[part 6 of 22: package /Cluster]
AUTOSAR XML (schema 4-3-0)
package /Cluster  (continued)
  can cluster E3V_K2CANFD: baudrate=500000, protocol-name=CAN, protocol-version=2.0, bus-off-recovery={bor-counter-l-1-to-l-2=1, bor-time-l-1=0.05, bor-time-l-2=0.2}, can-fd-baudrate=500000  (continued)
    can physical channel CHNL: comm-connectors=CN_E3V_K2CANFD  (continued)
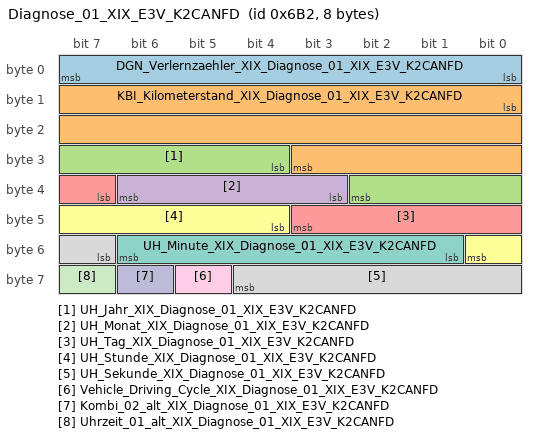
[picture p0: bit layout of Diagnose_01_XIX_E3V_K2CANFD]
      frame Diagnose_01_XIX_E3V_K2CANFD: id 0x6B2, to SAM, frame-length=8, can-addressing-mode=STANDARD, can-frame-rx-behavior=CAN-FD, can-frame-tx-behavior=CAN-FD
        pdu Diagnose_01_XIX_E3V_K2CANFD: length=8, transmission-mode-true-timing=cyclic-timing={time-offset=0.0, time-period=1.0}, unused-bit-pattern=0
          signal DGN_Verlernzaehler_XIX_Diagnose_01_XIX_E3V_K2CANFD: start 0, 8 bit, little-endian, data-type-policy=OVERRIDE, i-signal-type=PRIMITIVE, init-value=0, base-type=BT_DGN_Verlernzaehler, compu {phys=raw for raw 0..254, 255=Cxff_ungueltiger_Zaehlerstand_oder_kein_gueltiger_Fahrzyklus (CM_DGN_Verlernzaehler_Cxff_ungueltiger_Zaehlerstand_oder_kein_gueltiger_Fahrzyklus) (ungültiger Zählerstand oder kein gültiger Fahrzyklus)}, range phys 0..254, raw 0..255, transfer-property=PENDING, to SAM(timeout 5 s)  # wrap around 254 --> 0
          signal KBI_Kilometerstand_XIX_Diagnose_01_XIX_E3V_K2CANFD: start 8, 20 bit, little-endian, data-type-policy=OVERRIDE, i-signal-type=PRIMITIVE, init-value=1048574, base-type=BT_KBI_Kilometerstand, invalid-value=Invalid_KBI_Kilometerstand_XIX_Diagnose_01_XIX_E3V_K2CANFD:1048575, compu {phys=raw for raw 0..1048573, 1048574=Cxffffe_Init (CM_KBI_Kilometerstand_Cxffffe_Init), 1048575=Cxfffff_Fehler (CM_KBI_Kilometerstand_Cxfffff_Fehler); unit Unit_KiloMeter}, range phys 0..1048573 Unit_KiloMeter, raw 0..1048575, unit=Unit_KiloMeter, transfer-property=PENDING, to SAM(timeout 5 s)  # Fehler wird ausgegeben, falls Kilometerstand nicht restaurierbar
          signal UH_Jahr_XIX_Diagnose_01_XIX_E3V_K2CANFD: start 28, 7 bit, little-endian, data-type-policy=OVERRIDE, i-signal-type=PRIMITIVE, init-value=0, base-type=BT_UH_Jahr, compu {phys=raw+2000 for raw 0..127; unit Unit_Year}, range phys 2000..2127 Unit_Year, raw 0..127, unit=Unit_Year, transfer-property=PENDING, to SAM(timeout 5 s)
          signal UH_Monat_XIX_Diagnose_01_XIX_E3V_K2CANFD: start 35, 4 bit, little-endian, data-type-policy=OVERRIDE, i-signal-type=PRIMITIVE, init-value=0, base-type=BT_UH_Monat, invalid-value=Invalid_UH_Monat_XIX_Diagnose_01_XIX_E3V_K2CANFD:15, compu {0=Cx0_Init (CM_UH_Monat_Cx0_Init), phys=raw for raw 1..12, 14=Cxe_Relatives_Datum (CM_UH_Monat_Cxe_Relatives_Datum), 15=Cxf_Fehler (CM_UH_Monat_Cxf_Fehler); unit Unit_Month}, range phys 1..12 Unit_Month, raw 0..15, unit=Unit_Month, transfer-property=PENDING, to SAM(timeout 5 s)  # 0x0D, 0xF = Werte ungültig 0x0E = Relatives Datum (nur VW)
          signal UH_Tag_XIX_Diagnose_01_XIX_E3V_K2CANFD: start 39, 5 bit, little-endian, data-type-policy=OVERRIDE, i-signal-type=PRIMITIVE, init-value=0, base-type=BT_UH_Tag, compu {0=Cx0_Init (CM_UH_Tag_Cx0_Init), phys=raw for raw 1..31; unit Unit_Day}, range phys 1..31 Unit_Day, raw 0..31, unit=Unit_Day, transfer-property=PENDING, to SAM(timeout 5 s)  # 0x0: reserviert bei VW
          signal UH_Stunde_XIX_Diagnose_01_XIX_E3V_K2CANFD: start 44, 5 bit, little-endian, data-type-policy=OVERRIDE, i-signal-type=PRIMITIVE, init-value=0, base-type=BT_UH_Stunde, compu {phys=raw for raw 0..23; unit Unit_Hours}, range phys 0..23 Unit_Hours, raw 0..23, unit=Unit_Hours, transfer-property=PENDING, to SAM(timeout 5 s)  # 0x18 - 0x1F = Werte ungültig
          signal UH_Minute_XIX_Diagnose_01_XIX_E3V_K2CANFD: start 49, 6 bit, little-endian, data-type-policy=OVERRIDE, i-signal-type=PRIMITIVE, init-value=0, base-type=BT_UH_Minute, compu {phys=raw for raw 0..59; unit Unit_Minut}, range phys 0..59 Unit_Minut, raw 0..59, unit=Unit_Minut, transfer-property=PENDING, to SAM(timeout 5 s)  # 0x3C- 0x3f = Werte ungültig
          signal UH_Sekunde_XIX_Diagnose_01_XIX_E3V_K2CANFD: start 55, 6 bit, little-endian, data-type-policy=OVERRIDE, i-signal-type=PRIMITIVE, init-value=0, base-type=BT_UH_Sekunde, compu {phys=raw for raw 0..59; unit Unit_Secon}, range phys 0..59 Unit_Secon, raw 0..59, unit=Unit_Secon, transfer-property=PENDING, to SAM(timeout 5 s)  # 0x3C- 0x3f = Werte ungültig
          signal Vehicle_Driving_Cycle_XIX_Diagnose_01_XIX_E3V_K2CANFD: start 61, 1 bit, little-endian, data-type-policy=OVERRIDE, i-signal-type=PRIMITIVE, init-value=0, base-type=BT_Vehicle_Driving_Cycle, compu {0=Cx0_kein_Driving_Cycle_erkannt (CM_Vehicle_Driving_Cycle_Cx0_kein_Driving_Cycle_erkannt), 1=Cx1_Driving_Cycle_erkannt (CM_Vehicle_Driving_Cycle_Cx1_Driving_Cycle_erkannt)}, range raw 0..1, transfer-property=PENDING  # Optimierung der Inbetriebnahme von Steuergeräten in einem Teilverbau in der Produktion. Siehe VW80114. Signal bildet (durch eine Gateway-Funktion) den Inhalt des Signals OBD_Driving_Cycle ab.
          signal Kombi_02_alt_XIX_Diagnose_01_XIX_E3V_K2CANFD: start 62, 1 bit, little-endian, data-type-policy=OVERRIDE, i-signal-type=PRIMITIVE, init-value=1, base-type=BT_Kombi_02_alt, compu {0=Cx0_aktuell (CM_Kombi_02_alt_Cx0_aktuell), 1=Cx1_veraltet (CM_Kombi_02_alt_Cx1_veraltet)}, range raw 0..1, transfer-property=PENDING
          signal Uhrzeit_01_alt_XIX_Diagnose_01_XIX_E3V_K2CANFD: start 63, 1 bit, little-endian, data-type-policy=OVERRIDE, i-signal-type=PRIMITIVE, init-value=1, base-type=BT_Uhrzeit_01_alt, compu {0=Cx0_aktuell (CM_Uhrzeit_01_alt_Cx0_aktuell), 1=Cx1_veraltet (CM_Uhrzeit_01_alt_Cx1_veraltet)}, range raw 0..1, transfer-property=PENDING
      frame DiETa_01_XIX_E3V_K2CANFD: id 0x353, from SAM, frame-length=8, can-addressing-mode=STANDARD, can-frame-rx-behavior=CAN-FD, can-frame-tx-behavior=CAN-FD
        pdu DiETa_01_XIX_E3V_K2CANFD: length=8, transmission-mode-true-timing=cyclic-timing={time-offset=0.0, time-period=0.04}, unused-bit-pattern=0
          signal DiETas_01_CRC_XIX_DiETa_01_XIX_E3V_K2CANFD: start 0, 8 bit, little-endian, data-type-policy=OVERRIDE, i-signal-type=PRIMITIVE, base-type=BT_DiETas_01_CRC, compu {phys=raw for raw 0..255}, range phys 0..255, raw 0..255, transfer-property=PENDING  # Für MLB: Berechnung siehe Lastenheft "Kommunikationsabsicherung für FlexRay und CAN" Ab MQB und MLBevo: Berechnung siehe Lastenheft "End-to-End Kommunikationsabsicherung" Endwerte siehe Begleitdokument "S-PDU Kennungsfolgen"
          signal DiETas_01_BZ_XIX_DiETa_01_XIX_E3V_K2CANFD: start 8, 4 bit, little-endian, data-type-policy=OVERRIDE, i-signal-type=PRIMITIVE, base-type=BT_DiETas_01_BZ, compu {phys=raw for raw 0..15}, range phys 0..15, raw 0..15, transfer-property=PENDING  # 4bit Botschaftszähler, wird mit jeder Sendebotschaft inkrementiert
          signal DiETa_Reserve_Byte2_4_XIX_DiETa_01_XIX_E3V_K2CANFD: start 12, 1 bit, little-endian, data-type-policy=OVERRIDE, i-signal-type=PRIMITIVE, init-value=0, base-type=BT_DiETa_Reserve_Byte2_4, transfer-property=PENDING  # Vorhalt, Initialisierung mit '0'
          signal DiETa_Status_XIX_DiETa_01_XIX_E3V_K2CANFD: start 13, 2 bit, little-endian, data-type-policy=OVERRIDE, i-signal-type=PRIMITIVE, init-value=2, base-type=BT_DiETa_Status, compu {0=Cx0_DiETa_betriebsbereit (CM_DiETa_Status_Cx0_DiETa_betriebsbereit), 2=Cx2_Init (CM_DiETa_Status_Cx2_Init), 3=Cx3_Fehler_oder_defekt (CM_DiETa_Status_Cx3_Fehler_oder_defekt)}, range raw 0..3, transfer-property=PENDING  # Betriebszustand Direkteinstiegstasten
          signal DiETa_ResponseError_XIX_DiETa_01_XIX_E3V_K2CANFD: start 15, 1 bit, little-endian, data-type-policy=OVERRIDE, i-signal-type=PRIMITIVE, init-value=0, base-type=BT_DiETa_ResponseError, invalid-value=Invalid_DiETa_ResponseError_XIX_DiETa_01_XIX_E3V_K2CANFD:1, compu {0=Cx0_normal (CM_DiETa_ResponseError_Cx0_normal), 1=Cx1_Fehler (CM_DiETa_ResponseError_Cx1_Fehler)}, range raw 0..1, transfer-property=PENDING  # siehe LIN2.0-Specification (Darf nicht über ein Fehlergueltigkeitsbit abgesichtert werden!)
          signal DiETa_Car_XIX_DiETa_01_XIX_E3V_K2CANFD: start 16, 2 bit, little-endian, data-type-policy=OVERRIDE, i-signal-type=PRIMITIVE, init-value=0, base-type=BT_DiETa_Car, invalid-value=Invalid_DiETa_Car_XIX_DiETa_01_XIX_E3V_K2CANFD:3, compu {0=Cx0_Init_oder_nicht_verbaut (CM_DiETa_Car_Cx0_Init_oder_nicht_verbaut), 1=Cx1_Taste_unbetaetigt (CM_DiETa_Car_Cx1_Taste_unbetaetigt), 2=Cx2_Taste_betaetigt (CM_DiETa_Car_Cx2_Taste_betaetigt), 3=Cx3_Fehler (CM_DiETa_Car_Cx3_Fehler)}, range raw 0..3, transfer-property=PENDING  # Status Car-Taste
          signal DiETa_Klima_XIX_DiETa_01_XIX_E3V_K2CANFD: start 18, 2 bit, little-endian, data-type-policy=OVERRIDE, i-signal-type=PRIMITIVE, init-value=0, base-type=BT_DiETa_Klima, invalid-value=Invalid_DiETa_Klima_XIX_DiETa_01_XIX_E3V_K2CANFD:3, compu {0=Cx0_Init_oder_nicht_verbaut (CM_DiETa_Klima_Cx0_Init_oder_nicht_verbaut), 1=Cx1_Taste_unbetaetigt (CM_DiETa_Klima_Cx1_Taste_unbetaetigt), 2=Cx2_Taste_betaetigt (CM_DiETa_Klima_Cx2_Taste_betaetigt), 3=Cx3_Fehler (CM_DiETa_Klima_Cx3_Fehler)}, range raw 0..3, transfer-property=PENDING  # Status Klimataste
          signal DiETa_Mode_XIX_DiETa_01_XIX_E3V_K2CANFD: start 20, 2 bit, little-endian, data-type-policy=OVERRIDE, i-signal-type=PRIMITIVE, init-value=0, base-type=BT_DiETa_Mode, invalid-value=Invalid_DiETa_Mode_XIX_DiETa_01_XIX_E3V_K2CANFD:3, compu {0=Cx0_Init_oder_nicht_verbaut (CM_DiETa_Mode_Cx0_Init_oder_nicht_verbaut), 1=Cx1_Taste_unbetaetigt (CM_DiETa_Mode_Cx1_Taste_unbetaetigt), 2=Cx2_Taste_betaetigt (CM_DiETa_Mode_Cx2_Taste_betaetigt), 3=Cx3_Fehler (CM_DiETa_Mode_Cx3_Fehler)}, range raw 0..3, transfer-property=PENDING  # Status Modetaste
          signal DiETa_Parken_XIX_DiETa_01_XIX_E3V_K2CANFD: start 22, 2 bit, little-endian, data-type-policy=OVERRIDE, i-signal-type=PRIMITIVE, init-value=0, base-type=BT_DiETa_Parken, invalid-value=Invalid_DiETa_Parken_XIX_DiETa_01_XIX_E3V_K2CANFD:3, compu {0=Cx0_Init_oder_nicht_verbaut (CM_DiETa_Parken_Cx0_Init_oder_nicht_verbaut), 1=Cx1_Taste_unbetaetigt (CM_DiETa_Parken_Cx1_Taste_unbetaetigt), 2=Cx2_Taste_betaetigt (CM_DiETa_Parken_Cx2_Taste_betaetigt), 3=Cx3_Fehler (CM_DiETa_Parken_Cx3_Fehler)}, range raw 0..3, transfer-property=PENDING  # Status Parkentaste
          signal DiETa_FSH_Taste_XIX_DiETa_01_XIX_E3V_K2CANFD: start 24, 2 bit, little-endian, data-type-policy=OVERRIDE, i-signal-type=PRIMITIVE, init-value=0, base-type=BT_DiETa_FSH_Taste, invalid-value=Invalid_DiETa_FSH_Taste_XIX_DiETa_01_XIX_E3V_K2CANFD:3, compu {0=Cx0_Init_oder_nicht_verbaut (CM_DiETa_FSH_Taste_Cx0_Init_oder_nicht_verbaut), 1=Cx1_Taste_unbetaetigt (CM_DiETa_FSH_Taste_Cx1_Taste_unbetaetigt), 2=Cx2_Taste_betaetigt (CM_DiETa_FSH_Taste_Cx2_Taste_betaetigt), 3=Cx3_Fehler (CM_DiETa_FSH_Taste_Cx3_Fehler)}, range raw 0..3, transfer-property=PENDING  # Frontscheibenheizung AN/AUS
          signal DiETa_HSH_Taste_XIX_DiETa_01_XIX_E3V_K2CANFD: start 26, 2 bit, little-endian, data-type-policy=OVERRIDE, i-signal-type=PRIMITIVE, init-value=0, base-type=BT_DiETa_HSH_Taste, invalid-value=Invalid_DiETa_HSH_Taste_XIX_DiETa_01_XIX_E3V_K2CANFD:3, compu {0=Cx0_Init_oder_nicht_verbaut (CM_DiETa_HSH_Taste_Cx0_Init_oder_nicht_verbaut), 1=Cx1_Taste_unbetaetigt (CM_DiETa_HSH_Taste_Cx1_Taste_unbetaetigt), 2=Cx2_Taste_betaetigt (CM_DiETa_HSH_Taste_Cx2_Taste_betaetigt), 3=Cx3_Fehler (CM_DiETa_HSH_Taste_Cx3_Fehler)}, range raw 0..3, transfer-property=PENDING  # Heckscheibenheizung AN/AUS
          signal DiETa_Warnblink_Taste_XIX_DiETa_01_XIX_E3V_K2CANFD: start 28, 2 bit, little-endian, data-type-policy=OVERRIDE, i-signal-type=PRIMITIVE, init-value=0, base-type=BT_DiETa_Warnblink_Taste, invalid-value=Invalid_DiETa_Warnblink_Taste_XIX_DiETa_01_XIX_E3V_K2CANFD:3, compu {0=Cx0_Init_oder_nicht_verbaut (CM_DiETa_Warnblink_Taste_Cx0_Init_oder_nicht_verbaut), 1=Cx1_Taste_unbetaetigt (CM_DiETa_Warnblink_Taste_Cx1_Taste_unbetaetigt), 2=Cx2_Taste_betaetigt (CM_DiETa_Warnblink_Taste_Cx2_Taste_betaetigt), 3=Cx3_Fehler (CM_DiETa_Warnblink_Taste_Cx3_Fehler)}, range raw 0..3, transfer-property=PENDING  # Status Warnblinktaster
          signal DiETa_FAS_Stufe_XIX_DiETa_01_XIX_E3V_K2CANFD: start 30, 2 bit, little-endian, data-type-policy=OVERRIDE, i-signal-type=PRIMITIVE, init-value=0, base-type=BT_DiETa_FAS_Stufe, invalid-value=Invalid_DiETa_FAS_Stufe_XIX_DiETa_01_XIX_E3V_K2CANFD:3, compu {0=Cx0_Init_oder_nicht_verbaut (CM_DiETa_FAS_Stufe_Cx0_Init_oder_nicht_verbaut), 1=Cx1_Taste_unbetaetigt (CM_DiETa_FAS_Stufe_Cx1_Taste_unbetaetigt), 2=Cx2_Taste_betaetigt (CM_DiETa_FAS_Stufe_Cx2_Taste_betaetigt), 3=Cx3_Fehler (CM_DiETa_FAS_Stufe_Cx3_Fehler)}, range raw 0..3, transfer-property=PENDING  # Status FAS-Taste
          signal DiETa_PAO_ON_Status_XIX_DiETa_01_XIX_E3V_K2CANFD: start 32, 2 bit, little-endian, data-type-policy=OVERRIDE, i-signal-type=PRIMITIVE, init-value=0, base-type=BT_DiETa_PAO_ON_Status, compu {0=Cx0_LED_Aus (CM_DiETa_PAO_ON_Status_Cx0_LED_Aus), 1=Cx1_LED_Ein (CM_DiETa_PAO_ON_Status_Cx1_LED_Ein), 2=Cx2_LED_Blinkt (CM_DiETa_PAO_ON_Status_Cx2_LED_Blinkt), 3=Cx3_LED_defekt (CM_DiETa_PAO_ON_Status_Cx3_LED_defekt)}, range raw 0..3, transfer-property=PENDING  # Istwert für LED "ON" in Anzeige Passenger Airbag On/Off
          signal DiETa_PAO_OFF_Status_XIX_DiETa_01_XIX_E3V_K2CANFD: start 34, 2 bit, little-endian, data-type-policy=OVERRIDE, i-signal-type=PRIMITIVE, init-value=0, base-type=BT_DiETa_PAO_OFF_Status, compu {0=Cx0_LED_Aus (CM_DiETa_PAO_OFF_Status_Cx0_LED_Aus), 1=Cx1_LED_Ein (CM_DiETa_PAO_OFF_Status_Cx1_LED_Ein), 2=Cx2_LED_Blinkt (CM_DiETa_PAO_OFF_Status_Cx2_LED_Blinkt), 3=Cx3_LED_defekt (CM_DiETa_PAO_OFF_Status_Cx3_LED_defekt)}, range raw 0..3, transfer-property=PENDING  # Istwert für LED "OFF" in Anzeige Passenger Airbag On/Off
          signal DiETa_Defrost_Taste_XIX_DiETa_01_XIX_E3V_K2CANFD: start 36, 2 bit, little-endian, data-type-policy=OVERRIDE, i-signal-type=PRIMITIVE, init-value=0, base-type=BT_DiETa_Defrost_Taste, invalid-value=Invalid_DiETa_Defrost_Taste_XIX_DiETa_01_XIX_E3V_K2CANFD:3, compu {0=Cx0_Init_oder_nicht_verbaut (CM_DiETa_Defrost_Taste_Cx0_Init_oder_nicht_verbaut), 1=Cx1_Taste_unbetaetigt (CM_DiETa_Defrost_Taste_Cx1_Taste_unbetaetigt), 2=Cx2_Taste_betaetigt (CM_DiETa_Defrost_Taste_Cx2_Taste_betaetigt), 3=Cx3_Fehler (CM_DiETa_Defrost_Taste_Cx3_Fehler)}, range raw 0..3, transfer-property=PENDING  # Max. Defrost AN/AUS
          signal DiETa_Mode2_XIX_DiETa_01_XIX_E3V_K2CANFD: start 38, 2 bit, little-endian, data-type-policy=OVERRIDE, i-signal-type=PRIMITIVE, init-value=0, base-type=BT_DiETa_Mode2, invalid-value=Invalid_DiETa_Mode2_XIX_DiETa_01_XIX_E3V_K2CANFD:3, compu {0=Cx0_Init_oder_nicht_verbaut (CM_DiETa_Mode2_Cx0_Init_oder_nicht_verbaut), 1=Cx1_Taste_unbetaetigt (CM_DiETa_Mode2_Cx1_Taste_unbetaetigt), 2=Cx2_Taste_betaetigt (CM_DiETa_Mode2_Cx2_Taste_betaetigt), 3=Cx3_Fehler (CM_DiETa_Mode2_Cx3_Fehler)}, range raw 0..3, transfer-property=PENDING  # Status Mode2taste (GTE-Taster im VW380 PHEV)
          signal DiETa_Lock_Unlock_Taste_XIX_DiETa_01_XIX_E3V_K2CANFD: start 40, 3 bit, little-endian, data-type-policy=OVERRIDE, i-signal-type=PRIMITIVE, init-value=0, base-type=BT_DiETa_Lock_Unlock_Taste, invalid-value=Invalid_DiETa_Lock_Unlock_Taste_XIX_DiETa_01_XIX_E3V_K2CANFD:7, compu {0=Cx0_Init (CM_DiETa_Lock_Unlock_Taste_Cx0_Init), 1=Cx1_Taste_unbetaetigt (CM_DiETa_Lock_Unlock_Taste_Cx1_Taste_unbetaetigt), 2=Cx2_Taste_betaetigt_unlock (CM_DiETa_Lock_Unlock_Taste_Cx2_Taste_betaetigt_unlock), 3=Cx3_Taste_betaetigt_lock (CM_DiETa_Lock_Unlock_Taste_Cx3_Taste_betaetigt_lock), 4=Cx4_Reserviert (CM_DiETa_Lock_Unlock_Taste_Cx4_Reserviert), 5=Cx5_Reserviert (CM_DiETa_Lock_Unlock_Taste_Cx5_Reserviert), 6=Cx6_Reserviert (CM_DiETa_Lock_Unlock_Taste_Cx6_Reserviert), 7=Cx7_Fehler (CM_DiETa_Lock_Unlock_Taste_Cx7_Fehler)}, range raw 0..7, transfer-property=PENDING  # Lock-/Unlock-Taste
          signal DiETa_Mode_roh_XIX_DiETa_01_XIX_E3V_K2CANFD: start 43, 1 bit, little-endian, data-type-policy=OVERRIDE, i-signal-type=PRIMITIVE, init-value=0, base-type=BT_DiETa_Mode_roh, compu {0=Cx0_Taste_unbetaetigt (CM_DiETa_Mode_roh_Cx0_Taste_unbetaetigt), 1=Cx1_Taste_betaetigt (CM_DiETa_Mode_roh_Cx1_Taste_betaetigt)}, range raw 0..1, transfer-property=PENDING  # Erweitertes SIgnal zur Erfüllung der OBD-Relevanz für die Funktion Mode auf der DiETa
          signal ESP_Off_Taster_XIX_DiETa_01_XIX_E3V_K2CANFD: start 44, 2 bit, little-endian, data-type-policy=OVERRIDE, i-signal-type=PRIMITIVE, init-value=2, base-type=BT_ESP_Off_Taster, invalid-value=Invalid_ESP_Off_Taster_XIX_DiETa_01_XIX_E3V_K2CANFD:3, compu {0=Cx0_Taste_nicht_betaetigt (CM_ESP_Off_Taster_Cx0_Taste_nicht_betaetigt), 1=Cx1_Taste_entprellt_betaetigt (CM_ESP_Off_Taster_Cx1_Taste_entprellt_betaetigt), 2=Cx2_Init_oder_nicht_verbaut (CM_ESP_Off_Taster_Cx2_Init_oder_nicht_verbaut), 3=Cx3_Fehler (CM_ESP_Off_Taster_Cx3_Fehler)}, range raw 0..3, transfer-property=PENDING  # Das Signal beschreibt den Zustand der ESP Taste, die im MLBevo vom BCM1 eingelesen wird.
          signal DiETa_Reserve_Byte6_6_XIX_DiETa_01_XIX_E3V_K2CANFD: start 46, 2 bit, little-endian, data-type-policy=OVERRIDE, i-signal-type=PRIMITIVE, init-value=0, base-type=BT_DiETa_Reserve_Byte6_6, transfer-property=PENDING  # Vorhalt, Initialisierung mit '0'
          signal DiETa_Touch_Event_XIX_DiETa_01_XIX_E3V_K2CANFD: start 48, 4 bit, little-endian, data-type-policy=OVERRIDE, i-signal-type=PRIMITIVE, init-value=0, base-type=BT_DiETa_Touch_Event, invalid-value=Invalid_DiETa_Touch_Event_XIX_DiETa_01_XIX_E3V_K2CANFD:15, compu {0=Cx0_nicht_betaetigt (CM_DiETa_Touch_Event_Cx0_nicht_betaetigt), 1=Cx1_Tippen (CM_DiETa_Touch_Event_Cx1_Tippen), 2=Cx2_Wischen_Slide (CM_DiETa_Touch_Event_Cx2_Wischen_Slide), 3=Cx3_Geste (CM_DiETa_Touch_Event_Cx3_Geste), 4=Cx4_Doppeltippen (CM_DiETa_Touch_Event_Cx4_Doppeltippen), 5=Cx5_Longpress_1 (CM_DiETa_Touch_Event_Cx5_Longpress_1), 6=Cx6_Longpress_2 (CM_DiETa_Touch_Event_Cx6_Longpress_2), 7=Cx7_Longpress_3 (CM_DiETa_Touch_Event_Cx7_Longpress_3), 8=Cx8_Press (CM_DiETa_Touch_Event_Cx8_Press), 9=Cx9_Strongpress (CM_DiETa_Touch_Event_Cx9_Strongpress), 10=Cxa_reserviert (CM_DiETa_Touch_Event_Cxa_reserviert), 11=Cxb_reserviert (CM_DiETa_Touch_Event_Cxb_reserviert), 12=Cxc_reserviert (CM_DiETa_Touch_Event_Cxc_reserviert), 13=Cxd_reserviert (CM_DiETa_Touch_Event_Cxd_reserviert), 14=Cxe_Taktgeber_Inkrement (CM_DiETa_Touch_Event_Cxe_Taktgeber_Inkrement), 15=Cxf_Fehler (CM_DiETa_Touch_Event_Cxf_Fehler)}, range raw 0..15, transfer-property=PENDING  # Touch_Events für Informationen einer Funktionsauslösung auf DiETa, welches dann für bspw. ein akustisches Signal zentral umgesetzt werden können.
          signal DiETa_Reserve_Byte7_4_XIX_DiETa_01_XIX_E3V_K2CANFD: start 52, 4 bit, little-endian, data-type-policy=OVERRIDE, i-signal-type=PRIMITIVE, init-value=0, base-type=BT_DiETa_Reserve_Byte7_4, transfer-property=PENDING  # Vorhalt, Initialisierung mit '0'
          signal DiETa_Reserve_Byte8_XIX_DiETa_01_XIX_E3V_K2CANFD: start 56, 8 bit, little-endian, data-type-policy=OVERRIDE, i-signal-type=PRIMITIVE, init-value=0, base-type=BT_DiETa_Reserve_Byte8, transfer-property=PENDING  # Vorhalt, Initialisierung mit '0'
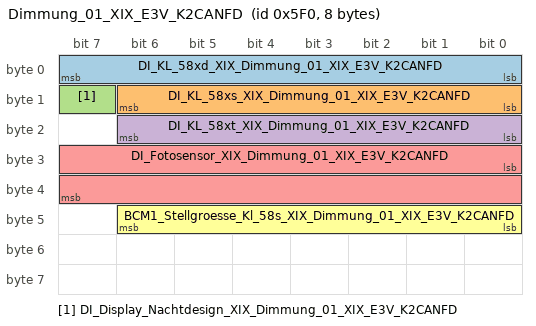
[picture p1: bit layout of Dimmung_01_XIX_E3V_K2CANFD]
      frame Dimmung_01_XIX_E3V_K2CANFD: id 0x5F0, to SAM, frame-length=8, can-addressing-mode=STANDARD, can-frame-rx-behavior=CAN-FD, can-frame-tx-behavior=CAN-FD
        pdu Dimmung_01_XIX_E3V_K2CANFD: length=8, minimum-delay=0.05, transmission-mode-true-timing={cyclic-timing={time-offset=0.0, time-period=0.2}, event-controlled-timing={number-of-repetitions=0, repetition-period=0.0}}, unused-bit-pattern=0  # ab MQB nach abgestimmten FLH Dimmung
          signal DI_KL_58xd_XIX_Dimmung_01_XIX_E3V_K2CANFD: start 0, 8 bit, little-endian, data-type-policy=OVERRIDE, i-signal-type=PRIMITIVE, init-value=254, base-type=BT_DI_KL_58xd, invalid-value=Invalid_DI_KL_58xd_XIX_Dimmung_01_XIX_E3V_K2CANFD:255, compu {phys=raw for raw 0..253, 254=Cxfe_Init (CM_DI_KL_58xd_Cxfe_Init), 255=Cxff_Fehler (CM_DI_KL_58xd_Cxff_Fehler)}, range phys 0..253, raw 0..255, transfer-property=TRIGGERED-ON-CHANGE-WITHOUT-REPETITION, to SAM(timeout 2 s)  # Klemme 58xd Display- und Funktionsbeleuchtung Mit der Klemme 58xd wird die Helligkeit der Display- und der Funktionsbeleuchtungen der Schalter gesteuert. Im Detail beschrieben im 'Funktionslastenheft Dimmung MQB'.
          signal DI_KL_58xs_XIX_Dimmung_01_XIX_E3V_K2CANFD: start 8, 7 bit, little-endian, data-type-policy=OVERRIDE, i-signal-type=PRIMITIVE, init-value=126, base-type=BT_DI_KL_58xs, invalid-value=Invalid_DI_KL_58xs_XIX_Dimmung_01_XIX_E3V_K2CANFD:127, compu {phys=raw for raw 0..100, 126=Cx7e_Init (CM_DI_KL_58xs_Cx7e_Init), 127=Cx7f_Fehler (CM_DI_KL_58xs_Cx7f_Fehler); unit Unit_PerCent}, range phys 0..100 Unit_PerCent, raw 0..127, unit=Unit_PerCent, transfer-property=TRIGGERED-ON-CHANGE-WITHOUT-REPETITION, to SAM(timeout 2 s)  # Suchbeleuchtung Schalter EIN-AUS-Schaltalgorithmus der allgemeinen Schaltersuchbeleuchtung. Im Detail beschrieben im 'Funktionslastenheft Dimmung MQB'.
          signal DI_Display_Nachtdesign_XIX_Dimmung_01_XIX_E3V_K2CANFD: start 15, 1 bit, little-endian, data-type-policy=OVERRIDE, i-signal-type=PRIMITIVE, init-value=0, base-type=BT_DI_Display_Nachtdesign, transfer-property=TRIGGERED-ON-CHANGE-WITHOUT-REPETITION  # Für Displays sind oft automatische Umschaltungen von Tag-/Nachtdesign vorgesehen. Es gibt jedoch Zustände, an denen auch tagsüber das Abblendlicht eingeschaltet ist. z.B. Dauerfahrlicht, Geschwindigkeitsabhängiges "Licht-An-Bei-Autobahn", "Regenlicht", etc. Die Aufgabe des Signals s_Display_Nachtdesign ist es, Fehlumschaltungen zu vermeiden. Es ist im Dimm-Master zu implementieren. Im Detail beschrieben im 'Funktionslastenheft Dimmung MQB'.
          signal DI_KL_58xt_XIX_Dimmung_01_XIX_E3V_K2CANFD: start 16, 7 bit, little-endian, data-type-policy=OVERRIDE, i-signal-type=PRIMITIVE, init-value=126, base-type=BT_DI_KL_58xt, invalid-value=Invalid_DI_KL_58xt_XIX_Dimmung_01_XIX_E3V_K2CANFD:127, compu {phys=raw for raw 0..100, 126=Cx7e_Init (CM_DI_KL_58xt_Cx7e_Init), 127=Cx7f_Fehler (CM_DI_KL_58xt_Cx7f_Fehler); unit Unit_PerCent}, range phys 0..100 Unit_PerCent, raw 0..127, unit=Unit_PerCent, transfer-property=TRIGGERED-ON-CHANGE-WITHOUT-REPETITION, to SAM(timeout 2 s)  # Timergesteuerte Suchbeleuchtung Der EIN-AUS-Schaltalgorithmus für die vor- und nachlaufende Schaltersuchbeleuchtungen beim Ein- & Aussteigen; z.B.: Start/Stop-Taster. Im Detail beschrieben im 'Funktionslastenheft Dimmung MQB'.
          signal DI_Fotosensor_XIX_Dimmung_01_XIX_E3V_K2CANFD: start 24, 16 bit, little-endian, data-type-policy=OVERRIDE, i-signal-type=PRIMITIVE, init-value=0, base-type=BT_DI_Fotosensor, compu {phys=raw for raw 0..65535}, range phys 0..65535, raw 0..65535, transfer-property=TRIGGERED-ON-CHANGE-WITHOUT-REPETITION  # Helligkeitswert Fotosensor Für die Dimmung relevanter Wert zur Sensierung der Umgebungshelligkeit Im Detail beschrieben im 'Funktionslastenheft Dimmung MQB'.
          signal BCM1_Stellgroesse_Kl_58s_XIX_Dimmung_01_XIX_E3V_K2CANFD: start 40, 7 bit, little-endian, data-type-policy=OVERRIDE, i-signal-type=PRIMITIVE, init-value=126, base-type=BT_BCM1_Stellgroesse_Kl_58s, invalid-value=Invalid_BCM1_Stellgroesse_Kl_58s_XIX_Dimmung_01_XIX_E3V_K2CANFD:127, compu {phys=raw for raw 0..100, 125=Cx7d_Nicht_verbaut (CM_BCM1_Stellgroesse_Kl_58s_Cx7d_Nicht_verbaut), 126=Cx7e_Init (CM_BCM1_Stellgroesse_Kl_58s_Cx7e_Init), 127=Cx7f_Fehler (CM_BCM1_Stellgroesse_Kl_58s_Cx7f_Fehler)}, range phys 0..100, raw 0..127, transfer-property=TRIGGERED-ON-CHANGE-WITHOUT-REPETITION  # Rohwert Dimmpoti
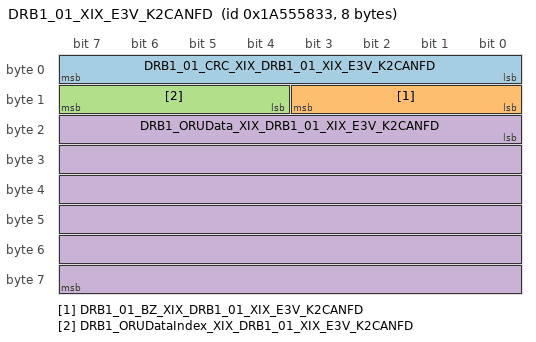
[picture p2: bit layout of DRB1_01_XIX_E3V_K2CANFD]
      frame DRB1_01_XIX_E3V_K2CANFD: id 0x1A555833, to SAM, frame-length=8, can-addressing-mode=EXTENDED, can-frame-rx-behavior=CAN-FD, can-frame-tx-behavior=CAN-FD
        pdu DRB1_01_XIX_E3V_K2CANFD_E2E: length=8, transmission-mode-true-timing=event-controlled-timing={number-of-repetitions=0, repetition-period=0.0}, unused-bit-pattern=0  # Fuer die Botschaft ist das Cyclic-Timing 0.5 zu verwenden.
          signal DRB1_01_CRC_XIX_DRB1_01_XIX_E3V_K2CANFD: start 0, 8 bit, little-endian, data-type-policy=OVERRIDE, i-signal-type=PRIMITIVE, init-value=0, base-type=BT_DRB1_01_CRC, compu {phys=raw for raw 0..255}, range phys 0..255, raw 0..255, to SAM(timeout 5 s)  # Für MLB: Berechnung siehe Lastenheft "Kommunikationsabsicherung für FlexRay und CAN" Ab MQB und MLBevo: Berechnung siehe Lastenheft "End-to-End Kommunikationsabsicherung" Endwerte siehe Begleitdokument "S-PDU Kennungsfolgen"
          signal DRB1_01_BZ_XIX_DRB1_01_XIX_E3V_K2CANFD: start 8, 4 bit, little-endian, data-type-policy=OVERRIDE, i-signal-type=PRIMITIVE, init-value=0, base-type=BT_DRB1_01_BZ, compu {phys=raw for raw 0..15}, range phys 0..15, raw 0..15, to SAM(timeout 5 s)
          signal DRB1_ORUDataIndex_XIX_DRB1_01_XIX_E3V_K2CANFD: start 12, 4 bit, little-endian, data-type-policy=OVERRIDE, i-signal-type=PRIMITIVE, init-value=0, base-type=BT_DRB1_ORUDataIndex, compu {phys=raw for raw 0..15}, range phys 0..15, raw 0..15, to SAM(timeout 5 s)  # Data index of the last 6 Bytes
          signal DRB1_ORUData_XIX_DRB1_01_XIX_E3V_K2CANFD: start 16, 48 bit, little-endian, data-type-policy=OVERRIDE, i-signal-type=PRIMITIVE, init-value=0, base-type=BT_DRB1_ORUData, compu {phys=raw for raw 0..281474976710655}, range phys 0..281474976710655, raw 0..281474976710655, to SAM(timeout 5 s)  # "ORU information multiplexed - diagnostic address (2 bytes) - HW-part no (11 bytes) - HW version no. (3 bytes) - SW version no. (4 bytes) - IVD-P Value (64 bytes) need to be sent in combination with ORUDataIndex"
          mapping SG_DRB1_01_XIX_E3V_K2CANFD: i-signal-group=SG_DRB1_01_XIX_E3V_K2CANFD, transfer-property=TRIGGERED-WITHOUT-REPETITION
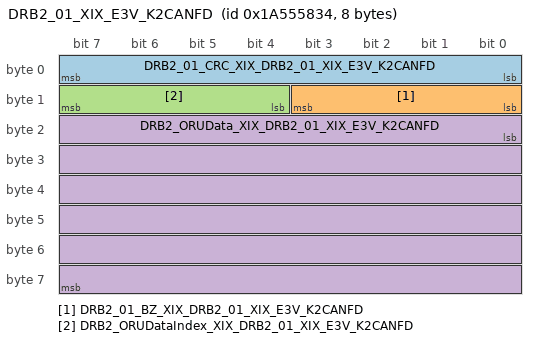
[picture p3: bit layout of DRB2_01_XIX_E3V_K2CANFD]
      frame DRB2_01_XIX_E3V_K2CANFD: id 0x1A555834, to SAM, frame-length=8, can-addressing-mode=EXTENDED, can-frame-rx-behavior=CAN-FD, can-frame-tx-behavior=CAN-FD
        pdu DRB2_01_XIX_E3V_K2CANFD_E2E: length=8, transmission-mode-true-timing=event-controlled-timing={number-of-repetitions=0, repetition-period=0.0}, unused-bit-pattern=0  # Fuer die Botschaft ist das Cyclic-Timing 0.5 zu verwenden.
          signal DRB2_01_CRC_XIX_DRB2_01_XIX_E3V_K2CANFD: start 0, 8 bit, little-endian, data-type-policy=OVERRIDE, i-signal-type=PRIMITIVE, init-value=0, base-type=BT_DRB2_01_CRC, compu {phys=raw for raw 0..255}, range phys 0..255, raw 0..255, to SAM(timeout 5 s)  # Für MLB: Berechnung siehe Lastenheft "Kommunikationsabsicherung für FlexRay und CAN" Ab MQB und MLBevo: Berechnung siehe Lastenheft "End-to-End Kommunikationsabsicherung" Endwerte siehe Begleitdokument "S-PDU Kennungsfolgen"
          signal DRB2_01_BZ_XIX_DRB2_01_XIX_E3V_K2CANFD: start 8, 4 bit, little-endian, data-type-policy=OVERRIDE, i-signal-type=PRIMITIVE, init-value=0, base-type=BT_DRB2_01_BZ, compu {phys=raw for raw 0..15}, range phys 0..15, raw 0..15, to SAM(timeout 5 s)
          signal DRB2_ORUDataIndex_XIX_DRB2_01_XIX_E3V_K2CANFD: start 12, 4 bit, little-endian, data-type-policy=OVERRIDE, i-signal-type=PRIMITIVE, init-value=0, base-type=BT_DRB2_ORUDataIndex, compu {phys=raw for raw 0..15}, range phys 0..15, raw 0..15, to SAM(timeout 5 s)  # Data index of the last 6 Bytes
          signal DRB2_ORUData_XIX_DRB2_01_XIX_E3V_K2CANFD: start 16, 48 bit, little-endian, data-type-policy=OVERRIDE, i-signal-type=PRIMITIVE, init-value=0, base-type=BT_DRB2_ORUData, compu {phys=raw for raw 0..281474976710655}, range phys 0..281474976710655, raw 0..281474976710655, to SAM(timeout 5 s)  # "ORU information multiplexed - diagnostic address (2 bytes) - HW-part no (11 bytes) - HW version no. (3 bytes) - SW version no. (4 bytes) - IVD-P Value (64 bytes) need to be sent in combination with ORUDataIndex"
          mapping SG_DRB2_01_XIX_E3V_K2CANFD: i-signal-group=SG_DRB2_01_XIX_E3V_K2CANFD, transfer-property=TRIGGERED-WITHOUT-REPETITION
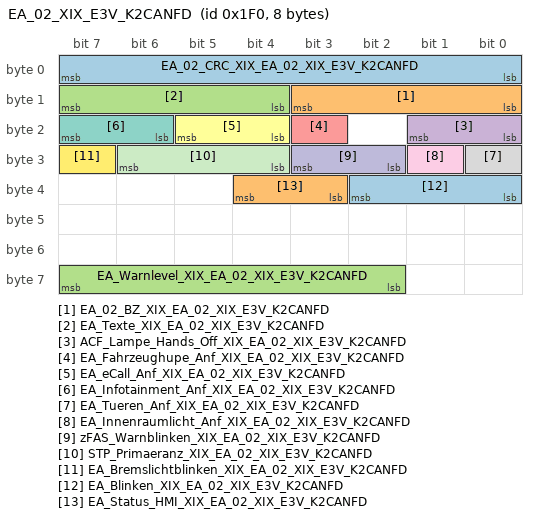
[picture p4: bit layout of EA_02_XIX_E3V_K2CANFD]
      frame EA_02_XIX_E3V_K2CANFD: id 0x1F0, to SAM, frame-length=8, can-addressing-mode=STANDARD, can-frame-rx-behavior=CAN-FD, can-frame-tx-behavior=CAN-FD
        pdu EA_02_XIX_E3V_K2CANFD: length=8, minimum-delay=0.02, transmission-mode-true-timing={cyclic-timing={time-offset=0.0, time-period=0.5}, event-controlled-timing={number-of-repetitions=0, repetition-period=0.0}}, unused-bit-pattern=0
          signal EA_02_CRC_XIX_EA_02_XIX_E3V_K2CANFD: start 0, 8 bit, little-endian, data-type-policy=OVERRIDE, i-signal-type=PRIMITIVE, base-type=BT_EA_02_CRC, compu {phys=raw for raw 0..255}, range phys 0..255, raw 0..255, transfer-property=PENDING  # Für MLB: "Berechnung siehe Lastenheft "Kommunikationsabsicherung für Flexray und CAN"" Ab MQB und MLBevo: "Berechnung siehe Lastenheft "End-to-End Kommunikationsabsicherung" Endwerte siehe Begleitdokument "S-PDU Kennungsfolge"
          signal EA_02_BZ_XIX_EA_02_XIX_E3V_K2CANFD: start 8, 4 bit, little-endian, data-type-policy=OVERRIDE, i-signal-type=PRIMITIVE, base-type=BT_EA_02_BZ, compu {phys=raw for raw 0..15}, range phys 0..15, raw 0..15, transfer-property=PENDING  # Botschaftszähler
          signal EA_Texte_XIX_EA_02_XIX_E3V_K2CANFD: start 12, 4 bit, little-endian, data-type-policy=OVERRIDE, i-signal-type=PRIMITIVE, init-value=0, base-type=BT_EA_Texte, compu {0=Cx0_keine_Anzeige (CM_EA_Texte_Cx0_keine_Anzeige), 1=Cx1_Nothalteassistent_fehlende_Fahreraktivitaet (CM_EA_Texte_Cx1_Nothalteassistent_fehlende_Fahreraktivitaet), 2=Cx2_Nothalteassistent_aktiv_Fahrzeugfuehrung_uebernehmen (CM_EA_Texte_Cx2_Nothalteassistent_aktiv_Fahrzeugfuehrung_uebernehmen), 3=Cx3_Nothalteassistent_automatischer_Nothalt_wird_durchgefuehrt (CM_EA_Texte_Cx3_Nothalteassistent_automatischer_Nothalt_wird_durchgefuehrt), 4=Cx4_Nothalteassistent_automatischer_Nothalt_durchgefuehrt (CM_EA_Texte_Cx4_Nothalteassistent_automatischer_Nothalt_durchgefuehrt), 5=Cx5_Nothalteassistent_Verbindung_zum_Notruf_wird_aufgebaut (CM_EA_Texte_Cx5_Nothalteassistent_Verbindung_zum_Notruf_wird_aufgebaut), 6=Cx6_Nothalteassistent_deaktiviert (CM_EA_Texte_Cx6_Nothalteassistent_deaktiviert), 7=Cx7_Nothalteassistent_Eingriff_abgebrochen (CM_EA_Texte_Cx7_Nothalteassistent_Eingriff_abgebrochen), 8=Cx8_Nothalteassistent_fehlende_Fahreraktivitaet_2 (CM_EA_Texte_Cx8_Nothalteassistent_fehlende_Fahreraktivitaet_2), 9=Cx9_Sekundenschlaf_erkannt (CM_EA_Texte_Cx9_Sekundenschlaf_erkannt), 10=Cxa_LaneAssist_Lenkung_uebernehmen (CM_EA_Texte_Cxa_LaneAssist_Lenkung_uebernehmen), 11=Cxb_ACA_Fahrzeugfuehrung_uebernehmen (CM_EA_Texte_Cxb_ACA_Fahrzeugfuehrung_uebernehmen), 12=Cxc_EA_Fahr_Standstreifenwechsel (CM_EA_Texte_Cxc_EA_Fahr_Standstreifenwechsel), 13=Cxd_EA_eingeschraenkt_verfuegbar (CM_EA_Texte_Cxd_EA_eingeschraenkt_verfuegbar), 14=Cxe_Nothalteassistent_nicht_verfuegbar_reversibel (CM_EA_Texte_Cxe_Nothalteassistent_nicht_verfuegbar_reversibel), 15=Cxf_Nothalteassistent_Stoerung_irreversibel (CM_EA_Texte_Cxf_Nothalteassistent_Stoerung_irreversibel)}, range raw 0..15, transfer-property=TRIGGERED-ON-CHANGE-WITHOUT-REPETITION  # Anzeige der EA Texte
          signal ACF_Lampe_Hands_Off_XIX_EA_02_XIX_E3V_K2CANFD: start 16, 2 bit, little-endian, data-type-policy=OVERRIDE, i-signal-type=PRIMITIVE, init-value=0, base-type=BT_ACF_Lampe_Hands_Off, compu {0=Cx0_keine_Anzeige (CM_ACF_Lampe_Hands_Off_Cx0_keine_Anzeige), 1=Cx1_Hands_Off_erkannt (CM_ACF_Lampe_Hands_Off_Cx1_Hands_Off_erkannt)}, range raw 0..1, transfer-property=TRIGGERED-ON-CHANGE-WITHOUT-REPETITION  # Anzeige, ob der Fahrer die Hände am Lenkrad hat.
          signal EA_Fahrzeughupe_Anf_XIX_EA_02_XIX_E3V_K2CANFD: start 19, 1 bit, little-endian, data-type-policy=OVERRIDE, i-signal-type=PRIMITIVE, init-value=0, base-type=BT_EA_Fahrzeughupe_Anf, compu {0=Cx0_keine_Anforderung (CM_EA_Fahrzeughupe_Anf_Cx0_keine_Anforderung), 1=Cx1_Anforderung_Fahrzeughupe (CM_EA_Fahrzeughupe_Anf_Cx1_Anforderung_Fahrzeughupe)}, range raw 0..1, transfer-property=TRIGGERED-ON-CHANGE-WITHOUT-REPETITION, to SAM(timeout 5 s)  # Emergency Assist Anforderung Fahrzeughupe
          signal EA_eCall_Anf_XIX_EA_02_XIX_E3V_K2CANFD: start 20, 2 bit, little-endian, data-type-policy=OVERRIDE, i-signal-type=PRIMITIVE, init-value=0, base-type=BT_EA_eCall_Anf, compu {0=Cx0_Keine_Anforderung (CM_EA_eCall_Anf_Cx0_Keine_Anforderung), 1=Cx1_Ausloesen_eCall (CM_EA_eCall_Anf_Cx1_Ausloesen_eCall)}, range raw 0..1, transfer-property=TRIGGERED-ON-CHANGE-WITHOUT-REPETITION  # Emergency Assist Anforderung eCall
          signal EA_Infotainment_Anf_XIX_EA_02_XIX_E3V_K2CANFD: start 22, 2 bit, little-endian, data-type-policy=OVERRIDE, i-signal-type=PRIMITIVE, init-value=0, base-type=BT_EA_Infotainment_Anf, compu {0=Cx0_Init (CM_EA_Infotainment_Anf_Cx0_Init), 1=Cx1_Keine_Absenkung (CM_EA_Infotainment_Anf_Cx1_Keine_Absenkung), 2=Cx2_Absenkung (CM_EA_Infotainment_Anf_Cx2_Absenkung), 3=Cx3_Mute (CM_EA_Infotainment_Anf_Cx3_Mute)}, range raw 0..3, transfer-property=TRIGGERED-ON-CHANGE-WITHOUT-REPETITION  # Emergency Assist Anforderung Absenkung Infotainment-Funktionen
          signal EA_Tueren_Anf_XIX_EA_02_XIX_E3V_K2CANFD: start 24, 1 bit, little-endian, data-type-policy=OVERRIDE, i-signal-type=PRIMITIVE, init-value=0, base-type=BT_EA_Tueren_Anf, compu {0=Cx0_Keine_Anforderung (CM_EA_Tueren_Anf_Cx0_Keine_Anforderung), 1=Cx1_Tueren_entriegeln (CM_EA_Tueren_Anf_Cx1_Tueren_entriegeln)}, range raw 0..1, transfer-property=TRIGGERED-ON-CHANGE-WITHOUT-REPETITION  # Emergency Assist Anforderung Türen entriegeln
          signal EA_Innenraumlicht_Anf_XIX_EA_02_XIX_E3V_K2CANFD: start 25, 1 bit, little-endian, data-type-policy=OVERRIDE, i-signal-type=PRIMITIVE, init-value=0, base-type=BT_EA_Innenraumlicht_Anf, compu {0=Cx0_Innenraumbeleuchtung_ausschalten (CM_EA_Innenraumlicht_Anf_Cx0_Innenraumbeleuchtung_ausschalten), 1=Cx1_Innenraumbeleuchtung_einschalten (CM_EA_Innenraumlicht_Anf_Cx1_Innenraumbeleuchtung_einschalten)}, range raw 0..1, transfer-property=TRIGGERED-ON-CHANGE-WITHOUT-REPETITION, to SAM(timeout 5 s)  # Anforderung Innenraumbeleuchtung durch den Emergency Assist
          signal zFAS_Warnblinken_XIX_EA_02_XIX_E3V_K2CANFD: start 26, 2 bit, little-endian, data-type-policy=OVERRIDE, i-signal-type=PRIMITIVE, init-value=0, base-type=BT_zFAS_Warnblinken, compu {0=Cx0_Aus (CM_zFAS_Warnblinken_Cx0_Aus), 1=Cx1_Statisch (CM_zFAS_Warnblinken_Cx1_Statisch), 2=Cx2_Taster (CM_zFAS_Warnblinken_Cx2_Taster), 3=Cx3_Statisch_ohne_WBT (CM_zFAS_Warnblinken_Cx3_Statisch_ohne_WBT)}, range raw 0..3, transfer-property=TRIGGERED-ON-CHANGE-WITHOUT-REPETITION  # Anforderung Warnblinken durch zFAS Funktionen.
          signal STP_Primaeranz_XIX_EA_02_XIX_E3V_K2CANFD: start 28, 3 bit, little-endian, data-type-policy=OVERRIDE, i-signal-type=PRIMITIVE, init-value=0, base-type=BT_STP_Primaeranz, compu {0=Cx0_keine_Anzeige (CM_STP_Primaeranz_Cx0_keine_Anzeige), 1=Cx1_Verfuegbar (CM_STP_Primaeranz_Cx1_Verfuegbar), 2=Cx2_Aktiv (CM_STP_Primaeranz_Cx2_Aktiv), 3=Cx3_Uebernahme (CM_STP_Primaeranz_Cx3_Uebernahme), 4=Cx4_Aktiv_Warnung (CM_STP_Primaeranz_Cx4_Aktiv_Warnung), 5=Cx5_Nicht_Verfuegbar (CM_STP_Primaeranz_Cx5_Nicht_Verfuegbar)}, range raw 0..5, transfer-property=TRIGGERED-ON-CHANGE-WITHOUT-REPETITION  # Primäranzeige des Staupiloten
          signal EA_Bremslichtblinken_XIX_EA_02_XIX_E3V_K2CANFD: start 31, 1 bit, little-endian, data-type-policy=OVERRIDE, i-signal-type=PRIMITIVE, init-value=0, base-type=BT_EA_Bremslichtblinken, compu {0=Cx0_kein_Blinken (CM_EA_Bremslichtblinken_Cx0_kein_Blinken), 1=Cx1_Anforderung_Bremslichtblinken (CM_EA_Bremslichtblinken_Cx1_Anforderung_Bremslichtblinken)}, range raw 0..1, transfer-property=TRIGGERED-ON-CHANGE-WITHOUT-REPETITION  # Die Funktion Emergency Alert fordert ein Blinken der Bremsleuchten an.
          signal EA_Blinken_XIX_EA_02_XIX_E3V_K2CANFD: start 32, 3 bit, little-endian, data-type-policy=OVERRIDE, i-signal-type=PRIMITIVE, init-value=0, base-type=BT_EA_Blinken, compu {0=Cx0_Kein_Blinken (CM_EA_Blinken_Cx0_Kein_Blinken), 1=Cx1_Wechselblinken_links (CM_EA_Blinken_Cx1_Wechselblinken_links), 2=Cx2_Wechselblinken_rechts (CM_EA_Blinken_Cx2_Wechselblinken_rechts), 3=Cx3_Warnblinken (CM_EA_Blinken_Cx3_Warnblinken), 4=Cx4_Warnblinken_Taster (CM_EA_Blinken_Cx4_Warnblinken_Taster), 5=Cx5_Richtungsblinken_links (CM_EA_Blinken_Cx5_Richtungsblinken_links), 6=Cx6_Richtungsblinken_rechts (CM_EA_Blinken_Cx6_Richtungsblinken_rechts)}, range raw 0..6, transfer-property=TRIGGERED-ON-CHANGE-WITHOUT-REPETITION  # Emergency Assist Anforderung Blinker
          signal EA_Status_HMI_XIX_EA_02_XIX_E3V_K2CANFD: start 35, 2 bit, little-endian, data-type-policy=OVERRIDE, i-signal-type=PRIMITIVE, init-value=0, base-type=BT_EA_Status_HMI, compu {0=Cx0_Keine_Anzeige (CM_EA_Status_HMI_Cx0_Keine_Anzeige), 1=Cx1_Aktiv_quer_laengs (CM_EA_Status_HMI_Cx1_Aktiv_quer_laengs), 2=Cx2_Aktiv_laengs (CM_EA_Status_HMI_Cx2_Aktiv_laengs)}, range raw 0..2, transfer-property=TRIGGERED-ON-CHANGE-WITHOUT-REPETITION  # Anzeige Emergency Assist-Statusleuchte im Fahrerinformationsdisplay
          signal EA_Warnlevel_XIX_EA_02_XIX_E3V_K2CANFD: start 58, 6 bit, little-endian, data-type-policy=OVERRIDE, i-signal-type=PRIMITIVE, init-value=0, base-type=BT_EA_Warnlevel, compu {0=Cx0_keine_Gefaehrdung (CM_EA_Warnlevel_Cx0_keine_Gefaehrdung), 63=Cx3f_max_Gefaehrdung (CM_EA_Warnlevel_Cx3f_max_Gefaehrdung)}, range raw 0..63, transfer-property=TRIGGERED-ON-CHANGE-WITHOUT-REPETITION  # Kritikalität der Funktion Emergency Assist
      frame eRWK_01_XIX_E3V_K2CANFD: id 0x12DD55D7, to SAM, frame-length=8, can-addressing-mode=EXTENDED, can-frame-rx-behavior=CAN-FD, can-frame-tx-behavior=CAN-FD
        pdu eRWK_01_XIX_E3V_K2CANFD: length=8, transmission-mode-true-timing=cyclic-timing={time-offset=0, time-period=0.1}, unused-bit-pattern=0
          signal eRWK_AD_oeffnen_Anf_XIX_eRWK_01_XIX_E3V_K2CANFD: start 12, 1 bit, little-endian, data-type-policy=OVERRIDE, i-signal-type=PRIMITIVE, init-value=0, base-type=BT_eRWK_AD_oeffnen_Anf, compu {0=Cx0_Keine_Anforderung (CM_eRWK_AD_oeffnen_Anf_Cx0_Keine_Anforderung), 1=Cx1_Anforderung (CM_eRWK_AD_oeffnen_Anf_Cx1_Anforderung)}, range raw 0..1, transfer-property=PENDING, to SAM(timeout 1 s)  # Öffnungsanforderung eRWK per Remote
          signal eRWK_AD_schliessen_Anf_XIX_eRWK_01_XIX_E3V_K2CANFD: start 13, 1 bit, little-endian, data-type-policy=OVERRIDE, i-signal-type=PRIMITIVE, init-value=0, base-type=BT_eRWK_AD_schliessen_Anf, compu {0=Cx0_Keine_Anforderung (CM_eRWK_AD_schliessen_Anf_Cx0_Keine_Anforderung), 1=Cx1_Anforderung (CM_eRWK_AD_schliessen_Anf_Cx1_Anforderung)}, range raw 0..1, transfer-property=PENDING, to SAM(timeout 1 s)  # Schließanforderung eRWK per Remote
      frame ESC_50_XIX_E3V_K2CANFD: id 0x102, to SAM, frame-length=48, can-addressing-mode=STANDARD, can-frame-rx-behavior=CAN-FD, can-frame-tx-behavior=CAN-FD
        pdu ESC_50_XIX_E3V_K2CANFD: length=44, transmission-mode-true-timing=cyclic-timing={time-offset=0.0, time-period=0.02}, unused-bit-pattern=0
          signal ESC_50_CRC_XIX_ESC_50_XIX_E3V_K2CANFD: start 0, 8 bit, little-endian, data-type-policy=OVERRIDE, i-signal-type=PRIMITIVE, base-type=BT_ESC_50_CRC, compu {phys=raw for raw 0..255}, range phys 0..255, raw 0..255, transfer-property=PENDING  # Für MLB: Berechnung siehe Lastenheft "Kommunikationsabsicherung für FlexRay und CAN" Ab MQB und MLBevo: Berechnung siehe Lastenheft "End-to-End Kommunikationsabsicherung" Endwerte siehe Begleitdokument "S-PDU Kennungsfolgen"
          signal ESC_50_BZ_XIX_ESC_50_XIX_E3V_K2CANFD: start 8, 4 bit, little-endian, data-type-policy=OVERRIDE, i-signal-type=PRIMITIVE, base-type=BT_ESC_50_BZ, compu {phys=raw for raw 0..15}, range phys 0..15, raw 0..15, transfer-property=PENDING  # 4bit Botschaftszähler, wird mit jeder Sendebotschaft inkrementiert
          signal ESP_QBit_Gierrate_XIX_ESC_50_XIX_E3V_K2CANFD: start 12, 1 bit, little-endian, data-type-policy=OVERRIDE, i-signal-type=PRIMITIVE, init-value=1, base-type=BT_ESP_QBit_Gierrate, compu {0=Cx0_gueltiger_Wert (CM_ESP_QBit_Gierrate_Cx0_gueltiger_Wert), 1=Cx1_Ersatz_Init_oder_Fehlerwert (CM_ESP_QBit_Gierrate_Cx1_Ersatz_Init_oder_Fehlerwert)}, range raw 0..1, transfer-property=PENDING  # QBit der Gierrate. Gesetzt bei Ersatzwert, Init oder Fehler.
          signal ESP_QBit_Laengsbeschl_XIX_ESC_50_XIX_E3V_K2CANFD: start 13, 1 bit, little-endian, data-type-policy=OVERRIDE, i-signal-type=PRIMITIVE, init-value=1, base-type=BT_ESP_QBit_Laengsbeschl, compu {0=Cx0_gueltiger_Wert (CM_ESP_QBit_Laengsbeschl_Cx0_gueltiger_Wert), 1=Cx1_Ersatz_Init_oder_Fehlerwert (CM_ESP_QBit_Laengsbeschl_Cx1_Ersatz_Init_oder_Fehlerwert)}, range raw 0..1, transfer-property=PENDING  # QBit der Längsbeschleunigung. Gesetzt bei Ersatzwert, Init oder Fehler.
          signal ESP_QBit_Querb_XIX_ESC_50_XIX_E3V_K2CANFD: start 14, 1 bit, little-endian, data-type-policy=OVERRIDE, i-signal-type=PRIMITIVE, init-value=1, base-type=BT_ESP_QBit_Querb, compu {0=Cx0_gueltiger_Wert (CM_ESP_QBit_Querb_Cx0_gueltiger_Wert), 1=Cx1_Ersatz_Init_oder_Fehlerwert (CM_ESP_QBit_Querb_Cx1_Ersatz_Init_oder_Fehlerwert)}, range raw 0..1, transfer-property=PENDING  # QBit der Querbeschleunigung. Gesetzt bei Ersatzwert, Init oder Fehler.
          signal ESP_Querbeschleunigung_XIX_ESC_50_XIX_E3V_K2CANFD: start 16, 8 bit, little-endian, data-type-policy=OVERRIDE, i-signal-type=PRIMITIVE, init-value=127, base-type=BT_ESP_Querbeschleunigung, invalid-value=Invalid_ESP_Querbeschleunigung_XIX_ESC_50_XIX_E3V_K2CANFD:255, compu {phys=raw*0.01-1.27 for raw 0..254, 255=Cxff_Fehler (CM_ESP_Querbeschleunigung_Cxff_Fehler); unit Unit_ForceOfGravi}, range phys -1.27..1.27 Unit_ForceOfGravi, raw 0..255, unit=Unit_ForceOfGravi, transfer-property=PENDING, to SAM(timeout 0.5 s)  # Beschleunigungswert in y-Achse MLB: Gemessener Wert 0xFF = Fehler (wie bereits im Wertebereich spezifizert) Bei ESP-Abschaltung durch modellgestützte Überwachung wird das Signal weiterhin ausgegeben. Im AU64x und AU57x erfolgt die Bereitstellung der Sensorwerte durch SARA-SG! MQB: Sensorrohwert Querbeschleunigung Bei ESP gemessene Größe, bei ABS errechnet (ungenauer Ersatzwert)
          signal ESP_Laengsbeschl_XIX_ESC_50_XIX_E3V_K2CANFD: start 24, 10 bit, little-endian, data-type-policy=OVERRIDE, i-signal-type=PRIMITIVE, init-value=512, base-type=BT_ESP_Laengsbeschl, invalid-value=Invalid_ESP_Laengsbeschl_XIX_ESC_50_XIX_E3V_K2CANFD:1023, compu {phys=raw/32-16 for raw 0..1021, 1022=Cx3fe_Signal_nicht_vorhanden (CM_ESP_Laengsbeschl_Cx3fe_Signal_nicht_vorhanden), 1023=Cx3ff_Fehler (CM_ESP_Laengsbeschl_Cx3ff_Fehler); unit Unit_MeterPerSeconSquar}, range phys -16..15.90625 Unit_MeterPerSeconSquar, raw 0..1023, unit=Unit_MeterPerSeconSquar, transfer-property=PENDING, to SAM(timeout 0.5 s)  # Beschleunigungswert in x-Achse MLB: Im AU64x und AU57x erfolgt die Bereitstellung der Sensorwerte durch SARA-SG! Im AU64x und AU57x wird bei ESP-Abschaltung durch modellgestützte Überwachung das Signal weiterhin ausgegeben. MQB: reines ABS schickt 0x3FE für "nicht vorhanden"
          signal ESC_Motorstartverzoegerung_XIX_ESC_50_XIX_E3V_K2CANFD: start 34, 1 bit, little-endian, data-type-policy=OVERRIDE, i-signal-type=PRIMITIVE, init-value=0, base-type=BT_ESC_Motorstartverzoegerung, compu {0=Cx0_Startfreigabe (CM_ESC_Motorstartverzoegerung_Cx0_Startfreigabe), 1=Cx1_Anforderung_Startverzoegerung (CM_ESC_Motorstartverzoegerung_Cx1_Anforderung_Startverzoegerung)}, range raw 0..1, transfer-property=PENDING  # Mit dem Signal "Motorstartverzögerung" wird den aktiven Teilnehmern ermöglicht, einen Motorstart durch die Start-Stop-Funktion zu verzögern.
          signal ESC_SeitenwindAssistent_Eingriff_XIX_ESC_50_XIX_E3V_K2CANFD: start 35, 1 bit, little-endian, data-type-policy=OVERRIDE, i-signal-type=PRIMITIVE, init-value=0, base-type=BT_ESC_SeitenwindAssistent_Eingriff, compu {0=Cx0_Kein_SWA_Eingriff_und_Init (CM_ESC_SeitenwindAssistent_Eingriff_Cx0_Kein_SWA_Eingriff_und_Init), 1=Cx1_SWA_Eingriff_aktiv (CM_ESC_SeitenwindAssistent_Eingriff_Cx1_SWA_Eingriff_aktiv)}, range raw 0..1, transfer-property=PENDING  # Mit diesem Statusbit wird eine aktive Regelung durch den Seitenwindassistenten signalisiert.
          signal ESP_Anschleppstart_Freigabe_XIX_ESC_50_XIX_E3V_K2CANFD: start 36, 2 bit, little-endian, data-type-policy=OVERRIDE, i-signal-type=PRIMITIVE, init-value=0, base-type=BT_ESP_Anschleppstart_Freigabe, compu {0=Cx0_kein_Schleppstart_oder_NotSchleppstart_erlaubt (CM_ESP_Anschleppstart_Freigabe_Cx0_kein_Schleppstart_oder_NotSchleppstart_erlaubt), 1=Cx1_NotSchleppstart_erlaubt (CM_ESP_Anschleppstart_Freigabe_Cx1_NotSchleppstart_erlaubt), 2=Cx2_Schleppstart_und_NotSchleppStart_erlaubt (CM_ESP_Anschleppstart_Freigabe_Cx2_Schleppstart_und_NotSchleppStart_erlaubt)}, range raw 0..2, transfer-property=PENDING  # Bilden einer Schleppstartfreigabe aus Fahrdynamiksicht. Schleppstartabbruch bei kritischer Fahrzeugstabilität
          signal ESC_Unterdruckmangel_erkannt_XIX_ESC_50_XIX_E3V_K2CANFD: start 38, 1 bit, little-endian, data-type-policy=OVERRIDE, i-signal-type=PRIMITIVE, init-value=0, base-type=BT_ESC_Unterdruckmangel_erkannt, compu {0=Cx0_kein_Unterdruckmangel_erkannt (CM_ESC_Unterdruckmangel_erkannt_Cx0_kein_Unterdruckmangel_erkannt), 1=Cx1_Unterdruckmangel_erkannt (CM_ESC_Unterdruckmangel_erkannt_Cx1_Unterdruckmangel_erkannt)}, range raw 0..1, transfer-property=PENDING  # ESC hat einen Unterdruckmangel im Bremskraftverstärker festgestellt
          signal ESP_Gierrate_XIX_ESC_50_XIX_E3V_K2CANFD: start 40, 14 bit, little-endian, data-type-policy=OVERRIDE, i-signal-type=PRIMITIVE, init-value=0, base-type=BT_ESP_Gierrate, invalid-value=Invalid_ESP_Gierrate_XIX_ESC_50_XIX_E3V_K2CANFD:16383, compu {phys=raw*0.01 for raw 0..16382, 16383=Cx3fff_Fehler (CM_ESP_Gierrate_Cx3fff_Fehler); unit Unit_DegreOfArcPerSecon}, range phys 0..163.82 Unit_DegreOfArcPerSecon, raw 0..16383, unit=Unit_DegreOfArcPerSecon, transfer-property=PENDING  # Winkelgeschwindigkeit um die z-Achse, ESP_VZ_Gierrate & ESP_QBit_Gierrate beachten !!! MLB: gemessener Wert tatsächliche Auflösung Bosch ESP: 0,27 Grad/s Ab AU64x Auflösung wie die tatsächliche Skalierung 0,01. Im AU64x und AU57x wird bei ESP-Abschaltung durch modellgestützte Überwachung das Signal weiterhin ausgegeben. Signalgüte abhängig vom QBit-Gierrate. Ab AU64x erfolgt die Bereitstellung der Sensorwerte durch SARA-SG! MQB: Rohwert der gemessenen Gierrate
          signal ESP_VZ_Gierrate_XIX_ESC_50_XIX_E3V_K2CANFD: start 54, 1 bit, little-endian, data-type-policy=OVERRIDE, i-signal-type=PRIMITIVE, init-value=0, base-type=BT_ESP_VZ_Gierrate, compu {0=Cx0_positiv (CM_ESP_VZ_Gierrate_Cx0_positiv), 1=Cx1_negativ (CM_ESP_VZ_Gierrate_Cx1_negativ)}, range raw 0..1, transfer-property=PENDING  # Vorzeichen der Gierrate
          signal ESP_Notbremsanzeige_XIX_ESC_50_XIX_E3V_K2CANFD: start 55, 1 bit, little-endian, data-type-policy=OVERRIDE, i-signal-type=PRIMITIVE, init-value=0, base-type=BT_ESP_Notbremsanzeige, compu {0=Cx0_keine_Notbremsung_erkannt (CM_ESP_Notbremsanzeige_Cx0_keine_Notbremsung_erkannt), 1=Cx1_Notbremsung_erkannt (CM_ESP_Notbremsanzeige_Cx1_Notbremsung_erkannt)}, range raw 0..1, transfer-property=PENDING  # ABS/ASR oder ESP hat Notbremssituation erkannt. Weiterführende Informationen im Lastenheft spezifiziert und in der entsprechenden Fachabteilung zu erfragen.
          signal ESP_SpannungsAnf_XIX_ESC_50_XIX_E3V_K2CANFD: start 56, 1 bit, little-endian, data-type-policy=OVERRIDE, i-signal-type=PRIMITIVE, init-value=0, base-type=BT_ESP_SpannungsAnf, compu {0=Cx0_keine_Anforderung (CM_ESP_SpannungsAnf_Cx0_keine_Anforderung), 1=Cx1_Anforderung_Spannungswert_1 (CM_ESP_SpannungsAnf_Cx1_Anforderung_Spannungswert_1)}, range raw 0..1, transfer-property=PENDING  # Die Rekuperation kann mit der Anforderung einer höheren Spannung eingeschränkt werden.
          signal ESP_PLA_Abbruch_XIX_ESC_50_XIX_E3V_K2CANFD: start 57, 3 bit, little-endian, data-type-policy=OVERRIDE, i-signal-type=PRIMITIVE, init-value=0, base-type=BT_ESP_PLA_Abbruch, compu {0=Cx0_Init (CM_ESP_PLA_Abbruch_Cx0_Init), 1=Cx1_Geschwindigkeitsueberschreitung (CM_ESP_PLA_Abbruch_Cx1_Geschwindigkeitsueberschreitung), 2=Cx2_Falscher_PLA_Status (CM_ESP_PLA_Abbruch_Cx2_Falscher_PLA_Status), 3=Cx3_Deaktivierung_durch_Abbruch_Lenkung (CM_ESP_PLA_Abbruch_Cx3_Deaktivierung_durch_Abbruch_Lenkung), 4=Cx4_PLA_Bremsanforderung_nach_Stillstand (CM_ESP_PLA_Abbruch_Cx4_PLA_Bremsanforderung_nach_Stillstand), 5=Cx5_Abbruch_durch_Kl15_aus (CM_ESP_PLA_Abbruch_Cx5_Abbruch_durch_Kl15_aus), 6=Cx6_Abbruch_durch_FT_offen (CM_ESP_PLA_Abbruch_Cx6_Abbruch_durch_FT_offen)}, range raw 0..6, transfer-property=PENDING  # Wenn der Bremseingriff abgebrochen wurde, wird in diesem Signal der Grund des Abbruchs dargestellt. Dies ist nur gültig, wenn der Status ESP_Status_ESP_PLA = "0xA" ist.
          signal ESP_Status_ESP_PLA_XIX_ESC_50_XIX_E3V_K2CANFD: start 60, 4 bit, little-endian, data-type-policy=OVERRIDE, i-signal-type=PRIMITIVE, init-value=0, base-type=BT_ESP_Status_ESP_PLA, compu {0=Cx0_ESP_PLA_deaktiv (CM_ESP_Status_ESP_PLA_Cx0_ESP_PLA_deaktiv), 1=Cx1_ESP_PLA_Init (CM_ESP_Status_ESP_PLA_Cx1_ESP_PLA_Init), 2=Cx2_ESP_PLA_Fehler (CM_ESP_Status_ESP_PLA_Cx2_ESP_PLA_Fehler), 4=Cx4_ESP_PLA_aktivierbar (CM_ESP_Status_ESP_PLA_Cx4_ESP_PLA_aktivierbar), 6=Cx6_ESP_PLA_Bremse_aktiv (CM_ESP_Status_ESP_PLA_Cx6_ESP_PLA_Bremse_aktiv), 8=Cx8_ESP_PLA_funktionsbereit (CM_ESP_Status_ESP_PLA_Cx8_ESP_PLA_funktionsbereit), 9=Cx9_ESP_PLA_Neustart (CM_ESP_Status_ESP_PLA_Cx9_ESP_PLA_Neustart), 10=Cxa_ESP_PLA_Abbruch (CM_ESP_Status_ESP_PLA_Cxa_ESP_PLA_Abbruch)}, range raw 0..10, transfer-property=PENDING  # Zustand der Statusmaschine der Bremse für die korrespondierende Statusmaschine in dem PLA-SG
          signal ESP_QBit_Bremsdruck_XIX_ESC_50_XIX_E3V_K2CANFD: start 76, 1 bit, little-endian, data-type-policy=OVERRIDE, i-signal-type=PRIMITIVE, init-value=1, base-type=BT_ESP_QBit_Bremsdruck, compu {0=Cx0_gueltiger_Wert (CM_ESP_QBit_Bremsdruck_Cx0_gueltiger_Wert), 1=Cx1_Ersatz_Init_oder_Fehlerwert (CM_ESP_QBit_Bremsdruck_Cx1_Ersatz_Init_oder_Fehlerwert)}, range raw 0..1, transfer-property=PENDING  # QBit des Bremsdrucks. Gesetzt bei Ersatzwert, Init oder Fehler.
          signal ESP_QBit_Fahrer_bremst_XIX_ESC_50_XIX_E3V_K2CANFD: start 77, 1 bit, little-endian, data-type-policy=OVERRIDE, i-signal-type=PRIMITIVE, init-value=0, base-type=BT_ESP_QBit_Fahrer_bremst, compu {0=Cx0_gueltiger_Wert (CM_ESP_QBit_Fahrer_bremst_Cx0_gueltiger_Wert), 1=Cx1_Ersatz_Init_oder_Fehlerwert (CM_ESP_QBit_Fahrer_bremst_Cx1_Ersatz_Init_oder_Fehlerwert)}, range raw 0..1, transfer-property=PENDING  # Gültigkeit der Bremsdruckschwelleninformation des Signals ESP_Fahrer_bremst vom ESP SG 0x1 = Druckschwelleninformation kann noch nicht oder aufgrund eines Fehlers nicht ausgegeben werden
          signal ESP_Schwelle_Unterdruck_XIX_ESC_50_XIX_E3V_K2CANFD: start 78, 2 bit, little-endian, data-type-policy=OVERRIDE, i-signal-type=PRIMITIVE, init-value=0, base-type=BT_ESP_Schwelle_Unterdruck, compu {0=Cx0_kein_Signal (CM_ESP_Schwelle_Unterdruck_Cx0_kein_Signal), 1=Cx1_Unterdruck_kleiner_gleich_450_mbar (CM_ESP_Schwelle_Unterdruck_Cx1_Unterdruck_kleiner_gleich_450_mbar), 2=Cx2_Unterdruck_groesser_450_mbar (CM_ESP_Schwelle_Unterdruck_Cx2_Unterdruck_groesser_450_mbar), 3=Cx3_Fehler_Unterdrucksensor (CM_ESP_Schwelle_Unterdruck_Cx3_Fehler_Unterdrucksensor)}, range raw 0..3, transfer-property=PENDING  # Verwendung im MQB für HBV-Projekte oder wenn für St/St ein Unterdrucksensor verbaut ist
          signal ESP_Bremsdruck_XIX_ESC_50_XIX_E3V_K2CANFD: start 80, 10 bit, little-endian, data-type-policy=OVERRIDE, i-signal-type=PRIMITIVE, init-value=100, base-type=BT_ESP_Bremsdruck, invalid-value=Invalid_ESP_Bremsdruck_XIX_ESC_50_XIX_E3V_K2CANFD:1023, compu {phys=raw*0.3-30 for raw 0..1022, 1023=Cx3ff_Fehler (CM_ESP_Bremsdruck_Cx3ff_Fehler); unit Unit_Bar}, range phys -30..276.6 Unit_Bar, raw 0..1023, unit=Unit_Bar, transfer-property=PENDING  # Rohwert des Bremsdrucks Für Fahrzeuge mit elektrischem Bremskraftverstärker gilt: Aus dem Signal ESP_Bremsdruck lässt sich kein Fahrerbremswunsch ableiten. Das Signal bildet lediglich den hydraulischen Anteil der Fahrzeugverzögerung ab. Der Rohwert des Signals kann auch ohne Fahrerbeteiligung (ohne Betätigung des Bremspedals) variieren. (z.B. ACC,AWV, Autohold). Für HEV/PHEV gilt: Während einer Bremsung mit überlagertem Generatorbremsmoment ist der angezeigte Druck kleiner als der Fahrerbremswunsch. Für Fahrzeuge mit Vakuum-Bremskraftverstärker gilt: Rohwert des Bremsdrucks [Vordruck durch Fahrervorgabe (Pvor). Bei aktivem Druckaufbau (Stabilisierungseingriffe) kein Pvor]
          signal ESP_Fahrer_bremst_XIX_ESC_50_XIX_E3V_K2CANFD: start 90, 1 bit, little-endian, data-type-policy=OVERRIDE, i-signal-type=PRIMITIVE, init-value=0, base-type=BT_ESP_Fahrer_bremst, compu {0=Cx0_Bremsdruckschwelle_nicht_ueberschritten (CM_ESP_Fahrer_bremst_Cx0_Bremsdruckschwelle_nicht_ueberschritten), 1=Cx1_Bremsdruckschwelle_ueberschritten (CM_ESP_Fahrer_bremst_Cx1_Bremsdruckschwelle_ueberschritten)}, range raw 0..1, transfer-property=PENDING  # Bit wird gesetzt beim Überschreiten der Bremsdruckschwelle Weiterführende Informationen im Lastenheft spezifiziert und in der entsprechenden Fachabteilung zu erfragen.
          signal ESP_Verz_TSK_aktiv_XIX_ESC_50_XIX_E3V_K2CANFD: start 91, 1 bit, little-endian, data-type-policy=OVERRIDE, i-signal-type=PRIMITIVE, init-value=0, base-type=BT_ESP_Verz_TSK_aktiv, compu {0=Cx0_TSK_Verzoegerung_inaktiv (CM_ESP_Verz_TSK_aktiv_Cx0_TSK_Verzoegerung_inaktiv), 1=Cx1_TSK_Verzoegerung_aktiv (CM_ESP_Verz_TSK_aktiv_Cx1_TSK_Verzoegerung_aktiv)}, range raw 0..1, transfer-property=PENDING  # Rückmeldeinformation an den Triebsstrangkoordinator/ACC, dass die ECD-Verzögerungsanforderung aktuell umgesetzt wird
          signal ESP_Lenkeingriff_ADS_XIX_ESC_50_XIX_E3V_K2CANFD: start 92, 1 bit, little-endian, data-type-policy=OVERRIDE, i-signal-type=PRIMITIVE, init-value=0, base-type=BT_ESP_Lenkeingriff_ADS, compu {0=Cx0_kein_Lenkeingriff (CM_ESP_Lenkeingriff_ADS_Cx0_kein_Lenkeingriff), 1=Cx1_stabilisierender_Lenkeingriff (CM_ESP_Lenkeingriff_ADS_Cx1_stabilisierender_Lenkeingriff)}, range raw 0..1, transfer-property=PENDING  # Im Falle eines fahrzeugstabilisierenden Lenkeingriffs des ADS-Systems soll ACC/GRA deaktiviert werden. Im MQB wird dieses Signal nicht unterstützt!
          signal ESP_Konsistenz_TSK_XIX_ESC_50_XIX_E3V_K2CANFD: start 93, 1 bit, little-endian, data-type-policy=OVERRIDE, i-signal-type=PRIMITIVE, init-value=0, base-type=BT_ESP_Konsistenz_TSK, compu {0=Cx0_Botschaft_fuer_Verzoegerungsanforderung_konsistent (CM_ESP_Konsistenz_TSK_Cx0_Botschaft_fuer_Verzoegerungsanforderung_konsistent), 1=Cx1_Botschaft_fuer_Verzoegerungsanforderung_nicht_konsistent (CM_ESP_Konsistenz_TSK_Cx1_Botschaft_fuer_Verzoegerungsanforderung_nicht_konsistent)}, range raw 0..1, transfer-property=PENDING  # Rückmeldung zum Sender einer Verzögerungsanforderung (Triebstrangskoordinator) bezüglich Prüfung der Checksumme, des Botschaftszählers, des langen Timeout und DLC. Wird auch gesetzt bei Verzögerungsanforderung größer einer applizierbaren Schwelle.
          signal ESP_Bremsruck_AWV2_XIX_ESC_50_XIX_E3V_K2CANFD: start 94, 1 bit, little-endian, data-type-policy=OVERRIDE, i-signal-type=PRIMITIVE, init-value=0, base-type=BT_ESP_Bremsruck_AWV2, compu {0=Cx0_kein_Bremsruck_ausgefuehrt (CM_ESP_Bremsruck_AWV2_Cx0_kein_Bremsruck_ausgefuehrt), 1=Cx1_Bremsruck_ausgefuehrt (CM_ESP_Bremsruck_AWV2_Cx1_Bremsruck_ausgefuehrt)}, range raw 0..1, transfer-property=PENDING  # Das Signal dient als Rückmeldung zum ACC, dass ein angeforderter AWV2-Bremsruck durchgeführt wird. Die positive Rückmeldung löst u.a. eine entsprechende Fahrerinformation im Kombiinstrument aus
          signal ESP_Konsistenz_AWV2_XIX_ESC_50_XIX_E3V_K2CANFD: start 95, 1 bit, little-endian, data-type-policy=OVERRIDE, i-signal-type=PRIMITIVE, init-value=0, base-type=BT_ESP_Konsistenz_AWV2, compu {0=Cx0_Botschaft_fuer_AWV2_konsistent (CM_ESP_Konsistenz_AWV2_Cx0_Botschaft_fuer_AWV2_konsistent), 1=Cx1_Botschaft_fuer_AWV2_nicht_konsistent (CM_ESP_Konsistenz_AWV2_Cx1_Botschaft_fuer_AWV2_nicht_konsistent)}, range raw 0..1, transfer-property=PENDING  # Rückmeldung zum Sender einer AWV-Anforderung (ACC-Steuergerät) bezüglich Prüfung der Checksumme, des Botschaftszählers, des langen Timeout und DLC.
          signal ECD_Fehler_XIX_ESC_50_XIX_E3V_K2CANFD: start 96, 1 bit, little-endian, data-type-policy=OVERRIDE, i-signal-type=PRIMITIVE, init-value=0, base-type=BT_ECD_Fehler, compu {0=Cx0_ECD_iO (CM_ECD_Fehler_Cx0_ECD_iO), 1=Cx1_ECD_Fehler (CM_ECD_Fehler_Cx1_ECD_Fehler)}, range raw 0..1, transfer-property=PENDING  # ESP kann die Verzögerungsregelung/Bremsenregelung aufgrund eines internen Fehlers nicht ausführen, mit Fehlereintrag im ESP.
          signal ECD_nicht_verfuegbar_XIX_ESC_50_XIX_E3V_K2CANFD: start 97, 1 bit, little-endian, data-type-policy=OVERRIDE, i-signal-type=PRIMITIVE, init-value=1, base-type=BT_ECD_nicht_verfuegbar, compu {0=Cx0_ECD_Funktion_verfuegbar (CM_ECD_nicht_verfuegbar_Cx0_ECD_Funktion_verfuegbar), 1=Cx1_ECD_Funktion_nicht_verfuegbar (CM_ECD_nicht_verfuegbar_Cx1_ECD_Funktion_nicht_verfuegbar)}, range raw 0..1, transfer-property=PENDING  # ESP kann die Verzögerungsregelung/Bremsenregelung temporär nicht ausführen (z.B. Netzwerkmanagement-Betriebe - KL15 Aus; v<18km/h; ESP in Diagnose, ...), ohne Fehlereintrag im ESP.
          signal ESP_Status_Bremsentemp_XIX_ESC_50_XIX_E3V_K2CANFD: start 98, 1 bit, little-endian, data-type-policy=OVERRIDE, i-signal-type=PRIMITIVE, init-value=0, base-type=BT_ESP_Status_Bremsentemp, compu {0=Cx0_Bremse_nicht_ueberhitzt (CM_ESP_Status_Bremsentemp_Cx0_Bremse_nicht_ueberhitzt), 1=Cx1_Bremse_ueberhitzt (CM_ESP_Status_Bremsentemp_Cx1_Bremse_ueberhitzt)}, range raw 0..1, transfer-property=PENDING  # ECD-Bremsscheibentemperaturmodell. Rückmeldung für Sender einer ECD Verzögerungsanforderung, ohne Fehlereintrag im ESP
          signal ESP_Autohold_Standby_XIX_ESC_50_XIX_E3V_K2CANFD: start 99, 1 bit, little-endian, data-type-policy=OVERRIDE, i-signal-type=PRIMITIVE, init-value=0, base-type=BT_ESP_Autohold_Standby, compu {0=Cx0_Autohold_nicht_im_Standby (CM_ESP_Autohold_Standby_Cx0_Autohold_nicht_im_Standby), 1=Cx1_Autohold_im_Standby (CM_ESP_Autohold_Standby_Cx1_Autohold_im_Standby)}, range raw 0..1, transfer-property=PENDING  # Rückmeldung an EPB, dass der Fahrer die Funktion Autohold mindestens einmal angefordert hat. Im Fall eines ESP-Ausfalles oder einer Übernahmeaufforderung erfolgt die EPB-Zuschaltung nur nach Setzen dieses Bits. Bit wird gesetzt nach Betätigung des Autohold-Tasters und wenn ESP incl. Aktivierungsbedingungen (z.B. Gurt gesteckt, ...) dazu bereit ist.
          signal ESP_HDC_Standby_XIX_ESC_50_XIX_E3V_K2CANFD: start 100, 1 bit, little-endian, data-type-policy=OVERRIDE, i-signal-type=PRIMITIVE, init-value=0, base-type=BT_ESP_HDC_Standby, compu {0=Cx0_HDC_Funktion_nicht_im_Standby (CM_ESP_HDC_Standby_Cx0_HDC_Funktion_nicht_im_Standby), 1=Cx1_HDC_Funktion_im_Standby (CM_ESP_HDC_Standby_Cx1_HDC_Funktion_im_Standby)}, range raw 0..1, transfer-property=PENDING  # Verwendung/Bedienung im MQB und AU57x Allroad: Flag wird vom ESP gesetzt, wenn über den HDC-Taster die HDC-Funktion eingeschalten wurde
          signal ESP_HBA_aktiv_XIX_ESC_50_XIX_E3V_K2CANFD: start 101, 1 bit, little-endian, data-type-policy=OVERRIDE, i-signal-type=PRIMITIVE, init-value=0, base-type=BT_ESP_HBA_aktiv, compu {0=Cx0_HBA_nicht_aktiv (CM_ESP_HBA_aktiv_Cx0_HBA_nicht_aktiv), 1=Cx1_HBA_aktiv (CM_ESP_HBA_aktiv_Cx1_HBA_aktiv)}, range raw 0..1, transfer-property=PENDING  # Verwendung/Bedienung ab D4 Signal gibt an, ob der hydraulische Bremsassistent im Regler aktiviert wurde Im MQB wird das Signal nicht unterstützt!
          signal ESP_Prefill_ausgeloest_XIX_ESC_50_XIX_E3V_K2CANFD: start 102, 1 bit, little-endian, data-type-policy=OVERRIDE, i-signal-type=PRIMITIVE, init-value=0, base-type=BT_ESP_Prefill_ausgeloest, compu {0=Cx0_nicht_ausgeloest (CM_ESP_Prefill_ausgeloest_Cx0_nicht_ausgeloest), 1=Cx1_Prefill_ausgeloest (CM_ESP_Prefill_ausgeloest_Cx1_Prefill_ausgeloest)}, range raw 0..1, transfer-property=PENDING  # MLB: Verwendung/Bedienung ab D4 zeigt, ob die Funktion Prefill (aufgrund Fahrpedalgradient) ausgelöst wird; zeigt keinen Funktionszustand bezüglich Fehlerstilllegung MQB: Wird gesetzt bei jeder Art von aktivem Prefill
          signal ESP_Rueckwaertsfahrt_erkannt_XIX_ESC_50_XIX_E3V_K2CANFD: start 103, 1 bit, little-endian, data-type-policy=OVERRIDE, i-signal-type=PRIMITIVE, init-value=0, base-type=BT_ESP_Rueckwaertsfahrt_erkannt, compu {0=Cx0_keine_Rueckwaetsfahrt (CM_ESP_Rueckwaertsfahrt_erkannt_Cx0_keine_Rueckwaetsfahrt), 1=Cx1_Rueckwaertsfahrt_sicher_erkannt (CM_ESP_Rueckwaertsfahrt_erkannt_Cx1_Rueckwaertsfahrt_sicher_erkannt)}, range raw 0..1, transfer-property=PENDING  # nur bei AU57x und AU416 sowie Audi B8PA Info, ob Rückwärtsfahrt über internen Algorithmus sicher erkannt Im MQB wird das Signal nicht unterstützt!
          signal ESP_Status_Anfahrhilfe_XIX_ESC_50_XIX_E3V_K2CANFD: start 104, 1 bit, little-endian, data-type-policy=OVERRIDE, i-signal-type=PRIMITIVE, init-value=0, base-type=BT_ESP_Status_Anfahrhilfe, compu {0=Cx0_Aus (CM_ESP_Status_Anfahrhilfe_Cx0_Aus), 1=Cx1_Ein (CM_ESP_Status_Anfahrhilfe_Cx1_Ein)}, range raw 0..1, transfer-property=PENDING  # Funktionsstatus des Berganfahrassistenten MQB: Auswertung im Getriebe zwecks Standabkopplung
          signal ESP_HDC_aktiv_XIX_ESC_50_XIX_E3V_K2CANFD: start 105, 1 bit, little-endian, data-type-policy=OVERRIDE, i-signal-type=PRIMITIVE, init-value=0, base-type=BT_ESP_HDC_aktiv, compu {0=Cx0_inaktiv (CM_ESP_HDC_aktiv_Cx0_inaktiv), 1=Cx1_aktiv (CM_ESP_HDC_aktiv_Cx1_aktiv)}, range raw 0..1, transfer-property=PENDING  # MQB und AU57x Allroad: Mit diesem Statusbit wird eine gerade aktive Regelung des Bergabfahrassistenten (Hill Descent Control) signalisiert.
          signal ESP_StartStopp_Info_XIX_ESC_50_XIX_E3V_K2CANFD: start 106, 2 bit, little-endian, data-type-policy=OVERRIDE, i-signal-type=PRIMITIVE, init-value=0, base-type=BT_ESP_StartStopp_Info, compu {0=Cx0_Motorlauf_nicht_notwendig_Stoppfreigabe (CM_ESP_StartStopp_Info_Cx0_Motorlauf_nicht_notwendig_Stoppfreigabe) (Motorlauf_nicht_notwendig_(Stoppfreigabe)), 1=Cx1_Motoranlauf_nicht_zwingend_notwendig_Stoppverbot_keine_Startanforderung (CM_ESP_StartStopp_Info_Cx1_Motoranlauf_nicht_zwingend_notwendig_Stoppverbot_keine_Startanforderung) (Motoranlauf_nicht_zwingend_notwendig_(Stoppverbot,keine_Startanforderung)), 2=Cx2_Motoranlauf_zwingend_notwendig_Startanforderung (CM_ESP_StartStopp_Info_Cx2_Motoranlauf_zwingend_notwendig_Startanforderung) (Motoranlauf_zwingend_notwendig_(Startanforderung)), 3=Cx3_Systemfehler (CM_ESP_StartStopp_Info_Cx3_Systemfehler)}, range raw 0..3, transfer-property=PENDING  # Stopp-Freigabe und Start-Anforderung an den Start-Stopp-Koordinator
          signal ESP_Eingr_HL_XIX_ESC_50_XIX_E3V_K2CANFD: start 108, 1 bit, little-endian, data-type-policy=OVERRIDE, i-signal-type=PRIMITIVE, init-value=0, base-type=BT_ESP_Eingr_HL, compu {0=Cx0_kein_Eingriff (CM_ESP_Eingr_HL_Cx0_kein_Eingriff), 1=Cx1_ESP_Eingriff_HL (CM_ESP_Eingr_HL_Cx1_ESP_Eingriff_HL)}, range raw 0..1, transfer-property=PENDING  # wird von QSP und Neigungsanzeige verwendet Flag wird vom ESP gesetzt, sobald aufgrund eines ESP-Eingriffs am Rad aktiv Druck aufgebaut wird. Frühestens mit öffnen des Ventils und spätestens bei einem Bremsmoment von 100Nm. Flag bleibt solange gesetzt wie ein Bremsmoment von mehr als 100Nm anliegt. QSP berücksichtigt diese Information zur Berechnung der eigenen v_ref
          signal ESP_Eingr_HR_XIX_ESC_50_XIX_E3V_K2CANFD: start 109, 1 bit, little-endian, data-type-policy=OVERRIDE, i-signal-type=PRIMITIVE, init-value=0, base-type=BT_ESP_Eingr_HR, compu {0=Cx0_kein_Eingriff (CM_ESP_Eingr_HR_Cx0_kein_Eingriff), 1=Cx1_ESP_Eingriff_HR (CM_ESP_Eingr_HR_Cx1_ESP_Eingriff_HR)}, range raw 0..1, transfer-property=PENDING  # wird von QSP und Neigungsanzeige verwendet Flag wird vom ESP gesetzt, sobald aufgrund eines ESP-Eingriffs am Rad aktiv Druck aufgebaut wird. Frühestens mit öffnen des Ventils und spätestens bei einem Bremsmoment von 100Nm. Flag bleibt solange gesetzt wie ein Bremsmoment von mehr als 100Nm anliegt. QSP berücksichtigt diese Information zur Berechnung der eigenen v_ref
          signal ESP_Eingr_VL_XIX_ESC_50_XIX_E3V_K2CANFD: start 110, 1 bit, little-endian, data-type-policy=OVERRIDE, i-signal-type=PRIMITIVE, init-value=0, base-type=BT_ESP_Eingr_VL, compu {0=Cx0_kein_Eingriff (CM_ESP_Eingr_VL_Cx0_kein_Eingriff), 1=Cx1_ESP_Eingriff_VL (CM_ESP_Eingr_VL_Cx1_ESP_Eingriff_VL)}, range raw 0..1, transfer-property=PENDING  # wird von QSP und Neigungsanzeige verwendet Flag wird vom ESP gesetzt, sobald aufgrund eines ESP-Eingriffs am Rad aktiv Druck aufgebaut wird. Frühestens mit öffnen des Ventils und spätestens bei einem Bremsmoment von 100Nm. Flag bleibt solange gesetzt wie ein Bremsmoment von mehr als 100Nm anliegt. QSP berücksichtigt diese Information zur Berechnung der eigenen v_ref
          signal ESP_Eingr_VR_XIX_ESC_50_XIX_E3V_K2CANFD: start 111, 1 bit, little-endian, data-type-policy=OVERRIDE, i-signal-type=PRIMITIVE, init-value=0, base-type=BT_ESP_Eingr_VR, compu {0=Cx0_kein_Eingriff (CM_ESP_Eingr_VR_Cx0_kein_Eingriff), 1=Cx1_ESP_Eingriff_VR (CM_ESP_Eingr_VR_Cx1_ESP_Eingriff_VR)}, range raw 0..1, transfer-property=PENDING  # wird von QSP und Neigungsanzeige verwendet Flag wird vom ESP gesetzt, sobald aufgrund eines ESP-Eingriffs am Rad aktiv Druck aufgebaut wird. Frühestens mit öffnen des Ventils und spätestens bei einem Bremsmoment von 100Nm. Flag bleibt solange gesetzt wie ein Bremsmoment von mehr als 100Nm anliegt. QSP berücksichtigt diese Information zur Berechnung der eigenen v_ref
          signal ESP_BKV_Unterdruck_XIX_ESC_50_XIX_E3V_K2CANFD: start 112, 8 bit, little-endian, data-type-policy=OVERRIDE, i-signal-type=PRIMITIVE, init-value=254, base-type=BT_ESP_BKV_Unterdruck, invalid-value=Invalid_ESP_BKV_Unterdruck_XIX_ESC_50_XIX_E3V_K2CANFD:255, compu {0=Cx0_nicht_verbaut_oder_nicht_kodiert (CM_ESP_BKV_Unterdruck_Cx0_nicht_verbaut_oder_nicht_kodiert), phys=raw*4 for raw 1..253, 254=Cxfe_Init (CM_ESP_BKV_Unterdruck_Cxfe_Init), 255=Cxff_Fehler (CM_ESP_BKV_Unterdruck_Cxff_Fehler); unit Unit_MilliBar}, range phys 4..1012 Unit_MilliBar, raw 0..255, unit=Unit_MilliBar, transfer-property=PENDING  # Der maximale Wert wird auf 1012 mbar begrenzt. Dieses Signal wird im AU64x nicht unterstützt. Hinweis: Auch bei nicht verbautem BKV-Unterdrucksensor könnte während der Initialisierung der Initialisierungswert gesendet werden.
          signal ESP_Autohold_aktiv_XIX_ESC_50_XIX_E3V_K2CANFD: start 120, 1 bit, little-endian, data-type-policy=OVERRIDE, i-signal-type=PRIMITIVE, init-value=0, base-type=BT_ESP_Autohold_aktiv, compu {0=Cx0_Autohold_inaktiv (CM_ESP_Autohold_aktiv_Cx0_Autohold_inaktiv), 1=Cx1_Autohold_aktiv (CM_ESP_Autohold_aktiv_Cx1_Autohold_aktiv)}, range raw 0..1, transfer-property=PENDING  # Rückmeldung an EPB, dass Autohold aktiv ist.
          signal ESP_FStatus_Anfahrhilfe_XIX_ESC_50_XIX_E3V_K2CANFD: start 121, 1 bit, little-endian, data-type-policy=OVERRIDE, i-signal-type=PRIMITIVE, init-value=0, base-type=BT_ESP_FStatus_Anfahrhilfe, invalid-value=Invalid_ESP_FStatus_Anfahrhilfe_XIX_ESC_50_XIX_E3V_K2CANFD:1, compu {0=Cx0_kein_Fehler (CM_ESP_FStatus_Anfahrhilfe_Cx0_kein_Fehler), 1=Cx1_Fehler (CM_ESP_FStatus_Anfahrhilfe_Cx1_Fehler)}, range raw 0..1, transfer-property=PENDING  # Bei gesetztem Bit steht die Funktion Berganfahrassistent (Hillhold) nicht zur Verfügung
          signal ESP_Verz_EPB_aktiv_XIX_ESC_50_XIX_E3V_K2CANFD: start 122, 1 bit, little-endian, data-type-policy=OVERRIDE, i-signal-type=PRIMITIVE, init-value=0, base-type=BT_ESP_Verz_EPB_aktiv, compu {0=Cx0_nicht_aktiviert (CM_ESP_Verz_EPB_aktiv_Cx0_nicht_aktiviert), 1=Cx1_aktiviert (CM_ESP_Verz_EPB_aktiv_Cx1_aktiviert)}, range raw 0..1, transfer-property=PENDING  # Bei gesetztem Bit wird die Verzögerungsanforderung von EPB umgesetzt.
          signal ECD_Bremslicht_XIX_ESC_50_XIX_E3V_K2CANFD: start 123, 1 bit, little-endian, data-type-policy=OVERRIDE, i-signal-type=PRIMITIVE, init-value=0, base-type=BT_ECD_Bremslicht, compu {0=Cx0_Aus (CM_ECD_Bremslicht_Cx0_Aus), 1=Cx1_Ein (CM_ECD_Bremslicht_Cx1_Ein)}, range raw 0..1, transfer-property=PENDING  # Bremslichtansteuerung durch ECD-Funktion
          signal ESP_Verzoeg_EPB_verf_XIX_ESC_50_XIX_E3V_K2CANFD: start 124, 1 bit, little-endian, data-type-policy=OVERRIDE, i-signal-type=PRIMITIVE, init-value=0, base-type=BT_ESP_Verzoeg_EPB_verf, compu {0=Cx0_nicht_verfuegbar (CM_ESP_Verzoeg_EPB_verf_Cx0_nicht_verfuegbar), 1=Cx1_System_verfuegbar (CM_ESP_Verzoeg_EPB_verf_Cx1_System_verfuegbar)}, range raw 0..1, transfer-property=PENDING  # Bei gesetztem Bit ist der Verzögerungsregeler für EPB verfügbar.
          signal ESP_Status_Bremsdruck_XIX_ESC_50_XIX_E3V_K2CANFD: start 125, 1 bit, little-endian, data-type-policy=OVERRIDE, i-signal-type=PRIMITIVE, init-value=0, base-type=BT_ESP_Status_Bremsdruck, compu {0=Cx0_Bremse_drucklos (CM_ESP_Status_Bremsdruck_Cx0_Bremse_drucklos), 1=Cx1_mit_Bremsdruck (CM_ESP_Status_Bremsdruck_Cx1_mit_Bremsdruck)}, range raw 0..1, transfer-property=PENDING  # MLB: Bei gesetztem Bit liegt p > ca. 2 bar an, hervorgerufen durch Fahrer, ASR, FZR, ECD, Bremsregler ... bei Abfall des Bits ist p < X bar, bei aktivem ECD-Eingriff Ende des Eingriffs Weiterführende Informationen im Lastenheft spezifiziert und in der entsprechenden Fachabteilung zu erfragen.
          signal ESP_Anforderung_EPB_XIX_ESC_50_XIX_E3V_K2CANFD: start 126, 2 bit, little-endian, data-type-policy=OVERRIDE, i-signal-type=PRIMITIVE, init-value=0, base-type=BT_ESP_Anforderung_EPB, compu {0=Cx0_keine_Anforderung (CM_ESP_Anforderung_EPB_Cx0_keine_Anforderung), 1=Cx1_Anforderung_Oeffnen (CM_ESP_Anforderung_EPB_Cx1_Anforderung_Oeffnen), 2=Cx2_Anforderung_Schliessen (CM_ESP_Anforderung_EPB_Cx2_Anforderung_Schliessen), 3=Cx3_reserviert (CM_ESP_Anforderung_EPB_Cx3_reserviert)}, range raw 0..3, transfer-property=PENDING  # ESP fordert von der EPB Öffnen bzw. Schliessen an. Notwendig wegen Autohold-Funktion.
          signal ESC_Fahrerradbremswunschmoment_XIX_ESC_50_XIX_E3V_K2CANFD: start 128, 12 bit, little-endian, data-type-policy=OVERRIDE, i-signal-type=PRIMITIVE, init-value=4094, base-type=BT_ESC_Fahrerradbremswunschmoment, invalid-value=Invalid_ESC_Fahrerradbremswunschmoment_XIX_ESC_50_XIX_E3V_K2CANFD:4095, compu {phys=raw*6-2400 for raw 0..4093, 4094=Cxffe_Init (CM_ESC_Fahrerradbremswunschmoment_Cxffe_Init), 4095=Cxfff_Fehler (CM_ESC_Fahrerradbremswunschmoment_Cxfff_Fehler); unit Unit_NewtoMeter}, range phys -2400..22158 Unit_NewtoMeter, raw 0..4095, unit=Unit_NewtoMeter, transfer-property=PENDING  # Berechnetes Moment anhand des eBKV-Ausgangsstangenwegs, THZ-Druck, cp-Faktoren der Bremsen und Bremspedalbetätigung. Reku nicht aktiv--> entspricht dem berechneten Moment auf Basis THZ-Druck; Reku aktiv --> entspricht dem berechneten Moment auf Basis virtueller Bremsdruck; Fahrer ist bremsdruckbestimmend --> gewünschtes Moment; Fahrerradbremswunschmoment nicht bestimmbar -> Fahrerbremswunsch = init
          signal ESP_ANB_CM_Rueckk_Umsetz_XIX_ESC_50_XIX_E3V_K2CANFD: start 140, 1 bit, little-endian, data-type-policy=OVERRIDE, i-signal-type=PRIMITIVE, init-value=0, base-type=BT_ESP_ANB_CM_Rueckk_Umsetz, compu {0=Cx0_keine_Ausfuehrung (CM_ESP_ANB_CM_Rueckk_Umsetz_Cx0_keine_Ausfuehrung), 1=Cx1_Ausfuehrung (CM_ESP_ANB_CM_Rueckk_Umsetz_Cx1_Ausfuehrung)}, range raw 0..1, transfer-property=PENDING  # Das Signal dient als Rückmeldung zum ACC, dass eine angeforderte ANB-CM durchgeführt wird. Die positive Rückmeldung löst u.a. eine entsprechende Fahrerinformation im Kombiinstrument aus
          signal ESP_Konsistenz_ACC_Botschaft_XIX_ESC_50_XIX_E3V_K2CANFD: start 141, 1 bit, little-endian, data-type-policy=OVERRIDE, i-signal-type=PRIMITIVE, init-value=0, base-type=BT_ESP_Konsistenz_ACC_Botschaft, compu {0=Cx0_Botschaft_fuer_ACC_konsistent (CM_ESP_Konsistenz_ACC_Botschaft_Cx0_Botschaft_fuer_ACC_konsistent), 1=Cx1_Botschaft_fuer_ACC_nicht_konsistent (CM_ESP_Konsistenz_ACC_Botschaft_Cx1_Botschaft_fuer_ACC_nicht_konsistent)}, range raw 0..1, transfer-property=PENDING  # Rückmeldung zum Sender der Verzögerungsanforderung ACC bezüglich Prüfung CHK/CRC, BZ und langer Timeout. Wird auch gesetzt bei einer Verzögerungsanforderung größer als eine applizierbare Schwelle. Im D4/C7: Botschaft ACC_05 Im MQB: Botschaft ACC_07
          signal ESP_Stillstandsphase_erschoepft_XIX_ESC_50_XIX_E3V_K2CANFD: start 142, 1 bit, little-endian, data-type-policy=OVERRIDE, i-signal-type=PRIMITIVE, init-value=0, base-type=BT_ESP_Stillstandsphase_erschoepft, compu {0=Cx0_sicheres_Halten_moeglich (CM_ESP_Stillstandsphase_erschoepft_Cx0_sicheres_Halten_moeglich), 1=Cx1_kein_sicheres_Halten_moeglich (CM_ESP_Stillstandsphase_erschoepft_Cx1_kein_sicheres_Halten_moeglich)}, range raw 0..1, transfer-property=PENDING  # Rückmeldung vom ESP, dass eine angefordertes sicheres Halten im Stillstand nicht mehr länger möglich ist.
          signal ESP_ZT_Rueckk_Umsetz_XIX_ESC_50_XIX_E3V_K2CANFD: start 143, 1 bit, little-endian, data-type-policy=OVERRIDE, i-signal-type=PRIMITIVE, init-value=0, base-type=BT_ESP_ZT_Rueckk_Umsetz, compu {0=Cx0_keine_Ausfuehrung (CM_ESP_ZT_Rueckk_Umsetz_Cx0_keine_Ausfuehrung), 1=Cx1_Ausfuehrung (CM_ESP_ZT_Rueckk_Umsetz_Cx1_Ausfuehrung)}, range raw 0..1, transfer-property=PENDING  # Das Signal dient als Rückmeldung zum ACC, dass eine angeforderte Zielbremsung/Teilbremsung durchgeführt wird. Die positive Rückmeldung löst u.a. eine entsprechende Fahrerinformation im Kombiinstrument aus
          signal ESP_Tuerkontakt_Fahrertuer_XIX_ESC_50_XIX_E3V_K2CANFD: start 144, 1 bit, little-endian, data-type-policy=OVERRIDE, i-signal-type=PRIMITIVE, init-value=0, base-type=BT_ESP_Tuerkontakt_Fahrertuer, compu {0=Cx0_Schalter_geschlossen (CM_ESP_Tuerkontakt_Fahrertuer_Cx0_Schalter_geschlossen), 1=Cx1_Schalter_offen (CM_ESP_Tuerkontakt_Fahrertuer_Cx1_Schalter_offen)}, range raw 0..1, transfer-property=PENDING  # Logischer Pegel der HW-Leitung zum Türkontaktschalter im ESP-SG. 0 > Schalter geschlossen 1 > Schalter offen Ungefilterter und unplausibilisierter Status der HW-Leitung vom Fahrertür-Türkontaktschalter zum ESP. Redundanz für Systemsicherheit notwendig für den Fall des autonomen Anfahrens im Rahmen der ACC-Stop&Go -Funktion. Im MQB wird das Signal nicht unterstützt!
          signal ESP_Abrutschen_Stillstand_XIX_ESC_50_XIX_E3V_K2CANFD: start 146, 1 bit, little-endian, data-type-policy=OVERRIDE, i-signal-type=PRIMITIVE, init-value=0, base-type=BT_ESP_Abrutschen_Stillstand, compu {0=Cx0_kein_Abrutschen_erkannt (CM_ESP_Abrutschen_Stillstand_Cx0_kein_Abrutschen_erkannt), 1=Cx1_Abrutschen_erkannt (CM_ESP_Abrutschen_Stillstand_Cx1_Abrutschen_erkannt)}, range raw 0..1, transfer-property=PENDING  # Das ESP teilt über dieses Bit mit, dass ein Abrutschen im Stillstand erkannt wurde. Im MQB wird das Signal nicht unterstützt!
          signal ESP_Fahrer_tritt_ZBR_Schw_XIX_ESC_50_XIX_E3V_K2CANFD: start 147, 1 bit, little-endian, data-type-policy=OVERRIDE, i-signal-type=PRIMITIVE, init-value=0, base-type=BT_ESP_Fahrer_tritt_ZBR_Schw, compu {0=Cx0_Fahrer_uebertritt_ZBR_Schwelle_nicht (CM_ESP_Fahrer_tritt_ZBR_Schw_Cx0_Fahrer_uebertritt_ZBR_Schwelle_nicht), 1=Cx1_Fahrer_uebertritt_ZBR_Schwelle (CM_ESP_Fahrer_tritt_ZBR_Schw_Cx1_Fahrer_uebertritt_ZBR_Schwelle)}, range raw 0..1, transfer-property=PENDING  # Rückmeldung des ESP an AWV, ob der Fahrer die aktuell gültige ZBR-Schwelle übertritt
          signal ESP_Systemstatus_03_XIX_ESC_50_XIX_E3V_K2CANFD: start 148, 2 bit, little-endian, data-type-policy=OVERRIDE, i-signal-type=PRIMITIVE, init-value=2, base-type=BT_ESP_Systemstatus_03, invalid-value=Invalid_ESP_Systemstatus_03_XIX_ESC_50_XIX_E3V_K2CANFD:3, compu {0=Cx0_ESC_passiv_getastet (CM_ESP_Systemstatus_03_Cx0_ESC_passiv_getastet), 1=Cx1_ESC_Schwellen_geaendert (CM_ESP_Systemstatus_03_Cx1_ESC_Schwellen_geaendert), 2=Cx2_ESC_aktiviert (CM_ESP_Systemstatus_03_Cx2_ESC_aktiviert), 3=Cx3_Fehler (CM_ESP_Systemstatus_03_Cx3_Fehler)}, range raw 0..3, transfer-property=PENDING  # ESC-Status für Datenablage im EDR
          signal ASR_Systemstatus_XIX_ESC_50_XIX_E3V_K2CANFD: start 150, 2 bit, little-endian, data-type-policy=OVERRIDE, i-signal-type=PRIMITIVE, init-value=2, base-type=BT_ASR_Systemstatus, compu {0=Cx0_ASR_passiv_getastet (CM_ASR_Systemstatus_Cx0_ASR_passiv_getastet), 1=Cx1_ASR_Schwellen_geaendert (CM_ASR_Systemstatus_Cx1_ASR_Schwellen_geaendert), 2=Cx2_ASR_aktiviert (CM_ASR_Systemstatus_Cx2_ASR_aktiviert), 3=Cx3_ASR_Stoerung (CM_ASR_Systemstatus_Cx3_ASR_Stoerung)}, range raw 0..3, transfer-property=PENDING  # ASR-Systemstatus für Datenablage im EDR
          signal ESP_QBit_v_ref_XIX_ESC_50_XIX_E3V_K2CANFD: start 169, 1 bit, little-endian, data-type-policy=OVERRIDE, i-signal-type=PRIMITIVE, init-value=1, base-type=BT_ESP_QBit_v_ref, compu {0=Cx0_gueltiger_Wert (CM_ESP_QBit_v_ref_Cx0_gueltiger_Wert), 1=Cx1_Ersatz_Init_oder_Fehlerwert (CM_ESP_QBit_v_ref_Cx1_Ersatz_Init_oder_Fehlerwert)}, range raw 0..1, transfer-property=PENDING  # QBit der Referenzgeschwindigkeit ESP_v_ref. Gesetzt bei Ersatzwert, Init oder Fehler. Detailinformationen zu dem Signal sind dem Lastenheft 'Signalexport - Funktionale Anforderungen an ESP' zu entnehmen - Signal ESP_St_v_fzg_ref
          signal ESP_v_ref_Fahrtrichtung_XIX_ESC_50_XIX_E3V_K2CANFD: start 170, 2 bit, little-endian, data-type-policy=OVERRIDE, i-signal-type=PRIMITIVE, init-value=0, base-type=BT_ESP_v_ref_Fahrtrichtung, compu {0=Cx0_Fahrtrichtung_nicht_definiert (CM_ESP_v_ref_Fahrtrichtung_Cx0_Fahrtrichtung_nicht_definiert), 1=Cx1_Vorwaerts (CM_ESP_v_ref_Fahrtrichtung_Cx1_Vorwaerts), 2=Cx2_Rueckwaerts (CM_ESP_v_ref_Fahrtrichtung_Cx2_Rueckwaerts), 3=Cx3_Stillstand (CM_ESP_v_ref_Fahrtrichtung_Cx3_Stillstand)}, range raw 0..3, transfer-property=PENDING  # Signal stellt die Informationen über die Fahrtrichtung des Fahrzeuges dar. Sie wird als Vorzeichen der Referenzgeschwindigkeit ESP_v_ref interpretiert und basiert auf den Drehrichtungen der Räder. Detailinformationen zu dem Signal sind dem Lastenheft 'Signalexport - Funktionale Anforderungen an ESP' zu entnehmen - Signal ESP_V_fzg_ref_FR.
          signal ESC_Bremsdruckgradient_XIX_ESC_50_XIX_E3V_K2CANFD: start 172, 8 bit, little-endian, data-type-policy=OVERRIDE, i-signal-type=PRIMITIVE, init-value=254, base-type=BT_ESC_Bremsdruckgradient, invalid-value=Invalid_ESC_Bremsdruckgradient_XIX_ESC_50_XIX_E3V_K2CANFD:255, compu {phys=raw*10 for raw 0..250, 251=Cxfb_groesser_2500_bar_per_sec (CM_ESC_Bremsdruckgradient_Cxfb_groesser_2500_bar_per_sec), 254=Cxfe_Init (CM_ESC_Bremsdruckgradient_Cxfe_Init), 255=Cxff_Fehler (CM_ESC_Bremsdruckgradient_Cxff_Fehler); unit Unit_BarPerSecon}, range phys 0..2500 Unit_BarPerSecon, raw 0..255, unit=Unit_BarPerSecon, transfer-property=PENDING  # Das Signal zeigt den vom Fahrer gedruckten Bremsdruckgradienten
          signal ESP_v_ref_XIX_ESC_50_XIX_E3V_K2CANFD: start 180, 12 bit, little-endian, data-type-policy=OVERRIDE, i-signal-type=PRIMITIVE, init-value=4094, base-type=BT_ESP_v_ref, invalid-value=Invalid_ESP_v_ref_XIX_ESC_50_XIX_E3V_K2CANFD:4095, compu {phys=raw*0.125 for raw 0..4092, 4093=Cxffd_Unterspannung (CM_ESP_v_ref_Cxffd_Unterspannung), 4094=Cxffe_Init (CM_ESP_v_ref_Cxffe_Init), 4095=Cxfff_Fehler (CM_ESP_v_ref_Cxfff_Fehler); unit Unit_KiloMeterPerHour}, range phys 0..511.5 Unit_KiloMeterPerHour, raw 0..4095, unit=Unit_KiloMeterPerHour, transfer-property=PENDING  # MLBevo: Signal wird nur von einem BOSCH ESP System zur Verfügung gestellt. Exklusives Signal vom BOSCH ESP zum BOSCH Airbag für ROSEII Funktion und für Fahrwerkregelsysteme. Verwendung nur nach vorheriger Abstimmung mit den verantwortlichen EF Fachbereichen der Häuser (Audi I/EF-8, PAG EFF6, VW EFBS). Detailinformationen zu dem Signal sind dem Lastenheft 'Signalexport - Funktionale Anforderungen an ESP' zu entnehmen - Signal ESP_V_fzg_ref. MLB: Exklusives Signal vom BOSCH ESP zum BOSCH Airbag für ROSEII Funktion, nicht für andere Empfänger! MQB: Zusätzliches v-Signal als Referenzgeschwindigkeit für die Funktion Fußgängerschutz. Ausgabe der berechneten Geschwindigkeit "über Grund", d. h. auf Prüfständen Null, im Blockierfall der Räder aber ungleich Null.
          signal ESP_HBA_Empfindlichkeit_XIX_ESC_50_XIX_E3V_K2CANFD: start 220, 3 bit, little-endian, data-type-policy=OVERRIDE, i-signal-type=PRIMITIVE, init-value=0, base-type=BT_ESP_HBA_Empfindlichkeit, invalid-value=Invalid_ESP_HBA_Empfindlichkeit_XIX_ESC_50_XIX_E3V_K2CANFD:7, compu {0=Cx0_Init (CM_ESP_HBA_Empfindlichkeit_Cx0_Init), 1=Cx1_unempfindlich (CM_ESP_HBA_Empfindlichkeit_Cx1_unempfindlich), 2=Cx2_normal (CM_ESP_HBA_Empfindlichkeit_Cx2_normal), 3=Cx3_empfindlich (CM_ESP_HBA_Empfindlichkeit_Cx3_empfindlich), 4=Cx4_sehr_empfindlich (CM_ESP_HBA_Empfindlichkeit_Cx4_sehr_empfindlich), 5=Cx5_reserviert (CM_ESP_HBA_Empfindlichkeit_Cx5_reserviert), 6=Cx6_reserviert (CM_ESP_HBA_Empfindlichkeit_Cx6_reserviert), 7=Cx7_Fehler (CM_ESP_HBA_Empfindlichkeit_Cx7_Fehler)}, range raw 0..7, transfer-property=PENDING  # Signal gibt die aktuell gültige Auslöseempfindlichkeit des Hydraulischen Bremsassistenten an
          signal ESC_Hydr_Fkt_aktiv_XIX_ESC_50_XIX_E3V_K2CANFD: start 223, 2 bit, little-endian, data-type-policy=OVERRIDE, i-signal-type=PRIMITIVE, init-value=0, base-type=BT_ESC_Hydr_Fkt_aktiv, compu {0=Cx0_keine_Aktivitaet (CM_ESC_Hydr_Fkt_aktiv_Cx0_keine_Aktivitaet), 1=Cx1_ESC_Druckaufbau_HBx_HFC_aktiv (CM_ESC_Hydr_Fkt_aktiv_Cx1_ESC_Druckaufbau_HBx_HFC_aktiv), 2=Cx2_Warnrucklevel_Summand_1 (CM_ESC_Hydr_Fkt_aktiv_Cx2_Warnrucklevel_Summand_1), 3=Cx3_Warnrucklevel_Summand_3 (CM_ESC_Hydr_Fkt_aktiv_Cx3_Warnrucklevel_Summand_3)}, range raw 0..3, transfer-property=PENDING  # Info über die Aktivität von Druckaufbaufunktionen im ESC und Uebermittlung des Warnlevel an EBKV.
          signal ESC_QBit_Fahrerbremswunsch_XIX_ESC_50_XIX_E3V_K2CANFD: start 225, 1 bit, little-endian, data-type-policy=OVERRIDE, i-signal-type=PRIMITIVE, init-value=1, base-type=BT_ESC_QBit_Fahrerbremswunsch, compu {0=Cx0_gueltiger_Wert (CM_ESC_QBit_Fahrerbremswunsch_Cx0_gueltiger_Wert), 1=Cx1_Ersatz_Init_oder_Fehlerwert (CM_ESC_QBit_Fahrerbremswunsch_Cx1_Ersatz_Init_oder_Fehlerwert)}, range raw 0..1, transfer-property=PENDING  # Gesetzt bei Ersatzwert, Init oder Fehler.
          signal ESC_Fahrerbremswunsch_XIX_ESC_50_XIX_E3V_K2CANFD: start 226, 10 bit, little-endian, data-type-policy=OVERRIDE, i-signal-type=PRIMITIVE, init-value=100, base-type=BT_ESC_Fahrerbremswunsch, invalid-value=Invalid_ESC_Fahrerbremswunsch_XIX_ESC_50_XIX_E3V_K2CANFD:1023, compu {phys=raw*0.3-30 for raw 0..1022, 1023=Cx3ff_Fehler (CM_ESC_Fahrerbremswunsch_Cx3ff_Fehler); unit Unit_Bar}, range phys -30..276.6 Unit_Bar, raw 0..1023, unit=Unit_Bar, transfer-property=PENDING  # PHEV: Berechneter Druck anhand des eBKV-Ausgangsstangenwegs sowie ESP-pMC. Reku nicht aktiv--> vergleichbar mit ESP_Bremsdruck; Reku aktiv --> virtueller Bremsdruck Konv.: entspricht ESP_Bremsdruck
          signal ESCGeneratorSollMoment_XIX_ESC_50_XIX_E3V_K2CANFD: start 236, 12 bit, little-endian, data-type-policy=OVERRIDE, i-signal-type=PRIMITIVE, init-value=4094, base-type=BT_ESCGeneratorSollMoment, invalid-value=Invalid_ESCGeneratorSollMoment_XIX_ESC_50_XIX_E3V_K2CANFD:4095, compu {phys=raw*3-12279 for raw 0..4093, 4094=Cxffe_Init (CM_ESCGeneratorSollMoment_Cxffe_Init), 4095=Cxfff_Fehler (CM_ESCGeneratorSollMoment_Cxfff_Fehler)}, range phys -12279..0, raw 0..4095, transfer-property=PENDING  # In MLBevo Faktor in TS_Faktor_Radmomente beachten! Verzögernd wirkender Antriebsstrangsollmomentenanteil aus Bremspedalbetätigung auf Summenradebene.
          signal ESC_Raddruck_max_XIX_ESC_50_XIX_E3V_K2CANFD: start 248, 8 bit, little-endian, data-type-policy=OVERRIDE, i-signal-type=PRIMITIVE, init-value=254, base-type=BT_ESC_Raddruck_max, invalid-value=Invalid_ESC_Raddruck_max_XIX_ESC_50_XIX_E3V_K2CANFD:255, compu {phys=raw for raw 0..250, 254=Cxfe_Init (CM_ESC_Raddruck_max_Cxfe_Init), 255=Cxff_Fehler (CM_ESC_Raddruck_max_Cxff_Fehler); unit Unit_Bar}, range phys 0..250 Unit_Bar, raw 0..255, unit=Unit_Bar, transfer-property=PENDING  # Stellt den zahlenmäßig höchsten Druckwert der vier modellierten Raddrücke dar.
          signal EPB_QBit_Pedalweg_Kuppl_XIX_ESC_50_XIX_E3V_K2CANFD: start 269, 1 bit, little-endian, data-type-policy=OVERRIDE, i-signal-type=PRIMITIVE, init-value=1, base-type=BT_EPB_QBit_Pedalweg_Kuppl, compu {0=Cx0_gueltiger_Wert (CM_EPB_QBit_Pedalweg_Kuppl_Cx0_gueltiger_Wert) (gültiger Wert), 1=Cx1_Ersatz_Init_oder_Fehlerwert (CM_EPB_QBit_Pedalweg_Kuppl_Cx1_Ersatz_Init_oder_Fehlerwert) (Ersatz-, Init- oder Fehlerwert)}, range raw 0..1, transfer-property=PENDING
          signal EPB_Freig_Verzoeg_Anf_XIX_ESC_50_XIX_E3V_K2CANFD: start 271, 1 bit, little-endian, data-type-policy=OVERRIDE, i-signal-type=PRIMITIVE, init-value=0, base-type=BT_EPB_Freig_Verzoeg_Anf, compu {0=Cx0_nicht_freigegeben (CM_EPB_Freig_Verzoeg_Anf_Cx0_nicht_freigegeben) (nicht freigegeben), 1=Cx1_freigegeben (CM_EPB_Freig_Verzoeg_Anf_Cx1_freigegeben)}, range raw 0..1, transfer-property=PENDING  # Verzögerungsanforderung
          signal EPB_Verzoeg_Anf_XIX_ESC_50_XIX_E3V_K2CANFD: start 272, 8 bit, little-endian, data-type-policy=OVERRIDE, i-signal-type=PRIMITIVE, init-value=166, base-type=BT_EPB_Verzoeg_Anf, compu {phys=raw*0.048-7.968 for raw 0..254; unit Unit_MeterPerSeconSquar}, range phys -7.968..4.224 Unit_MeterPerSeconSquar, raw 0..254, unit=Unit_MeterPerSeconSquar, transfer-property=PENDING  # Steuerungsanforderung an andere Systeme (z.B. ESP), um während der Fahrt, durch den Handbremsschalter ausgelöst, zu bremsen (ECD-Funktion)
          signal EPB_Pedalweg_Kuppl_XIX_ESC_50_XIX_E3V_K2CANFD: start 288, 8 bit, little-endian, data-type-policy=OVERRIDE, i-signal-type=PRIMITIVE, init-value=0, base-type=BT_EPB_Pedalweg_Kuppl, invalid-value=Invalid_EPB_Pedalweg_Kuppl_XIX_ESC_50_XIX_E3V_K2CANFD:255, compu {0=Cx0_Init (CM_EPB_Pedalweg_Kuppl_Cx0_Init), phys=raw*0.4 for raw 20..230, 255=Cxff_Fehler (CM_EPB_Pedalweg_Kuppl_Cxff_Fehler); unit Unit_PerCent}, range phys 8..92 Unit_PerCent, raw 0..255, unit=Unit_PerCent, transfer-property=PENDING  # Signal entspricht Tastverhältnis des PWM. Gesamtweg Kupplungspedal 10% bis 90%, damit zu erwartende Werte 25 bis 225. 25 bei Kupplungspedal nicht getreten, 225 bei Kupplungspedal voll durchgetreten. 2% Toleranz wird im Wertebereich ermöglicht (8%-92%). 0x00 = Init 0xFF = Fehler mit Fehlereintrag im Steuergerät
          signal EPB_DAA_Randbed_erf_XIX_ESC_50_XIX_E3V_K2CANFD: start 305, 1 bit, little-endian, data-type-policy=OVERRIDE, i-signal-type=PRIMITIVE, init-value=0, base-type=BT_EPB_DAA_Randbed_erf, compu {0=Cx0_Randbed_nicht_erfuellt (CM_EPB_DAA_Randbed_erf_Cx0_Randbed_nicht_erfuellt), 1=Cx1_Randbed_erfuellt (CM_EPB_DAA_Randbed_erf_Cx1_Randbed_erfuellt)}, range raw 0..1, transfer-property=PENDING  # Die Randbedingungen zum automatischen Öffnen der EPB (Funktion DAA) sind erfüllt und ein Betätigen des Fahrpedals führt zum Öffnen der EPB.
          signal EPB_Fehlerstatus_02_XIX_ESC_50_XIX_E3V_K2CANFD: start 306, 2 bit, little-endian, data-type-policy=OVERRIDE, i-signal-type=PRIMITIVE, init-value=0, base-type=BT_EPB_Fehlerstatus_02, compu {0=Cx0_kein_Fehler (CM_EPB_Fehlerstatus_02_Cx0_kein_Fehler), 1=Cx1_Fehler_ausserhalb_apply_release (CM_EPB_Fehlerstatus_02_Cx1_Fehler_ausserhalb_apply_release), 2=Cx2_Fehler_einseitig_apply_release (CM_EPB_Fehlerstatus_02_Cx2_Fehler_einseitig_apply_release), 3=Cx3_Fehler_beidseitig_apply_release (CM_EPB_Fehlerstatus_02_Cx3_Fehler_beidseitig_apply_release)}, range raw 0..3, transfer-property=PENDING  # Anpassung der Texte an die aktuellen Zustände für weitergehende Funktionen (Stillstandsmanager)
          signal EPB_Schalterposition_XIX_ESC_50_XIX_E3V_K2CANFD: start 308, 2 bit, little-endian, data-type-policy=OVERRIDE, i-signal-type=PRIMITIVE, init-value=0, base-type=BT_EPB_Schalterposition, invalid-value=Invalid_EPB_Schalterposition_XIX_ESC_50_XIX_E3V_K2CANFD:3, compu {0=Cx0_keine_Fahreranforderung (CM_EPB_Schalterposition_Cx0_keine_Fahreranforderung) (keine Fahreranforderung), 1=Cx1_Fahreranforderung_oeffnen (CM_EPB_Schalterposition_Cx1_Fahreranforderung_oeffnen) (Fahreranforderung Öffnen), 2=Cx2_Fahreranforderung_Schliessen (CM_EPB_Schalterposition_Cx2_Fahreranforderung_Schliessen) (Fahreranforderung Schließen), 3=Cx3_Fehler (CM_EPB_Schalterposition_Cx3_Fehler)}, range raw 0..3, transfer-property=PENDING  # Spiegelt die Schalterstellung wieder. 0x3 = Schalterfehler
          signal EPB_QBit_Schalterpos_XIX_ESC_50_XIX_E3V_K2CANFD: start 310, 1 bit, little-endian, data-type-policy=OVERRIDE, i-signal-type=PRIMITIVE, init-value=1, base-type=BT_EPB_QBit_Schalterpos, compu {0=Cx0_gueltiger_Wert_volle_Funktion (CM_EPB_QBit_Schalterpos_Cx0_gueltiger_Wert_volle_Funktion) (gültiger Wert (volle Funktion)), 1=Cx1_Ersatz_Init_oder_Fehlerwert_Schalter_ausser_Funktion (CM_EPB_QBit_Schalterpos_Cx1_Ersatz_Init_oder_Fehlerwert_Schalter_ausser_Funktion) (Ersatz-, Init- oder Fehlerwert (Schalter ausser Funktion))}, range raw 0..1, transfer-property=PENDING
          signal EPB_Spannkraft_XIX_ESC_50_XIX_E3V_K2CANFD: start 312, 5 bit, little-endian, data-type-policy=OVERRIDE, i-signal-type=PRIMITIVE, init-value=30, base-type=BT_EPB_Spannkraft, invalid-value=Invalid_EPB_Spannkraft_XIX_ESC_50_XIX_E3V_K2CANFD:31, compu {phys=raw for raw 0..29, 30=Cx1e_Init (CM_EPB_Spannkraft_Cx1e_Init), 31=Cx1f_Fehler (CM_EPB_Spannkraft_Cx1f_Fehler); unit Unit_KiloNewto}, range phys 0..29 Unit_KiloNewto, raw 0..31, unit=Unit_KiloNewto, transfer-property=PENDING  # Erzeugte Spannkraft. Bezieht sich auf die Aktuatoren. MQB: Spannkraftwerte entsprechen nicht den tatsächlichen Spannkräften. Genauere Informationen bitte in der Fachabteilung erfragen!
          signal EPB_Status_02_XIX_ESC_50_XIX_E3V_K2CANFD: start 317, 3 bit, little-endian, data-type-policy=OVERRIDE, i-signal-type=PRIMITIVE, init-value=6, base-type=BT_EPB_Status_02, compu {0=Cx0_offen (CM_EPB_Status_02_Cx0_offen), 1=Cx1_geschlossen_Parken (CM_EPB_Status_02_Cx1_geschlossen_Parken), 2=Cx2_teilgespannt_Halten (CM_EPB_Status_02_Cx2_teilgespannt_Halten), 3=Cx3_im_Lauf_oeffnen (CM_EPB_Status_02_Cx3_im_Lauf_oeffnen), 4=Cx4_im_Lauf_schliessen (CM_EPB_Status_02_Cx4_im_Lauf_schliessen), 5=Cx5_tbd (CM_EPB_Status_02_Cx5_tbd), 6=Cx6_Init (CM_EPB_Status_02_Cx6_Init), 7=Cx7_unbekannt (CM_EPB_Status_02_Cx7_unbekannt)}, range raw 0..7, transfer-property=PENDING, to SAM(timeout 0.5 s)  # Erweiterung der Zustände um ein genaueres Bild des aktuellen Zustandes zu erhalten für weitergehende Funktionen ( Stillstandsmanager)
          signal EPB_Status_XIX_ESC_50_XIX_E3V_K2CANFD: start 320, 2 bit, little-endian, data-type-policy=OVERRIDE, i-signal-type=PRIMITIVE, init-value=0, base-type=BT_EPB_Status, compu {0=Cx0_offen (CM_EPB_Status_Cx0_offen), 1=Cx1_Bremse_geschl_Spannkraft_voll_reduziert (CM_EPB_Status_Cx1_Bremse_geschl_Spannkraft_voll_reduziert) (Bremse_geschl_(Spannkraft_voll/reduziert)), 2=Cx2_Aktuator_im_Lauf (CM_EPB_Status_Cx2_Aktuator_im_Lauf), 3=Cx3_Fehler_oder_unbekannt (CM_EPB_Status_Cx3_Fehler_oder_unbekannt)}, range raw 0..3, transfer-property=PENDING  # Gibt den Zustand der EPB-Aktuatoren an. Nur VW526/PAG E2: Wert 0x3 bedeutet "unbekannt"
          signal ESP_Status_Bremsentemp_02_XIX_ESC_50_XIX_E3V_K2CANFD: start 322, 2 bit, little-endian, data-type-policy=OVERRIDE, i-signal-type=PRIMITIVE, init-value=0, base-type=BT_ESP_Status_Bremsentemp_02, compu {0=Cx0_nicht_erhoeht (CM_ESP_Status_Bremsentemp_02_Cx0_nicht_erhoeht), 1=Cx1_Schwelle_1 (CM_ESP_Status_Bremsentemp_02_Cx1_Schwelle_1), 2=Cx2_Schwelle_2 (CM_ESP_Status_Bremsentemp_02_Cx2_Schwelle_2)}, range raw 0..2, transfer-property=PENDING, to SAM(timeout 0.5 s)  # Bremsscheibentemperaturmodell. Rückmeldung für Sender einer Verzögerungsanforderung
          signal ESC_Bremsfluessigkeits_Sensor_XIX_ESC_50_XIX_E3V_K2CANFD: start 330, 1 bit, little-endian, data-type-policy=OVERRIDE, i-signal-type=PRIMITIVE, init-value=0, base-type=BT_ESC_Bremsfluessigkeits_Sensor, compu {0=Cx0_OK (CM_ESC_Bremsfluessigkeits_Sensor_Cx0_OK), 1=Cx1_Bremsfluessigkeit_unter_min (CM_ESC_Bremsfluessigkeits_Sensor_Cx1_Bremsfluessigkeit_unter_min)}, range raw 0..1, transfer-property=PENDING, to SAM(timeout 0.5 s)  # Kontaktsignal von der Bremse des Sensorschalters für die Bremsflüssigkeitsreserve.
      frame ESP_21_XIX_E3V_K2CANFD: id 0xFD, to SAM, frame-length=8, can-addressing-mode=STANDARD, can-frame-rx-behavior=CAN-FD, can-frame-tx-behavior=CAN-FD
        pdu ESP_21_XIX_E3V_K2CANFD_E2E: length=8, transmission-mode-true-timing=event-controlled-timing={number-of-repetitions=0, repetition-period=0.0}, unused-bit-pattern=0  # Fuer die Botschaft ist das Cyclic-Timing 0.02 zu verwenden.
          signal ESP_21_CRC_XIX_ESP_21_XIX_E3V_K2CANFD: start 0, 8 bit, little-endian, data-type-policy=OVERRIDE, i-signal-type=PRIMITIVE, base-type=BT_ESP_21_CRC, compu {phys=raw for raw 0..255}, range phys 0..255, raw 0..255, to SAM(timeout 0.5 s)  # Für MLB: "Berechnung siehe Lastenheft "Kommunikationsabsicherung für FlexRay und CAN"" Ab MQB und MLBevo: "Berechnung siehe Lastenheft "End-to-End Kommunikationsabsicherung"" Endwerte siehe Begleitdokument "S-PDU Kennungsfolgen"
          signal ESP_21_BZ_XIX_ESP_21_XIX_E3V_K2CANFD: start 8, 4 bit, little-endian, data-type-policy=OVERRIDE, i-signal-type=PRIMITIVE, base-type=BT_ESP_21_BZ, compu {phys=raw for raw 0..15}, range phys 0..15, raw 0..15, to SAM(timeout 0.5 s)
          signal BR_Eingriffsmoment_XIX_ESP_21_XIX_E3V_K2CANFD: start 12, 10 bit, little-endian, data-type-policy=OVERRIDE, i-signal-type=PRIMITIVE, init-value=1022, base-type=BT_BR_Eingriffsmoment, invalid-value=Invalid_BR_Eingriffsmoment_XIX_ESP_21_XIX_E3V_K2CANFD:1023, compu {phys=raw-509 for raw 0..1018, 1022=Cx3fe_Init (CM_BR_Eingriffsmoment_Cx3fe_Init), 1023=Cx3ff_Fehler (CM_BR_Eingriffsmoment_Cx3ff_Fehler)}, range phys -509..509, raw 0..1023  # Einheitenloser Wert! Faktor in MO_Faktor_Momente_02 in Motor_Code_01 beachten! Schnelle reduzierende (ASR) oder erhöhende (MSR) Momentanforderung an den Motor.
          signal ESP_PLA_Bremseingriff_XIX_ESP_21_XIX_E3V_K2CANFD: start 22, 1 bit, little-endian, data-type-policy=OVERRIDE, i-signal-type=PRIMITIVE, init-value=0, base-type=BT_ESP_PLA_Bremseingriff, compu {0=Cx0_inaktiv (CM_ESP_PLA_Bremseingriff_Cx0_inaktiv), 1=Cx1_aktiv (CM_ESP_PLA_Bremseingriff_Cx1_aktiv)}, range raw 0..1  # Signalisierung des aktiven Bremseingriffes des ESP aufgrund einer Bremsanforderung vom PLA.
          signal ESP_Diagnose_XIX_ESP_21_XIX_E3V_K2CANFD: start 23, 1 bit, little-endian, data-type-policy=OVERRIDE, i-signal-type=PRIMITIVE, init-value=0, base-type=BT_ESP_Diagnose, compu {0=Cx0_ESP_nicht_in_Diagnose (CM_ESP_Diagnose_Cx0_ESP_nicht_in_Diagnose), 1=Cx1_ESP_in_Diagnose (CM_ESP_Diagnose_Cx1_ESP_in_Diagnose)}, range raw 0..1  # MLB: Nach Diagnoseende wird ein SW-Reset ausgelöst welcher einen Kommunikatiosausfall für max. 150ms verursacht. Dies ist bei SG mit verschärfter Timeoutüberwachung (nicht nach Konzern-LH) zu beachten. MQB: Weiterführende Informationen im Lastenheft spezifiziert und in der entsprechenden Fachabteilung zu erfragen.
          signal ESC_Reku_Freigabe_XIX_ESP_21_XIX_E3V_K2CANFD: start 24, 1 bit, little-endian, data-type-policy=OVERRIDE, i-signal-type=PRIMITIVE, init-value=0, base-type=BT_ESC_Reku_Freigabe, compu {0=Cx0_keine_Freigabe_der_Rekuperation (CM_ESC_Reku_Freigabe_Cx0_keine_Freigabe_der_Rekuperation), 1=Cx1_Freigabe_der_Rekuperation (CM_ESC_Reku_Freigabe_Cx1_Freigabe_der_Rekuperation)}, range raw 0..1  # Mit diesem Bit wird die Rekuperation im Motorsteuergerät erlaubt. Bei Ausfall ESC wird Rekuperation nicht freigegeben. MQB/MQB2020: Wird nur von einem blendfähigen ESC unterstützt, wie es in mHEV und pHEV Fahrzeugen eingesetzt wird.
          signal ESC_v_Signal_Qualifier_High_Low_XIX_ESP_21_XIX_E3V_K2CANFD: start 25, 3 bit, little-endian, data-type-policy=OVERRIDE, i-signal-type=PRIMITIVE, init-value=6, base-type=BT_ESC_v_Signal_Qualifier_High_Low, invalid-value=Invalid_ESC_v_Signal_Qualifier_High_Low_XIX_ESP_21_XIX_E3V_K2CANFD:7, compu {0=Cx0_Gueteschwelle_kleiner_1kmh (CM_ESC_v_Signal_Qualifier_High_Low_Cx0_Gueteschwelle_kleiner_1kmh), 1=Cx1_Gueteschwelle_kleiner_3kmh (CM_ESC_v_Signal_Qualifier_High_Low_Cx1_Gueteschwelle_kleiner_3kmh), 2=Cx2_Gueteschwelle_kleiner_5kmh (CM_ESC_v_Signal_Qualifier_High_Low_Cx2_Gueteschwelle_kleiner_5kmh), 3=Cx3_Gueteschwelle_kleiner_10kmh (CM_ESC_v_Signal_Qualifier_High_Low_Cx3_Gueteschwelle_kleiner_10kmh), 4=Cx4_Gueteschwelle_kleiner_20kmh (CM_ESC_v_Signal_Qualifier_High_Low_Cx4_Gueteschwelle_kleiner_20kmh), 5=Cx5_Gueteschwelle_groessergleich_20kmh (CM_ESC_v_Signal_Qualifier_High_Low_Cx5_Gueteschwelle_groessergleich_20kmh), 6=Cx6_Init (CM_ESC_v_Signal_Qualifier_High_Low_Cx6_Init), 7=Cx7_Fehler (CM_ESC_v_Signal_Qualifier_High_Low_Cx7_Fehler)}, range raw 0..7, to SAM(timeout 0.5 s)  # Das Qualifizerungssignal ESC_v_Signal_Qualifier_High_Low gibt eine Information über die Güte der vom Bremsregelsystem ausgegebenen Geschwindigkeitsinformation "mittlere Geschwindigkeit", wobei Vertrauensbereiche für das ausgegebene Geschwindigkeitssignal angezeigt werden. Angezeigt werden über das Qualifizerungssignal sowohl Einschränkungen in der Güte des Signals durch funktionale Einschränkungen (Radschlupf an Einzelrädern, z.B. während aktiver ESC-Regelungen) als auch fehlerbedingte Abweichungen der Geschwindigkeitsinforma-tion (z.B. durch fehlerhafte Raddrehzahlsensorsignale).
          signal ESP_Vorsteuerung_XIX_ESP_21_XIX_E3V_K2CANFD: start 28, 1 bit, little-endian, data-type-policy=OVERRIDE, i-signal-type=PRIMITIVE, init-value=0, base-type=BT_ESP_Vorsteuerung, compu {0=Cx0_keine_Vorsteuerung_aktiv (CM_ESP_Vorsteuerung_Cx0_keine_Vorsteuerung_aktiv), 1=Cx1_Vorsteuerung_aktiv (CM_ESP_Vorsteuerung_Cx1_Vorsteuerung_aktiv)}, range raw 0..1  # zur Unterscheidung zwischen ESP-Vorsteuermaßnahmen und ESP-Regeleingriffen
          signal ESP_AWV3_Brems_aktiv_XIX_ESP_21_XIX_E3V_K2CANFD: start 29, 1 bit, little-endian, data-type-policy=OVERRIDE, i-signal-type=PRIMITIVE, init-value=0, base-type=BT_ESP_AWV3_Brems_aktiv, compu {0=Cx0_inaktiv (CM_ESP_AWV3_Brems_aktiv_Cx0_inaktiv), 1=Cx1_aktiv (CM_ESP_AWV3_Brems_aktiv_Cx1_aktiv)}, range raw 0..1  # Teil-, Ziel- oder Notbremsung wird im ESP für AWV3 umgesetzt (das MSG nutzt diese Info für den Abwurf der GRA-Regelung).
          signal OBD_Schlechtweg_XIX_ESP_21_XIX_E3V_K2CANFD: start 30, 1 bit, little-endian, data-type-policy=OVERRIDE, i-signal-type=PRIMITIVE, init-value=0, base-type=BT_OBD_Schlechtweg, compu {0=Cx0_kein_Schlechtweg_erkannt (CM_OBD_Schlechtweg_Cx0_kein_Schlechtweg_erkannt), 1=Cx1_Schlechtweg_erkannt (CM_OBD_Schlechtweg_Cx1_Schlechtweg_erkannt)}, range raw 0..1  # Für Ausblendung der Zündaussetzererkennung im Motorsteuergerät (Otto). Bit wird gesetzt, wenn Rad-Drehbeschleunigung im ESP > Grenzwert ist. Vorteil gegenüber Radgeschwindigkeiten, dass ESP alle 2 ms dynamisch die Rad-Drehbeschleunigung errechnet und dem Motor eine bessere Güte liefert. Bit darf nur vom Motor ausgewertet werden. Es gilt Signalspezifikation OBD_Schlechtweg V2.0 Im MQB wird dieses Signal nicht unterstützt!
          signal OBD_QBit_Schlechtweg_XIX_ESP_21_XIX_E3V_K2CANFD: start 31, 1 bit, little-endian, data-type-policy=OVERRIDE, i-signal-type=PRIMITIVE, init-value=1, base-type=BT_OBD_QBit_Schlechtweg, compu {0=Cx0_gueltiger_Wert (CM_OBD_QBit_Schlechtweg_Cx0_gueltiger_Wert), 1=Cx1_Ersatz_Init_oder_Fehlerwert (CM_OBD_QBit_Schlechtweg_Cx1_Ersatz_Init_oder_Fehlerwert)}, range raw 0..1
          signal ESP_v_Signal_XIX_ESP_21_XIX_E3V_K2CANFD: start 32, 16 bit, little-endian, data-type-policy=OVERRIDE, i-signal-type=PRIMITIVE, init-value=65534, base-type=BT_ESP_v_Signal, invalid-value=Invalid_ESP_v_Signal_XIX_ESP_21_XIX_E3V_K2CANFD:65535, compu {phys=raw*0.01 for raw 0..65532, 65533=Cxfffd_Unterspannung (CM_ESP_v_Signal_Cxfffd_Unterspannung), 65534=Cxfffe_Init (CM_ESP_v_Signal_Cxfffe_Init), 65535=Cxffff_Fehler (CM_ESP_v_Signal_Cxffff_Fehler); unit Unit_KiloMeterPerHour}, range phys 0..655.32 Unit_KiloMeterPerHour, raw 0..65535, unit=Unit_KiloMeterPerHour, to SAM(timeout 0.5 s)  # Geschwindigkeitssignal vom ABS/ASR oder ESP. Mittelwert der angetriebenen Räder. Bei MSR oder ABS Eingriffen wird die ABS-Referenzgeschwindigkeit für >= 200ms eingespiegelt (Zeit wird mit Aktiv-Flanke der Funktionsbits getriggert) MQB: Bei Frontantrieb und gesteuertem Allrad (Haldex) Mittelwert der Vorderräder.
          signal ASR_Tastung_passiv_XIX_ESP_21_XIX_E3V_K2CANFD: start 48, 1 bit, little-endian, data-type-policy=OVERRIDE, i-signal-type=PRIMITIVE, init-value=0, base-type=BT_ASR_Tastung_passiv, compu {0=Cx0_ASR_aktiviert (CM_ASR_Tastung_passiv_Cx0_ASR_aktiviert), 1=Cx1_ASR_passiv_getastet_oder_Schwellen_geaendert (CM_ASR_Tastung_passiv_Cx1_ASR_passiv_getastet_oder_Schwellen_geaendert)}, range raw 0..1  # ASR deaktiviert oder Schwellen geändert (projektabhängig) Weiterführende Informationen im Lastenheft spezifiziert und in der entsprechenden Fachabteilung zu erfragen.
          signal ESP_Tastung_passiv_XIX_ESP_21_XIX_E3V_K2CANFD: start 49, 1 bit, little-endian, data-type-policy=OVERRIDE, i-signal-type=PRIMITIVE, init-value=0, base-type=BT_ESP_Tastung_passiv, compu {0=Cx0_ESP_aktiviert (CM_ESP_Tastung_passiv_Cx0_ESP_aktiviert), 1=Cx1_ESP_passiv_getastet_oder_Schwellen_geaendert (CM_ESP_Tastung_passiv_Cx1_ESP_passiv_getastet_oder_Schwellen_geaendert)}, range raw 0..1  # ESP deaktiviert oder Schwellen geändert (projektabhängig) Weiterführende Informationen im Lastenheft spezifiziert und in der entsprechenden Fachabteilung zu erfragen.
          signal ESP_Systemstatus_XIX_ESP_21_XIX_E3V_K2CANFD: start 50, 1 bit, little-endian, data-type-policy=OVERRIDE, i-signal-type=PRIMITIVE, init-value=0, base-type=BT_ESP_Systemstatus, compu {0=Cx0_iO (CM_ESP_Systemstatus_Cx0_iO), 1=Cx1_Fehler (CM_ESP_Systemstatus_Cx1_Fehler)}, range raw 0..1  # Fehler steht für Stillegung ESP mit Fehlereintrag. MLB: Flag wird bei Unterspannung im Stand bis einmalig 6km/h (AU48x) oder 10 km/h (AU641, AU57x) überschritten nicht gesetzt (Ausblendung Startvorgang) Im AU64x, AU57x gilt ESP D4 Funktionsanforderungen (DOORS-Modul)
          signal ASR_Schalteingriff_XIX_ESP_21_XIX_E3V_K2CANFD: start 51, 2 bit, little-endian, data-type-policy=OVERRIDE, i-signal-type=PRIMITIVE, init-value=0, base-type=BT_ASR_Schalteingriff, compu {0=Cx0_keine_Anforderung (CM_ASR_Schalteingriff_Cx0_keine_Anforderung), 1=Cx1_ASR_Schaltkennfeld (CM_ASR_Schalteingriff_Cx1_ASR_Schaltkennfeld), 2=Cx2_Rueckschaltung (CM_ASR_Schalteingriff_Cx2_Rueckschaltung), 3=Cx3_Schaltverbot (CM_ASR_Schalteingriff_Cx3_Schaltverbot)}, range raw 0..3  # Wunsch an das Getriebe während einer ASR Regelung MLB: Es wird nur 0x0 und 0x1 genutzt
          signal ESP_Haltebestaetigung_XIX_ESP_21_XIX_E3V_K2CANFD: start 53, 1 bit, little-endian, data-type-policy=OVERRIDE, i-signal-type=PRIMITIVE, init-value=0, base-type=BT_ESP_Haltebestaetigung, compu {0=Cx0_kein_sicheres_Halten (CM_ESP_Haltebestaetigung_Cx0_kein_sicheres_Halten), 1=Cx1_sicheres_Halten (CM_ESP_Haltebestaetigung_Cx1_sicheres_Halten)}, range raw 0..1  # Rückmeldung vom ESP-SG, dass das Fahrzeug aufgrund einer externen Bremsanforderung (z. B. ACC, PLA, ANB, o. ä.) abgebremst wurde und im Stillstand gehalten wird.
          signal ESP_MKB_Abbruch_Geschw_XIX_ESP_21_XIX_E3V_K2CANFD: start 54, 1 bit, little-endian, data-type-policy=OVERRIDE, i-signal-type=PRIMITIVE, init-value=0, base-type=BT_ESP_MKB_Abbruch_Geschw, compu {0=Cx0_MKB_nicht_beendet_wg_v_Schwelle (CM_ESP_MKB_Abbruch_Geschw_Cx0_MKB_nicht_beendet_wg_v_Schwelle), 1=Cx1_MKB_beendet_wg_v_Schwelle (CM_ESP_MKB_Abbruch_Geschw_Cx1_MKB_beendet_wg_v_Schwelle)}, range raw 0..1  # Im Falle einer Multikollisionsbremsung teilt das ESP den Abbruch der MKB aufgrund der unteren Geschwindigkeitsschwelle mit.
          signal ESP_QBit_v_Signal_XIX_ESP_21_XIX_E3V_K2CANFD: start 55, 1 bit, little-endian, data-type-policy=OVERRIDE, i-signal-type=PRIMITIVE, init-value=1, base-type=BT_ESP_QBit_v_Signal, compu {0=Cx0_gueltiger_Wert (CM_ESP_QBit_v_Signal_Cx0_gueltiger_Wert), 1=Cx1_Ersatz_Init_oder_Fehlerwert (CM_ESP_QBit_v_Signal_Cx1_Ersatz_Init_oder_Fehlerwert)}, range raw 0..1, to SAM(timeout 0.5 s)  # Geschwindigkeit wird vom ABS/ASR oder ESP aus Ersatzwerten errechnet, wenn Bit gesetzt ist. Güte des Signals ist verändert.
          signal ABS_Bremsung_XIX_ESP_21_XIX_E3V_K2CANFD: start 56, 1 bit, little-endian, data-type-policy=OVERRIDE, i-signal-type=PRIMITIVE, init-value=0, base-type=BT_ABS_Bremsung, compu {0=Cx0_keine_ABS_Regelung (CM_ABS_Bremsung_Cx0_keine_ABS_Regelung), 1=Cx1_ABS_Regelung_aktiv (CM_ABS_Bremsung_Cx1_ABS_Regelung_aktiv)}, range raw 0..1  # Antiblockiersystem, Bit zeigt auch Druckabbau an (z.B. ESP hat zuviel Druck aufgebaut oder ungebremste Regelung auf Bahnübergang) Weiterführende Informationen im Lastenheft spezifiziert und in der entsprechenden Fachabteilung zu erfragen.
          signal ASR_Anf_XIX_ESP_21_XIX_E3V_K2CANFD: start 57, 1 bit, little-endian, data-type-policy=OVERRIDE, i-signal-type=PRIMITIVE, init-value=0, base-type=BT_ASR_Anf, compu {0=Cx0_keine_Anforderung (CM_ASR_Anf_Cx0_keine_Anforderung), 1=Cx1_ASR_Anforderung (CM_ASR_Anf_Cx1_ASR_Anforderung)}, range raw 0..1  # MLB: Die Momentenanforderung "ASR_MSR_Moment_schnell" und "ASR_Moment_langsam" sind auszuführen MQB: Die Momentenanforderung "BR_Eingriffsmoment" ist auszuführen
          signal MSR_Anf_XIX_ESP_21_XIX_E3V_K2CANFD: start 58, 1 bit, little-endian, data-type-policy=OVERRIDE, i-signal-type=PRIMITIVE, init-value=0, base-type=BT_MSR_Anf, compu {0=Cx0_keine_Anfoderung (CM_MSR_Anf_Cx0_keine_Anfoderung) (keine Anfoderung), 1=Cx1_MSR_Anforderung (CM_MSR_Anf_Cx1_MSR_Anforderung) (MSR-Anforderung)}, range raw 0..1  # MLB: Die Momentenanforderung "ASR_MSR_Moment_schnell" ist auszuführen. MQB: Die Momentenanforderung "BR_Eingriffsmoment" ist auszuführen
          signal EBV_Eingriff_XIX_ESP_21_XIX_E3V_K2CANFD: start 59, 1 bit, little-endian, data-type-policy=OVERRIDE, i-signal-type=PRIMITIVE, init-value=0, base-type=BT_EBV_Eingriff, compu {0=Cx0_kein_EBV_Eingriff (CM_EBV_Eingriff_Cx0_kein_EBV_Eingriff), 1=Cx1_EBV_Eingriff (CM_EBV_Eingriff_Cx1_EBV_Eingriff)}, range raw 0..1  # Elektronische Bremskraftverteilung, aktueller Eingriff (Druckhalten, Druckabbau) Im MLB: kein ABS / ESP-Eingriff ???
          signal EDS_Eingriff_XIX_ESP_21_XIX_E3V_K2CANFD: start 60, 1 bit, little-endian, data-type-policy=OVERRIDE, i-signal-type=PRIMITIVE, init-value=0, base-type=BT_EDS_Eingriff, compu {0=Cx0_kein_EDS_Eingriff (CM_EDS_Eingriff_Cx0_kein_EDS_Eingriff), 1=Cx1_EDS_Eingriff (CM_EDS_Eingriff_Cx1_EDS_Eingriff)}, range raw 0..1  # Elektronische Differentialsperre
          signal ESP_Eingriff_XIX_ESP_21_XIX_E3V_K2CANFD: start 61, 1 bit, little-endian, data-type-policy=OVERRIDE, i-signal-type=PRIMITIVE, init-value=0, base-type=BT_ESP_Eingriff, compu {0=Cx0_kein_ESP_Eingriff (CM_ESP_Eingriff_Cx0_kein_ESP_Eingriff), 1=Cx1_ESP_Eingriff_aktiv (CM_ESP_Eingriff_Cx1_ESP_Eingriff_aktiv)}, range raw 0..1  # Eingriff des Fahrdynamikreglers
          signal ESP_ASP_XIX_ESP_21_XIX_E3V_K2CANFD: start 62, 1 bit, little-endian, data-type-policy=OVERRIDE, i-signal-type=PRIMITIVE, init-value=0, base-type=BT_ESP_ASP, compu {0=Cx0_inaktiv (CM_ESP_ASP_Cx0_inaktiv), 1=Cx1_aktiv (CM_ESP_ASP_Cx1_aktiv)}, range raw 0..1  # MLB: Anhaenger-Stabilisierungs-Programm MQB: Gespannstabilisierung
          signal ESP_Anhaltevorgang_ACC_aktiv_XIX_ESP_21_XIX_E3V_K2CANFD: start 63, 1 bit, little-endian, data-type-policy=OVERRIDE, i-signal-type=PRIMITIVE, init-value=0, base-type=BT_ESP_Anhaltevorgang_ACC_aktiv, compu {0=Cx0_inaktiv (CM_ESP_Anhaltevorgang_ACC_aktiv_Cx0_inaktiv), 1=Cx1_aktiv (CM_ESP_Anhaltevorgang_ACC_aktiv_Cx1_aktiv)}, range raw 0..1  # Zeigt an, ob ACC-Anhaltevorgang aktiv
          mapping SG_ESP_21_XIX_E3V_K2CANFD: i-signal-group=SG_ESP_21_XIX_E3V_K2CANFD, transfer-property=TRIGGERED-WITHOUT-REPETITION
      frame ESP_24_XIX_E3V_K2CANFD: id 0x31B, to SAM, frame-length=8, can-addressing-mode=STANDARD, can-frame-rx-behavior=CAN-FD, can-frame-tx-behavior=CAN-FD
        pdu ESP_24_XIX_E3V_K2CANFD: length=8, transmission-mode-true-timing=cyclic-timing={time-offset=0.0, time-period=0.05}, unused-bit-pattern=0  # neu für MQB wg. Absicherung Entstanden aus ESP_04
          signal ESP_24_CRC_XIX_ESP_24_XIX_E3V_K2CANFD: start 0, 8 bit, little-endian, data-type-policy=OVERRIDE, i-signal-type=PRIMITIVE, base-type=BT_ESP_24_CRC, compu {phys=raw for raw 0..255}, range phys 0..255, raw 0..255, transfer-property=PENDING  # Für MLB: "Berechnung siehe Lastenheft "Kommunikationsabsicherung für FlexRay und CAN"" Ab MQB und MLBevo: "Berechnung siehe Lastenheft "End-to-End Kommunikationsabsicherung"" Endwerte siehe Begleitdokument "S-PDU Kennungsfolgen"
          signal ESP_24_BZ_XIX_ESP_24_XIX_E3V_K2CANFD: start 8, 4 bit, little-endian, data-type-policy=OVERRIDE, i-signal-type=PRIMITIVE, base-type=BT_ESP_24_BZ, compu {phys=raw for raw 0..15}, range phys 0..15, raw 0..15, transfer-property=PENDING
          signal ESP_Lampe_XIX_ESP_24_XIX_E3V_K2CANFD: start 12, 1 bit, little-endian, data-type-policy=OVERRIDE, i-signal-type=PRIMITIVE, init-value=1, base-type=BT_ESP_Lampe, compu {0=Cx0_Aus (CM_ESP_Lampe_Cx0_Aus), 1=Cx1_Ein (CM_ESP_Lampe_Cx1_Ein)}, range raw 0..1, transfer-property=PENDING  # Zustand der Fahrdynamikregelungslampe (MLB: ASR und/oder ESP, MQB: nur ESP) Weiterführende Informationen im Lastenheft spezifiziert und in der entsprechenden Fachabteilung zu erfragen.
          signal ABS_Lampe_XIX_ESP_24_XIX_E3V_K2CANFD: start 13, 1 bit, little-endian, data-type-policy=OVERRIDE, i-signal-type=PRIMITIVE, init-value=1, base-type=BT_ABS_Lampe, compu {0=Cx0_Aus (CM_ABS_Lampe_Cx0_Aus), 1=Cx1_Ein (CM_ABS_Lampe_Cx1_Ein)}, range raw 0..1, transfer-property=PENDING  # Sicherheitswarnlampe Weiterführende Informationen im Lastenheft spezifiziert und in der entsprechenden Fachabteilung zu erfragen.
          signal BK_Lampe_02_XIX_ESP_24_XIX_E3V_K2CANFD: start 14, 2 bit, little-endian, data-type-policy=OVERRIDE, i-signal-type=PRIMITIVE, init-value=1, base-type=BT_BK_Lampe_02, compu {0=Cx0_aus (CM_BK_Lampe_02_Cx0_aus), 1=Cx1_Typ1_ein_statisch (CM_BK_Lampe_02_Cx1_Typ1_ein_statisch), 2=Cx2_Typ2_ein_statisch (CM_BK_Lampe_02_Cx2_Typ2_ein_statisch), 3=Cx3_Warnung (CM_BK_Lampe_02_Cx3_Warnung)}, range raw 0..3, transfer-property=PENDING  # Typ1_ein_statisch signalisiert EBV-Ausfall MQB: wird auch bei HBV-Ausfall verwendet. Typ1_ein_statisch: wird bei AUDI für Aktivierung der roten BKL ohne Text und Akustik verwendet (z.B. Lampenaufprüfung). Typ2_ein_statisch: signalisiert elektrischen Fehler ohne Ausfall HBV oder EBV Weiterführende Informationen im Lastenheft spezifiziert und in der entsprechenden Fachabteilung zu erfragen.
          signal TC_Lampe_XIX_ESP_24_XIX_E3V_K2CANFD: start 16, 1 bit, little-endian, data-type-policy=OVERRIDE, i-signal-type=PRIMITIVE, init-value=0, base-type=BT_TC_Lampe, compu {0=Cx0_Aus (CM_TC_Lampe_Cx0_Aus), 1=Cx1_Ein (CM_TC_Lampe_Cx1_Ein)}, range raw 0..1, transfer-property=PENDING  # M-ABS Lampe (separate Lampe für M-ABS-Systeme Markt Brasilien) Weiterführende Informationen im Lastenheft spezifiziert und in der entsprechenden Fachabteilung zu erfragen.
          signal ESP_m_Raddrehz_XIX_ESP_24_XIX_E3V_K2CANFD: start 17, 15 bit, little-endian, data-type-policy=OVERRIDE, i-signal-type=PRIMITIVE, init-value=32766, base-type=BT_ESP_m_Raddrehz, invalid-value=Invalid_ESP_m_Raddrehz_XIX_ESP_24_XIX_E3V_K2CANFD:32767, compu {phys=raw*0.002 for raw 0..32639, 32765=Cx7ffd_Unterspannung (CM_ESP_m_Raddrehz_Cx7ffd_Unterspannung), 32766=Cx7ffe_Init (CM_ESP_m_Raddrehz_Cx7ffe_Init), 32767=Cx7fff_Fehler (CM_ESP_m_Raddrehz_Cx7fff_Fehler); unit Unit_Hertz}, range phys 0..65.278 Unit_Hertz, raw 0..32767, unit=Unit_Hertz, transfer-property=PENDING, to SAM(timeout 0.5 s)  # Radumdrehungen pro Sekunde sind Eingangsgröße für die Geschwindigkeitsberechnung im Kombi. Aus dieser Raddrehzahl und dem Radumfang wird die Fahrzeuggeschwindigkeit errechnet. MLB: Exklusiver Empfänger ist das Kombiinstrument! MQB: Bei Frontantrieb und gesteuertem Allrad (Haldex) Mittelwert der Vorderräder.
          signal ESP_Textanzeigen_03_XIX_ESP_24_XIX_E3V_K2CANFD: start 32, 5 bit, little-endian, data-type-policy=OVERRIDE, i-signal-type=PRIMITIVE, init-value=0, base-type=BT_ESP_Textanzeigen_03, compu {0=Cx0_kein_Text (CM_ESP_Textanzeigen_03_Cx0_kein_Text), 1=Cx1_ESP_Stoerung (CM_ESP_Textanzeigen_03_Cx1_ESP_Stoerung), 2=Cx2_ABS_Stoerung (CM_ESP_Textanzeigen_03_Cx2_ABS_Stoerung), 3=Cx3_ESP_ABS_Stoerung (CM_ESP_Textanzeigen_03_Cx3_ESP_ABS_Stoerung), 4=Cx4_Werkstatt_Bremse (CM_ESP_Textanzeigen_03_Cx4_Werkstatt_Bremse), 5=Cx5_ASR_Stoerung (CM_ESP_Textanzeigen_03_Cx5_ASR_Stoerung), 6=Cx6_ESP_switched_off (CM_ESP_Textanzeigen_03_Cx6_ESP_switched_off), 7=Cx7_ASR_off (CM_ESP_Textanzeigen_03_Cx7_ASR_off), 8=Cx8_ESP_ASR_on (CM_ESP_Textanzeigen_03_Cx8_ESP_ASR_on), 9=Cx9_ESC_Off_V1 (CM_ESP_Textanzeigen_03_Cx9_ESC_Off_V1), 10=Cxa_keine_Bremskraftverstaerkung (CM_ESP_Textanzeigen_03_Cxa_keine_Bremskraftverstaerkung), 11=Cxb_ASR_aktiviert (CM_ESP_Textanzeigen_03_Cxb_ASR_aktiviert), 12=Cxc_ABS_ASR_Stoerung (CM_ESP_Textanzeigen_03_Cxc_ABS_ASR_Stoerung), 13=Cxd_ESC_Off_V2 (CM_ESP_Textanzeigen_03_Cxd_ESC_Off_V2), 15=Cxf_ESP_offroad (CM_ESP_Textanzeigen_03_Cxf_ESP_offroad), 16=Cx10_ASR_Sport (CM_ESP_Textanzeigen_03_Cx10_ASR_Sport), 17=Cx11_ESP_sport (CM_ESP_Textanzeigen_03_Cx11_ESP_sport), 18=Cx12_ESP_Zwangsaktivierung (CM_ESP_Textanzeigen_03_Cx12_ESP_Zwangsaktivierung), 19=Cx13_ESP_Taster_Info (CM_ESP_Textanzeigen_03_Cx13_ESP_Taster_Info), 20=Cx14_TC_aktiv (CM_ESP_Textanzeigen_03_Cx14_TC_aktiv), 21=Cx15_reserviert_fuer_Verlwarn (CM_ESP_Textanzeigen_03_Cx15_reserviert_fuer_Verlwarn), 22=Cx16_TC_switched_off (CM_ESP_Textanzeigen_03_Cx16_TC_switched_off), 23=Cx17_Verlwarn_akt_Rollsicher_inakt (CM_ESP_Textanzeigen_03_Cx17_Verlwarn_akt_Rollsicher_inakt), 24=Cx18_ESP_SuperSport (CM_ESP_Textanzeigen_03_Cx18_ESP_SuperSport), 25=Cx19_ESP_Offroad_nicht_verfuegbar (CM_ESP_Textanzeigen_03_Cx19_ESP_Offroad_nicht_verfuegbar), 26=Cx1a_ESC_off_Quittierung (CM_ESP_Textanzeigen_03_Cx1a_ESC_off_Quittierung)}, range raw 0..26, transfer-property=PENDING  # Textanzeigen der Fahrdynamikregelung im Kombiinstrument Weiterführende Informationen im Lastenheft spezifiziert und in der entsprechenden Fachabteilung zu erfragen. Der Signalwert 24 wird nur im BY736 verwendet.
          signal ESP_Meldungen_XIX_ESP_24_XIX_E3V_K2CANFD: start 37, 3 bit, little-endian, data-type-policy=OVERRIDE, i-signal-type=PRIMITIVE, init-value=0, base-type=BT_ESP_Meldungen, compu {0=Cx0_keine_Anzeige (CM_ESP_Meldungen_Cx0_keine_Anzeige), 1=Cx1_Autohold_Hinweis_1 (CM_ESP_Meldungen_Cx1_Autohold_Hinweis_1), 2=Cx2_Stoerung_Autohold (CM_ESP_Meldungen_Cx2_Stoerung_Autohold), 3=Cx3_Stoerung_Hillholder (CM_ESP_Meldungen_Cx3_Stoerung_Hillholder), 4=Cx4_Uebernehmen (CM_ESP_Meldungen_Cx4_Uebernehmen), 5=Cx5_Autohold_aus (CM_ESP_Meldungen_Cx5_Autohold_aus), 6=Cx6_Autohold_Hinweis_2 (CM_ESP_Meldungen_Cx6_Autohold_Hinweis_2)}, range raw 0..6, transfer-property=PENDING  # ESP sendet im Hinweis- /Störungsfall an das Kombi Informationen zum Anzeigen Weiterführende Informationen im Lastenheft spezifiziert und in der entsprechenden Fachabteilung zu erfragen. Ergänzender Hinweis: 1 = Autohold_Hinweis_1 (Anfahrassistent: nur verfügbar bei geschlossener Tür, angelegtem Gurt und laufendem Motor) 6 = Autohold_Hinweis_2 (Parkbremse nicht aktiviert)
          signal ESP_Wegimp_VA_XIX_ESP_24_XIX_E3V_K2CANFD: start 40, 11 bit, little-endian, data-type-policy=OVERRIDE, i-signal-type=PRIMITIVE, init-value=0, base-type=BT_ESP_Wegimp_VA, compu {phys=raw for raw 0..2047}, range phys 0..2047, raw 0..2047, transfer-property=PENDING  # Weiterführende Informationen im Lastenheft spezifiziert und in der entsprechenden Fachabteilung zu erfragen. MLB: Die Wegimpulse Vorderachse sind die gemittelten Werte (reine mathematische Operation: Addition und Division durch zwei, keine Filterung) der Wegimpulse der Ränder VL und VR. MQB: Die Wegimpulse der primär angetriebenen Achse sind die gemittelten Werte (reine mathematische Operation: Addition und Division durch zwei, keine Filterung) der Wegimpulse der Räder VL und VR oder HL und HR. Bei Ausfall eines Drehzahlfühlers wird der funktionsfähige Sensor zur Ausgabe verwendet.
          signal ESP_Fehlerstatus_Wegimp_XIX_ESP_24_XIX_E3V_K2CANFD: start 51, 1 bit, little-endian, data-type-policy=OVERRIDE, i-signal-type=PRIMITIVE, init-value=0, base-type=BT_ESP_Fehlerstatus_Wegimp, compu {0=Cx0_Wegimpulse_iO (CM_ESP_Fehlerstatus_Wegimp_Cx0_Wegimpulse_iO), 1=Cx1_Fehler (CM_ESP_Fehlerstatus_Wegimp_Cx1_Fehler)}, range raw 0..1, transfer-property=PENDING  # Weiterführende Informationen im Lastenheft spezifiziert und in der entsprechenden Fachabteilung zu erfragen. MLB: Fehler wird gesetzt, wenn beide ESP-Drehzahlfühler an der Vorderachse defekt sind. MQB: Fehler wird gesetzt, wenn beide Raddrehzahlfühler der primär angetriebenen Achse defekt sind.
          signal ESP_Wegimp_Ueberlauf_XIX_ESP_24_XIX_E3V_K2CANFD: start 52, 1 bit, little-endian, data-type-policy=OVERRIDE, i-signal-type=PRIMITIVE, init-value=0, base-type=BT_ESP_Wegimp_Ueberlauf, compu {0=Cx0_Reset_und_kein_Ueberlauf (CM_ESP_Wegimp_Ueberlauf_Cx0_Reset_und_kein_Ueberlauf), 1=Cx1_mindestens_1x_Ueberlauf (CM_ESP_Wegimp_Ueberlauf_Cx1_mindestens_1x_Ueberlauf)}, range raw 0..1, transfer-property=PENDING  # Der Wegimpulszähler ist pro Zündungslauf mindestens einmal übergelaufen Weiterführende Informationen im Lastenheft spezifiziert und in der entsprechenden Fachabteilung zu erfragen.
          signal ESP_QBit_Wegimp_VA_XIX_ESP_24_XIX_E3V_K2CANFD: start 53, 1 bit, little-endian, data-type-policy=OVERRIDE, i-signal-type=PRIMITIVE, init-value=1, base-type=BT_ESP_QBit_Wegimp_VA, compu {0=Cx0_gueltiger_Wert (CM_ESP_QBit_Wegimp_VA_Cx0_gueltiger_Wert), 1=Cx1_Ersatz_Init_oder_Fehlerwert (CM_ESP_QBit_Wegimp_VA_Cx1_Ersatz_Init_oder_Fehlerwert)}, range raw 0..1, transfer-property=PENDING  # Gesetzt bei Ersatzwert, Init oder Fehler.
          signal ESP_HDC_FktLampe_XIX_ESP_24_XIX_E3V_K2CANFD: start 54, 1 bit, little-endian, data-type-policy=OVERRIDE, i-signal-type=PRIMITIVE, init-value=0, base-type=BT_ESP_HDC_FktLampe, compu {0=Cx0_Aus (CM_ESP_HDC_FktLampe_Cx0_Aus), 1=Cx1_Ein (CM_ESP_HDC_FktLampe_Cx1_Ein)}, range raw 0..1, transfer-property=PENDING  # Funktionslampe Bergabfahrassistent. (Sender blinkt mit dem Bit 3,3Hz)
          signal ESP_Off_Lampe_XIX_ESP_24_XIX_E3V_K2CANFD: start 55, 1 bit, little-endian, data-type-policy=OVERRIDE, i-signal-type=PRIMITIVE, init-value=0, base-type=BT_ESP_Off_Lampe, compu {0=Cx0_Lampe_aus (CM_ESP_Off_Lampe_Cx0_Lampe_aus), 1=Cx1_Lampe_ein (CM_ESP_Off_Lampe_Cx1_Lampe_ein)}, range raw 0..1, transfer-property=PENDING  # Bit zur Ansteuerung der separaten ESP-off-Lampe im Kombi (Gesetzesforderung USA) MLB: Verwendung/Bedienung ab D4
          signal ESP_HDC_Regelgeschw_XIX_ESP_24_XIX_E3V_K2CANFD: start 56, 7 bit, little-endian, data-type-policy=OVERRIDE, i-signal-type=PRIMITIVE, init-value=126, base-type=BT_ESP_HDC_Regelgeschw, invalid-value=Invalid_ESP_HDC_Regelgeschw_XIX_ESP_24_XIX_E3V_K2CANFD:127, compu {0=Cx0_nicht_verbaut (CM_ESP_HDC_Regelgeschw_Cx0_nicht_verbaut), phys=raw*0.32 for raw 1..124, 125=Cx7d_HDC_Standby (CM_ESP_HDC_Regelgeschw_Cx7d_HDC_Standby), 126=Cx7e_Init (CM_ESP_HDC_Regelgeschw_Cx7e_Init), 127=Cx7f_Fehler (CM_ESP_HDC_Regelgeschw_Cx7f_Fehler); unit Unit_KiloMeterPerHour}, range phys 0.32..39.68 Unit_KiloMeterPerHour, raw 0..127, unit=Unit_KiloMeterPerHour, transfer-property=PENDING  # Verwendung/Bedienung nur im AU57x Allroad: HDC-Geschwindigkeit Dient der Anzeige der HDC-Geschwindigkeit und eines Bergabfahrsymbols im Kombi. HDC-Standby wird gesetzt sobald der Fahrer den HDC-Taster aktiviert hat. Bei HDC-Off oder während der Initialisierung wird der Initwert gesetzt.
          signal ESP_BKV_Warnung_XIX_ESP_24_XIX_E3V_K2CANFD: start 63, 1 bit, little-endian, data-type-policy=OVERRIDE, i-signal-type=PRIMITIVE, init-value=0, base-type=BT_ESP_BKV_Warnung, compu {0=Cx0_keine_Anzeige (CM_ESP_BKV_Warnung_Cx0_keine_Anzeige), 1=Cx1_keine_Bremskraftverstaerkung (CM_ESP_BKV_Warnung_Cx1_keine_Bremskraftverstaerkung)}, range raw 0..1, transfer-property=PENDING  # ESP sendet im Hinweis- /Störungsfall an das Kombi Informationen zum Anzeigen (Text + Akustik) Im MQB wird dieses Signal nicht unterstützt!
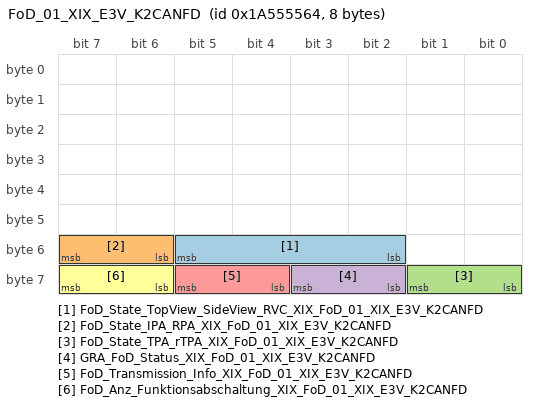
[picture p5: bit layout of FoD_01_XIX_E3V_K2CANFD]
      frame FoD_01_XIX_E3V_K2CANFD: id 0x1A555564, to SAM, frame-length=8, can-addressing-mode=EXTENDED, can-frame-rx-behavior=CAN-FD, can-frame-tx-behavior=CAN-FD
        pdu FoD_01_XIX_E3V_K2CANFD: length=8, minimum-delay=0.2, transmission-mode-true-timing={cyclic-timing={time-offset=0.0, time-period=1.0}, event-controlled-timing={number-of-repetitions=0, repetition-period=0.0}}, unused-bit-pattern=0
          signal FoD_State_TopView_SideView_RVC_XIX_FoD_01_XIX_E3V_K2CANFD: start 50, 4 bit, little-endian, data-type-policy=OVERRIDE, i-signal-type=PRIMITIVE, init-value=0, base-type=BT_FoD_State_TopView_SideView_RVC, compu {0=Cx0_default (CM_FoD_State_TopView_SideView_RVC_Cx0_default), 1=Cx1_RVC_TopView_SideView_nicht_aktiv (CM_FoD_State_TopView_SideView_RVC_Cx1_RVC_TopView_SideView_nicht_aktiv), 2=Cx2_RVC_aktiv (CM_FoD_State_TopView_SideView_RVC_Cx2_RVC_aktiv), 3=Cx3_RVC_nicht_aktiv (CM_FoD_State_TopView_SideView_RVC_Cx3_RVC_nicht_aktiv), 4=Cx4_TopView_SideView_nicht_aktiv (CM_FoD_State_TopView_SideView_RVC_Cx4_TopView_SideView_nicht_aktiv), 5=Cx5_RVC_TopView_aktiv (CM_FoD_State_TopView_SideView_RVC_Cx5_RVC_TopView_aktiv), 6=Cx6_SideView_aktiv (CM_FoD_State_TopView_SideView_RVC_Cx6_SideView_aktiv), 7=Cx7_RVC_SideView_aktiv (CM_FoD_State_TopView_SideView_RVC_Cx7_RVC_SideView_aktiv), 8=Cx8_RVC_TopView_SideView_aktiv (CM_FoD_State_TopView_SideView_RVC_Cx8_RVC_TopView_SideView_aktiv)}, range raw 0..8, transfer-property=PENDING  # Function on Demand State for TopView and SideView and RearView
          signal FoD_State_IPA_RPA_XIX_FoD_01_XIX_E3V_K2CANFD: start 54, 2 bit, little-endian, data-type-policy=OVERRIDE, i-signal-type=PRIMITIVE, init-value=0, base-type=BT_FoD_State_IPA_RPA, compu {0=Cx0_default (CM_FoD_State_IPA_RPA_Cx0_default), 1=Cx1_nicht_aktiv (CM_FoD_State_IPA_RPA_Cx1_nicht_aktiv), 2=Cx2_IPA_aktiv (CM_FoD_State_IPA_RPA_Cx2_IPA_aktiv), 3=Cx3_IPA_und_RPA_aktiv (CM_FoD_State_IPA_RPA_Cx3_IPA_und_RPA_aktiv)}, range raw 0..3, transfer-property=PENDING  # Function on Demand Activation State for IPA and RPA
          signal FoD_State_TPA_rTPA_XIX_FoD_01_XIX_E3V_K2CANFD: start 56, 2 bit, little-endian, data-type-policy=OVERRIDE, i-signal-type=PRIMITIVE, init-value=0, base-type=BT_FoD_State_TPA_rTPA, compu {0=Cx0_default (CM_FoD_State_TPA_rTPA_Cx0_default), 1=Cx1_nicht_aktiv (CM_FoD_State_TPA_rTPA_Cx1_nicht_aktiv), 2=Cx2_TPA_aktiv (CM_FoD_State_TPA_rTPA_Cx2_TPA_aktiv), 3=Cx3_TPA_und_rTPA_aktiv (CM_FoD_State_TPA_rTPA_Cx3_TPA_und_rTPA_aktiv)}, range raw 0..3, transfer-property=PENDING  # Function on Demand Activation State for TPA and rTPA from Function Master
          signal GRA_FoD_Status_XIX_FoD_01_XIX_E3V_K2CANFD: start 58, 2 bit, little-endian, data-type-policy=OVERRIDE, i-signal-type=PRIMITIVE, init-value=0, base-type=BT_GRA_FoD_Status, compu {0=Cx0_Init (CM_GRA_FoD_Status_Cx0_Init), 1=Cx1_Funktion_inaktiv (CM_GRA_FoD_Status_Cx1_Funktion_inaktiv), 2=Cx2_Funktion_aktiv (CM_GRA_FoD_Status_Cx2_Funktion_aktiv)}, range raw 0..2, transfer-property=TRIGGERED-ON-CHANGE-WITHOUT-REPETITION  # Verortung des FOD-Slaves für die Funktion GRA erfolgt im Gateway. Signal übermittelt den FOD-Status an das MSG.
          signal FoD_Transmission_Info_XIX_FoD_01_XIX_E3V_K2CANFD: start 60, 2 bit, little-endian, data-type-policy=OVERRIDE, i-signal-type=PRIMITIVE, init-value=0, base-type=BT_FoD_Transmission_Info, compu {0=Cx0_Initwert (CM_FoD_Transmission_Info_Cx0_Initwert), 1=Cx1_start_transmission (CM_FoD_Transmission_Info_Cx1_start_transmission), 2=Cx2_finish_transmission (CM_FoD_Transmission_Info_Cx2_finish_transmission)}, range raw 0..2, transfer-property=TRIGGERED-ON-CHANGE-WITHOUT-REPETITION, to SAM(timeout 5 s)  # Mit dem Signal zeigt der FoD-Master allen FoD-Slaves den Beginn und das Ende eines Freischaltuebertragungszykluses (FS-ID-Zyklus) an.
          signal FoD_Anz_Funktionsabschaltung_XIX_FoD_01_XIX_E3V_K2CANFD: start 62, 2 bit, little-endian, data-type-policy=OVERRIDE, i-signal-type=PRIMITIVE, init-value=0, base-type=BT_FoD_Anz_Funktionsabschaltung, compu {0=Cx0_Init (CM_FoD_Anz_Funktionsabschaltung_Cx0_Init), 1=Cx1_Popup_aufschalten (CM_FoD_Anz_Funktionsabschaltung_Cx1_Popup_aufschalten)}, range raw 0..1, transfer-property=TRIGGERED-ON-CHANGE-WITHOUT-REPETITION  # Signal triggert Aufschaltung eines Popups, um dem Fahrer die Abschaltung einer Funktion zu melden.
      frame FoD_BCM1_Req_XIX_E3V_K2CANFD: id 0x17FC030E, to SAM, frame-length=8, can-addressing-mode=EXTENDED, can-frame-rx-behavior=CAN-FD, can-frame-tx-behavior=CAN-FD
        n pdu FoD_BCM1_Req_XIX_E3V_K2CANFD: length=8
      frame FoD_BCM1_Resp_XIX_E3V_K2CANFD: id 0x17FE030E, from SAM, frame-length=8, can-addressing-mode=EXTENDED, can-frame-rx-behavior=CAN-FD, can-frame-tx-behavior=CAN-FD
        n pdu FoD_BCM1_Resp_XIX_E3V_K2CANFD: length=8
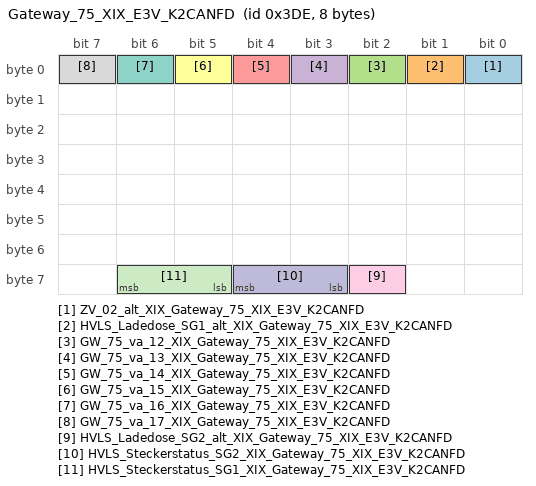
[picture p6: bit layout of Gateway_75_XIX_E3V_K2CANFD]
      frame Gateway_75_XIX_E3V_K2CANFD: id 0x3DE, to SAM, frame-length=8, can-addressing-mode=STANDARD, can-frame-rx-behavior=CAN-FD, can-frame-tx-behavior=CAN-FD
        pdu Gateway_75_XIX_E3V_K2CANFD: length=8, minimum-delay=0.01, transmission-mode-true-timing={cyclic-timing={time-offset=0, time-period=0.1}, event-controlled-timing={number-of-repetitions=0, repetition-period=0.0}}, unused-bit-pattern=0
          signal ZV_02_alt_XIX_Gateway_75_XIX_E3V_K2CANFD: start 0, 1 bit, little-endian, data-type-policy=OVERRIDE, i-signal-type=PRIMITIVE, init-value=1, base-type=BT_ZV_02_alt, compu {0=Cx0_aktuell (CM_ZV_02_alt_Cx0_aktuell), 1=Cx1_veraltet (CM_ZV_02_alt_Cx1_veraltet)}, range raw 0..1, transfer-property=PENDING
          signal HVLS_Ladedose_SG1_alt_XIX_Gateway_75_XIX_E3V_K2CANFD: start 1, 1 bit, little-endian, data-type-policy=OVERRIDE, i-signal-type=PRIMITIVE, init-value=0, base-type=BT_HVLS_Ladedose_SG1_alt, compu {0=Cx0_aktuell (CM_HVLS_Ladedose_SG1_alt_Cx0_aktuell), 1=Cx1_veraltet (CM_HVLS_Ladedose_SG1_alt_Cx1_veraltet)}, range raw 0..1, transfer-property=PENDING, to SAM(timeout 1 s)
          signal GW_75_va_12_XIX_Gateway_75_XIX_E3V_K2CANFD: start 2, 1 bit, little-endian, data-type-policy=OVERRIDE, i-signal-type=PRIMITIVE, init-value=1, base-type=BT_GW_75_va_12, transfer-property=PENDING
          signal GW_75_va_13_XIX_Gateway_75_XIX_E3V_K2CANFD: start 3, 1 bit, little-endian, data-type-policy=OVERRIDE, i-signal-type=PRIMITIVE, init-value=1, base-type=BT_GW_75_va_13, transfer-property=PENDING
          signal GW_75_va_14_XIX_Gateway_75_XIX_E3V_K2CANFD: start 4, 1 bit, little-endian, data-type-policy=OVERRIDE, i-signal-type=PRIMITIVE, init-value=1, base-type=BT_GW_75_va_14, transfer-property=PENDING
          signal GW_75_va_15_XIX_Gateway_75_XIX_E3V_K2CANFD: start 5, 1 bit, little-endian, data-type-policy=OVERRIDE, i-signal-type=PRIMITIVE, init-value=1, base-type=BT_GW_75_va_15, transfer-property=PENDING
          signal GW_75_va_16_XIX_Gateway_75_XIX_E3V_K2CANFD: start 6, 1 bit, little-endian, data-type-policy=OVERRIDE, i-signal-type=PRIMITIVE, init-value=1, base-type=BT_GW_75_va_16, transfer-property=PENDING
          signal GW_75_va_17_XIX_Gateway_75_XIX_E3V_K2CANFD: start 7, 1 bit, little-endian, data-type-policy=OVERRIDE, i-signal-type=PRIMITIVE, init-value=1, base-type=BT_GW_75_va_17, transfer-property=PENDING
          signal HVLS_Ladedose_SG2_alt_XIX_Gateway_75_XIX_E3V_K2CANFD: start 58, 1 bit, little-endian, data-type-policy=OVERRIDE, i-signal-type=PRIMITIVE, init-value=0, base-type=BT_HVLS_Ladedose_SG2_alt, compu {0=Cx0_aktuell (CM_HVLS_Ladedose_SG2_alt_Cx0_aktuell), 1=Cx1_veraltet (CM_HVLS_Ladedose_SG2_alt_Cx1_veraltet)}, range raw 0..1, transfer-property=PENDING, to SAM(timeout 1 s)
          signal HVLS_Steckerstatus_SG2_XIX_Gateway_75_XIX_E3V_K2CANFD: start 59, 2 bit, little-endian, data-type-policy=OVERRIDE, i-signal-type=PRIMITIVE, init-value=0, base-type=BT_HVLS_Steckerstatus_SG2, invalid-value=Invalid_HVLS_Steckerstatus_SG2_XIX_Gateway_75_XIX_E3V_K2CANFD:3, compu {0=Cx0_Init (CM_HVLS_Steckerstatus_SG2_Cx0_Init), 1=Cx1_kein_Stecker_erkannt (CM_HVLS_Steckerstatus_SG2_Cx1_kein_Stecker_erkannt), 2=Cx2_Stecker_erkannt (CM_HVLS_Steckerstatus_SG2_Cx2_Stecker_erkannt), 3=Cx3_Fehler (CM_HVLS_Steckerstatus_SG2_Cx3_Fehler)}, range raw 0..3, transfer-property=TRIGGERED-ON-CHANGE-WITHOUT-REPETITION, to SAM(timeout 1 s)  # Stellt den Status eines Ladesteckers am Steuergerät hinsichtlich Präsenz zur Verfügung
          signal HVLS_Steckerstatus_SG1_XIX_Gateway_75_XIX_E3V_K2CANFD: start 61, 2 bit, little-endian, data-type-policy=OVERRIDE, i-signal-type=PRIMITIVE, init-value=0, base-type=BT_HVLS_Steckerstatus_SG1, invalid-value=Invalid_HVLS_Steckerstatus_SG1_XIX_Gateway_75_XIX_E3V_K2CANFD:3, compu {0=Cx0_Init (CM_HVLS_Steckerstatus_SG1_Cx0_Init), 1=Cx1_kein_Stecker_erkannt (CM_HVLS_Steckerstatus_SG1_Cx1_kein_Stecker_erkannt), 2=Cx2_Stecker_erkannt (CM_HVLS_Steckerstatus_SG1_Cx2_Stecker_erkannt), 3=Cx3_Fehler (CM_HVLS_Steckerstatus_SG1_Cx3_Fehler)}, range raw 0..3, transfer-property=TRIGGERED-ON-CHANGE-WITHOUT-REPETITION, to SAM(timeout 1 s)  # Stellt den Status eines Ladesteckers am Steuergerät hinsichtlich Präsenz zur Verfügung
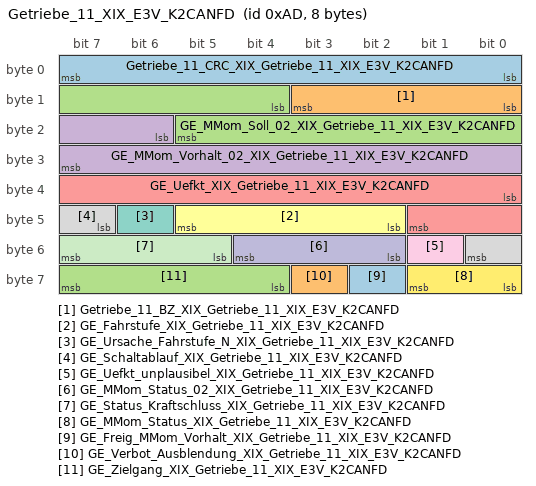
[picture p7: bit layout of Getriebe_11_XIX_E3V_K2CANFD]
      frame Getriebe_11_XIX_E3V_K2CANFD: id 0xAD, to SAM, frame-length=8, can-addressing-mode=STANDARD, can-frame-rx-behavior=CAN-FD, can-frame-tx-behavior=CAN-FD
        pdu Getriebe_11_XIX_E3V_K2CANFD: length=8, transmission-mode-true-timing=cyclic-timing={time-offset=0.0, time-period=0.05}, unused-bit-pattern=0
          signal Getriebe_11_CRC_XIX_Getriebe_11_XIX_E3V_K2CANFD: start 0, 8 bit, little-endian, data-type-policy=OVERRIDE, i-signal-type=PRIMITIVE, base-type=BT_Getriebe_11_CRC, compu {phys=raw for raw 0..255}, range phys 0..255, raw 0..255, transfer-property=PENDING  # Für MLB: "Berechnung siehe Lastenheft "Kommunikationsabsicherung für FlexRay und CAN"" Ab MQB und MLBevo: "Berechnung siehe Lastenheft "End-to-End Kommunikationsabsicherung"" Endwerte siehe Begleitdokument "S-PDU Kennungsfolgen"
          signal Getriebe_11_BZ_XIX_Getriebe_11_XIX_E3V_K2CANFD: start 8, 4 bit, little-endian, data-type-policy=OVERRIDE, i-signal-type=PRIMITIVE, init-value=0, base-type=BT_Getriebe_11_BZ, compu {phys=raw for raw 0..15}, range phys 0..15, raw 0..15, transfer-property=PENDING  # Botschaftszähler
          signal GE_MMom_Soll_02_XIX_Getriebe_11_XIX_E3V_K2CANFD: start 12, 10 bit, little-endian, data-type-policy=OVERRIDE, i-signal-type=PRIMITIVE, init-value=1022, base-type=BT_GE_MMom_Soll_02, invalid-value=Invalid_GE_MMom_Soll_02_XIX_Getriebe_11_XIX_E3V_K2CANFD:1023, compu {phys=raw-509 for raw 0..1018, 1022=Cx3fe_keine_Anforderung_Init (CM_GE_MMom_Soll_02_Cx3fe_keine_Anforderung_Init), 1023=Cx3ff_Fehler (CM_GE_MMom_Soll_02_Cx3ff_Fehler)}, range phys -509..509, raw 0..1023, transfer-property=PENDING  # Momenteneingriff an den Motor. Fordert vom MSG eine kurzfristige Reduzierung oder Anhebung des Moments. Das Signal ist nur gültig in Kombination mit GE_MMom_Status (bei MQB) bzw. GE_MMom_Status_02 (bei MLBevo). Achtung: Einheitenloser Wert! Faktor in MO_Faktor_Momente_02 in Motor_Code_01 beachten!
          signal GE_MMom_Vorhalt_02_XIX_Getriebe_11_XIX_E3V_K2CANFD: start 22, 10 bit, little-endian, data-type-policy=OVERRIDE, i-signal-type=PRIMITIVE, init-value=1022, base-type=BT_GE_MMom_Vorhalt_02, invalid-value=Invalid_GE_MMom_Vorhalt_02_XIX_Getriebe_11_XIX_E3V_K2CANFD:1023, compu {phys=raw-509 for raw 0..1018, 1022=Cx3fe_Init (CM_GE_MMom_Vorhalt_02_Cx3fe_Init), 1023=Cx3ff_Fehler (CM_GE_MMom_Vorhalt_02_Cx3ff_Fehler)}, range phys -509..509, raw 0..1023, transfer-property=PENDING  # Anforderung einer Momentenreserve durch das Getriebe, gilt nur mit Freigabe durch GE_Freig_MMom_Vorhalt Anforderung wird als Absolut-Wert umgesetzt, nicht als Relativ-Wert/Delta zum aktuellen Ist-Moment (d. h. eine Momentenreserve wird eingestellt, wenn die Vorhalt-Anforderung größer ist als das aktuelle Ist-Moment)! Momentenwert ist als Kupplungsmoment (=Motorausgangsmoment) definiert, nicht als indiziertes Moment! Achtung: Einheitenloser Wert! Faktor in MO_Faktor_Momente_02 in Motor_Code_01 beachten!
          signal GE_Uefkt_XIX_Getriebe_11_XIX_E3V_K2CANFD: start 32, 10 bit, little-endian, data-type-policy=OVERRIDE, i-signal-type=PRIMITIVE, init-value=0, base-type=BT_GE_Uefkt, invalid-value=Invalid_GE_Uefkt_XIX_Getriebe_11_XIX_E3V_K2CANFD:1023, compu {phys=raw*0.1 for raw 0..1022, 1023=Cx3ff_Fehler (CM_GE_Uefkt_Cx3ff_Fehler)}, range phys 0..102.2, raw 0..1023, transfer-property=PENDING  # Übertragungsfunktion des Getriebes Drehzahlverhältnis = Eingangsdrehzahl / Ausgangsdrehzahl AL: Wandlerverstärkung x Drehzahlverhältnis VL: Drehzahlverhältnis DL: Drehzahlverhältnis der aktiven und kraftschluß führenden Welle zum Abtrieb, bei Schaltvorgängen ist der Übergang von "alter" zu "neuer" aktiven Welle in Abhängigkeit vom Verhältnis der beiden Kupplungsdrücke. AL1000: außerhalb Schaltung: Wandlerverstärkung x Drehzahlverhältnis bei Rückschaltungen < 1 kmh: Drehzahlverhältnis des Zielgangs bei Hochschaltung < 1kmh: Drehzahlverhältnis des Istgangs
          signal GE_Fahrstufe_XIX_Getriebe_11_XIX_E3V_K2CANFD: start 42, 4 bit, little-endian, data-type-policy=OVERRIDE, i-signal-type=PRIMITIVE, init-value=1, base-type=BT_GE_Fahrstufe, invalid-value=Invalid_GE_Fahrstufe_XIX_Getriebe_11_XIX_E3V_K2CANFD:15, compu {0=Cx0_Zwischenstellung (CM_GE_Fahrstufe_Cx0_Zwischenstellung), 1=Cx1_Init (CM_GE_Fahrstufe_Cx1_Init), 5=Cx5_Position_P (CM_GE_Fahrstufe_Cx5_Position_P), 6=Cx6_Position_R (CM_GE_Fahrstufe_Cx6_Position_R), 7=Cx7_Position_N (CM_GE_Fahrstufe_Cx7_Position_N), 8=Cx8_Position_D (CM_GE_Fahrstufe_Cx8_Position_D), 9=Cx9_Position_S (CM_GE_Fahrstufe_Cx9_Position_S), 10=Cxa_Effizienz (CM_GE_Fahrstufe_Cxa_Effizienz), 13=Cxd_Tipp_in_S (CM_GE_Fahrstufe_Cxd_Tipp_in_S), 14=Cxe_Tipp_in_D (CM_GE_Fahrstufe_Cxe_Tipp_in_D), 15=Cxf_Fehler (CM_GE_Fahrstufe_Cxf_Fehler)}, range raw 0..15, transfer-property=PENDING, to SAM(timeout 0.5 s)  # Fahrprogramm des Getriebes Hinweis: Zwischenstellung "0x0" darf nur für Zustandswechsel P/R, R/N, N/D ausgegeben werden, nicht für D/S oder D/Tippgasse wegen Abschaltkriterium GRA/ACC
          signal GE_Ursache_Fahrstufe_N_XIX_Getriebe_11_XIX_E3V_K2CANFD: start 46, 1 bit, little-endian, data-type-policy=OVERRIDE, i-signal-type=PRIMITIVE, init-value=0, base-type=BT_GE_Ursache_Fahrstufe_N, compu {0=Cx0_Fahrstufe_N_mit_Fahrerwunsch (CM_GE_Ursache_Fahrstufe_N_Cx0_Fahrstufe_N_mit_Fahrerwunsch), 1=Cx1_Fahrstufe_N_ohne_Fahrerwunsch (CM_GE_Ursache_Fahrstufe_N_Cx1_Fahrstufe_N_ohne_Fahrerwunsch)}, range raw 0..1, transfer-property=PENDING  # Zeigt an, warum Fahrstufe N angenommen wurde. So kann z.B. die Rollsicherung im Verlassenskonzept aktiv bleiben, wenn das Schalten nach N ohne Fahrerwunsch erfolgte (z.B. Fehlerreaktion). ACHTUNG: Das Signal darf nur ausgewertet werden, wenn GE_Fahrstufe == N ist!
          signal GE_Schaltablauf_XIX_Getriebe_11_XIX_E3V_K2CANFD: start 47, 2 bit, little-endian, data-type-policy=OVERRIDE, i-signal-type=PRIMITIVE, init-value=0, base-type=BT_GE_Schaltablauf, compu {0=Cx0_keine_Schaltung (CM_GE_Schaltablauf_Cx0_keine_Schaltung), 1=Cx1_Momentenueberschneidung (CM_GE_Schaltablauf_Cx1_Momentenueberschneidung), 2=Cx2_Befuellphase (CM_GE_Schaltablauf_Cx2_Befuellphase), 3=Cx3_Drehzahlueberfuehrung (CM_GE_Schaltablauf_Cx3_Drehzahlueberfuehrung)}, range raw 0..3, transfer-property=PENDING  # Das Signal zeigt den aktuellen Status eines Schaltvorgangs. Bei Signal = 0 liegt kein Schaltvorgang vor. Bei Signal =2 liegt die Befüllphase der zuschaltenden Kupplung bzw. die Vorbereitungsphase dazu vor. Mit den unterschiedlichen Stati kann im Nutzer-SG detailliert gesteuert werden, in welcher Phase eine eigene Reaktion nötig ist.
          signal GE_Uefkt_unplausibel_XIX_Getriebe_11_XIX_E3V_K2CANFD: start 49, 1 bit, little-endian, data-type-policy=OVERRIDE, i-signal-type=PRIMITIVE, init-value=0, base-type=BT_GE_Uefkt_unplausibel, compu {0=Cx0_Uefkt_plausibel (CM_GE_Uefkt_unplausibel_Cx0_Uefkt_plausibel), 1=Cx1_Uefkt_unplausibel (CM_GE_Uefkt_unplausibel_Cx1_Uefkt_unplausibel)}, range raw 0..1, transfer-property=PENDING  # Das Signal darf nur im Reku-Manager in Hybrid-Varianten verwendet werden. Zeigt an, ob die Plausibilisierung Momenten-Verhältnis zu Drehzahl-Verhältnis i.O. ist. Ein gesetztes Signal meldet eine unplausible GE_Uefkt bzw. GE_Uefkt_02.
          signal GE_MMom_Status_02_XIX_Getriebe_11_XIX_E3V_K2CANFD: start 50, 3 bit, little-endian, data-type-policy=OVERRIDE, i-signal-type=PRIMITIVE, init-value=0, base-type=BT_GE_MMom_Status_02, compu {0=Cx0_kein_Eingriff (CM_GE_MMom_Status_02_Cx0_kein_Eingriff), 1=Cx1_abs_reduzierender_Eingriff_auf_Gesamt_Antrieb_nur_schneller_Pfad (CM_GE_MMom_Status_02_Cx1_abs_reduzierender_Eingriff_auf_Gesamt_Antrieb_nur_schneller_Pfad), 2=Cx2_abs_erhoehender_Eingriff_auf_Gesamt_Antrieb (CM_GE_MMom_Status_02_Cx2_abs_erhoehender_Eingriff_auf_Gesamt_Antrieb), 3=Cx3_relativer_Eingriff_auf_Gesamt_Antrieb (CM_GE_MMom_Status_02_Cx3_relativer_Eingriff_auf_Gesamt_Antrieb), 4=Cx4_relativer_Eingriff_auf_E_Maschine (CM_GE_MMom_Status_02_Cx4_relativer_Eingriff_auf_E_Maschine), 5=Cx5_abs_red_Eingr_auf_Gesamt_Antrieb_nur_Luftpfad (CM_GE_MMom_Status_02_Cx5_abs_red_Eingr_auf_Gesamt_Antrieb_nur_Luftpfad), 6=Cx6_abs_red_Eingr_auf_Gesamt_Antrieb_Luft_und_schnellen_Pfad (CM_GE_MMom_Status_02_Cx6_abs_red_Eingr_auf_Gesamt_Antrieb_Luft_und_schnellen_Pfad) (abs_red_Eingr_auf_Gesamt_Antrieb_Luft-_und_schnellen_Pfad), 7=Cx7_abs_Eingriff_auf_Gesamtantrieb_erhoehend_und_reduzierend (CM_GE_MMom_Status_02_Cx7_abs_Eingriff_auf_Gesamtantrieb_erhoehend_und_reduzierend)}, range raw 0..7, transfer-property=PENDING  # Das Signal qualifiziert GE_MMom_Soll_02 und gibt an, wie der Wert aus GE_MMom_soll – vorbehaltlich der Umsetzbarkeit aufgrund motorinterner Restriktionen – umgesetzt werden soll. Werte: 0= kein Eingriff 1= absoluter reduzierender Eingriff auf Gesamt Antrieb nur über schnellen Pfad 2 = absoluter, erhöhender Eingriff auf Gesamt-Antrieb 3 = relativer Eingriff auf Gesamt-Antrieb 4 = relativer Eingriff auf E-Maschine 5 = absoluter reduzierender Eingriff auf Gesamt Antrieb nur über Luftpfad 6 = absoluter reduzierender Eingriff auf Gesamt Antrieb über Luftpfad und schnellen Pfad 7 = abs_Eingriff_auf_Gesamtantrieb_erhoehend_und_reduzierend
          signal GE_Status_Kraftschluss_XIX_Getriebe_11_XIX_E3V_K2CANFD: start 53, 3 bit, little-endian, data-type-policy=OVERRIDE, i-signal-type=PRIMITIVE, init-value=0, base-type=BT_GE_Status_Kraftschluss, compu {0=Cx0_offen_kein_Kraftschluss (CM_GE_Status_Kraftschluss_Cx0_offen_kein_Kraftschluss), 1=Cx1_offen_mit_Kraftschluss (CM_GE_Status_Kraftschluss_Cx1_offen_mit_Kraftschluss), 2=Cx2_schlupfend_geregelt (CM_GE_Status_Kraftschluss_Cx2_schlupfend_geregelt), 3=Cx3_abgesichert_offen_kein_Kraftschl (CM_GE_Status_Kraftschluss_Cx3_abgesichert_offen_kein_Kraftschl), 4=Cx4_geschlossen_mit_Mikroschlupf (CM_GE_Status_Kraftschluss_Cx4_geschlossen_mit_Mikroschlupf), 5=Cx5_geschlossen_mit_Ueberanpressung (CM_GE_Status_Kraftschluss_Cx5_geschlossen_mit_Ueberanpressung), 6=Cx6_sonstige_Fehler (CM_GE_Status_Kraftschluss_Cx6_sonstige_Fehler), 7=Cx7_fehlerhaft_geschlossen (CM_GE_Status_Kraftschluss_Cx7_fehlerhaft_geschlossen)}, range raw 0..7, transfer-property=PENDING  # Zeigt den Ist-Status des Kraftschlusses im Getriebe. (Anmerkung: meist wird damit der Zustand des Anfahrelements beschrieben, d.h. bei DL/DQ die Kupplung; bei AQ/AL der Wandler incl. Überbrückungskupplung) 0 = offen, kein Kraftschluss 1 = offen mit Kraftschluss (d.h. bei AL/AQ: Überbrückungskupplung offen, aber Kraftschluss über Hydraulik) 2 = schlupfend/geregelt 3 = abgesichert offen, kein Kraftschluss (Wert darf ab Ersteinsatz MLBevoGen2 PO68x/992 nur nach vorheriger Abstimmung mit allen Empfängern gesendet werden und muss projektspezifisch abgrenzbar sein, da nicht Rückwärtskompatibel) 4 = geschlossen mit Mikroschlupf (im MQB: geschlossen, d. h. mit Überanpressung oder geschlossen mit Mirkoschlupf) 5 = geschlossen mit Überanpressung (wird im MQB nicht bedient) (Anmerkung: die Grenze zwischen schlupfend und geschlossen liegt üblicherweise bei ca. 10..50 1/min Schlupf)
          signal GE_MMom_Status_XIX_Getriebe_11_XIX_E3V_K2CANFD: start 56, 2 bit, little-endian, data-type-policy=OVERRIDE, i-signal-type=PRIMITIVE, init-value=0, base-type=BT_GE_MMom_Status, compu {0=Cx0_keine_Anforderung (CM_GE_MMom_Status_Cx0_keine_Anforderung) (keine Anforderung), 1=Cx1_reduzierender_Getriebeeingriff (CM_GE_MMom_Status_Cx1_reduzierender_Getriebeeingriff) (reduzierender Getriebeeingriff), 2=Cx2_erhoehender_Getriebeeingriff (CM_GE_MMom_Status_Cx2_erhoehender_Getriebeeingriff) (erhöhender Getriebeeingriff), 3=Cx3_aenderung_mit_Sprung (CM_GE_MMom_Status_Cx3_aenderung_mit_Sprung) (Änderung mit Sprung)}, range raw 0..3, transfer-property=PENDING  # Qualifiziert MLB: GE_MMom_Soll MQB: GE_MMom_Soll_02
          signal GE_Freig_MMom_Vorhalt_XIX_Getriebe_11_XIX_E3V_K2CANFD: start 58, 1 bit, little-endian, data-type-policy=OVERRIDE, i-signal-type=PRIMITIVE, init-value=0, base-type=BT_GE_Freig_MMom_Vorhalt, compu {0=Cx0_nicht_freigegeben (CM_GE_Freig_MMom_Vorhalt_Cx0_nicht_freigegeben), 1=Cx1_freigegeben (CM_GE_Freig_MMom_Vorhalt_Cx1_freigegeben)}, range raw 0..1, transfer-property=PENDING  # Freigabe für die Anforderung einer Momentenreserve durch das Getriebe über das Signal MLB: GE_MMom_Vorhalt MQB/MLBevo: GE_MMom_Vorhalt_02
          signal GE_Verbot_Ausblendung_XIX_Getriebe_11_XIX_E3V_K2CANFD: start 59, 1 bit, little-endian, data-type-policy=OVERRIDE, i-signal-type=PRIMITIVE, init-value=0, base-type=BT_GE_Verbot_Ausblendung, compu {0=Cx0_kein_Verbot (CM_GE_Verbot_Ausblendung_Cx0_kein_Verbot), 1=Cx1_Verbot (CM_GE_Verbot_Ausblendung_Cx1_Verbot)}, range raw 0..1, transfer-property=PENDING  # Verbot Einspritzausblendung für komfortable Schaltungen
          signal GE_Zielgang_XIX_Getriebe_11_XIX_E3V_K2CANFD: start 60, 4 bit, little-endian, data-type-policy=OVERRIDE, i-signal-type=PRIMITIVE, init-value=0, base-type=BT_GE_Zielgang, invalid-value=Invalid_GE_Zielgang_XIX_Getriebe_11_XIX_E3V_K2CANFD:15, compu {0=Cx0_Gang_P_N_ausgekuppelt (CM_GE_Zielgang_Cx0_Gang_P_N_ausgekuppelt) (Gang P/N (ausgekuppelt)), 1=Cx1_Gang_1 (CM_GE_Zielgang_Cx1_Gang_1) (Gang 1), 2=Cx2_Gang_2 (CM_GE_Zielgang_Cx2_Gang_2) (Gang 2), 3=Cx3_Gang_3 (CM_GE_Zielgang_Cx3_Gang_3) (Gang 3), 4=Cx4_Gang_4 (CM_GE_Zielgang_Cx4_Gang_4) (Gang 4), 5=Cx5_Gang_5 (CM_GE_Zielgang_Cx5_Gang_5) (Gang 5), 6=Cx6_Gang_6 (CM_GE_Zielgang_Cx6_Gang_6) (Gang 6), 7=Cx7_Gang_7 (CM_GE_Zielgang_Cx7_Gang_7) (Gang 7), 8=Cx8_Gang_R (CM_GE_Zielgang_Cx8_Gang_R) (Gang R), 11=Cxb_Gang_8 (CM_GE_Zielgang_Cxb_Gang_8) (Gang 8), 12=Cxc_Gang_9 (CM_GE_Zielgang_Cxc_Gang_9) (Gang 9), 13=Cxd_Gang10 (CM_GE_Zielgang_Cxd_Gang10), 14=Cxe_Istgang_nicht_definiert (CM_GE_Zielgang_Cxe_Istgang_nicht_definiert) (Istgang nicht definiert), 15=Cxf_Fehler (CM_GE_Zielgang_Cxf_Fehler)}, range raw 0..15, transfer-property=PENDING  # VL-Getriebe: Signalisiert den Zielgang im manuellen Modus während eines Schaltvorgangs bzw. die momentane simulierte Gangstufe wenn kein Schaltvorgang aktiv ist. In den Fahrprogrammen "D" und "S" ist die Übersetzung variabel und somit wird dauerhaft "Istgang nicht definiert" ausgegeben (auch bei Wählhebel entgegen der Fahrtrichtung). In den Wählhebelpositionen P oder N wird als Zielgang immer 0 ausgegeben. Sonderfälle: Bei Kraftschlußunterbrechung in D,R und S wird "P/N ausgekuppelt" ausgegeben (z.B. Fehlerfall) Die Fahrstufe R wird erst bei Ansteuerung der Rückwärtskupplung ausgegeben bei höheren Geschwindigkeiten vorwärts wird 0x0 ausgegeben. In den Wählhebelzwischenpositionen wird 0x0 ausgegeben. Bei Motor = aus wird in allen Fahrstufen 0x0 ausgegeben, ausser in der Gasse da "nicht definiert". DL-Getriebe: tbd. AL-Getriebe: Gibt den Zielgang bei GE_Schaltvorgang = Schaltung aktiv und den Istgang wenn GE-Schaltvorgang = keine Schaltung aus. In den Wählhebelpositionen P oder N wird als Zielgang immer 0 ausgegeben. Sonderfälle: Bei Kraftschlußunterbrechung in D,R und S wird der Gang des hydraulischen Notlaufs ausgegeben. (z.B: Fehlerfall). Die Fahrstufe R wird erst bei Ansteuerung der Rückwärtskupplung ausgegeben bei höheren Geschwindigkeiten vorwärts wird 0x0 ausgegeben. Bei Wechsel in eine Wählhebelzwischenposition wird der vorherige Wert von GE_Zielgang weiter ausgegeben. Bei Standabkopplung geben die ZF-Stufenautomaten den eingelegten Gang aus.
      frame GRA_ACC_01_XIX_E3V_K2CANFD: id 0x12B, from SAM, frame-length=8, can-addressing-mode=STANDARD, can-frame-rx-behavior=CAN-FD, can-frame-tx-behavior=CAN-FD
        pdu GRA_ACC_01_XIX_E3V_K2CANFD: length=8, transmission-mode-true-timing=cyclic-timing={time-offset=0.0, time-period=0.03}, unused-bit-pattern=0
          signal GRA_ACC_01_CRC_XIX_GRA_ACC_01_XIX_E3V_K2CANFD: start 0, 8 bit, little-endian, data-type-policy=OVERRIDE, i-signal-type=PRIMITIVE, base-type=BT_GRA_ACC_01_CRC, compu {phys=raw for raw 0..255}, range phys 0..255, raw 0..255, transfer-property=PENDING  # Für MLB: "Berechnung siehe Lastenheft "Kommunikationsabsicherung für FlexRay und CAN"" Ab MQB und MLBevo: "Berechnung siehe Lastenheft "End-to-End Kommunikationsabsicherung"" Endwerte siehe Begleitdokument "S-PDU Kennungsfolgen"
          signal GRA_ACC_01_BZ_XIX_GRA_ACC_01_XIX_E3V_K2CANFD: start 8, 4 bit, little-endian, data-type-policy=OVERRIDE, i-signal-type=PRIMITIVE, base-type=BT_GRA_ACC_01_BZ, compu {phys=raw for raw 0..15}, range phys 0..15, raw 0..15, transfer-property=PENDING  # 4bit Botschaftszaehler, wird mit jeder Sendebotschaft inkrementiert
          signal GRA_Hauptschalter_XIX_GRA_ACC_01_XIX_E3V_K2CANFD: start 12, 1 bit, little-endian, data-type-policy=OVERRIDE, i-signal-type=PRIMITIVE, init-value=0, base-type=BT_GRA_Hauptschalter, compu {0=Cx0_Aus_Taster_nicht_betaetigt (CM_GRA_Hauptschalter_Cx0_Aus_Taster_nicht_betaetigt), 1=Cx1_Ein_Taster_betaetigt (CM_GRA_Hauptschalter_Cx1_Ein_Taster_betaetigt)}, range raw 0..1, transfer-property=PENDING  # Stellung des GRA/ACC-Hauptschalters: Bei gerastetem Hauptschalter: 0: Hauptschalter aus 1: Hauptschalter ein Bei getastetem Hauptschalter: 0: Taster nicht betätigt 1: Taster betätigt
          signal GRA_Abbrechen_XIX_GRA_ACC_01_XIX_E3V_K2CANFD: start 13, 1 bit, little-endian, data-type-policy=OVERRIDE, i-signal-type=PRIMITIVE, init-value=0, base-type=BT_GRA_Abbrechen, compu {0=Cx0_nicht_betaetigt (CM_GRA_Abbrechen_Cx0_nicht_betaetigt), 1=Cx1_betaetigt (CM_GRA_Abbrechen_Cx1_betaetigt)}, range raw 0..1, transfer-property=PENDING  # GRA : aus mit speichern ACC : Soft aus
          signal GRA_Typ_Hauptschalter_XIX_GRA_ACC_01_XIX_E3V_K2CANFD: start 14, 1 bit, little-endian, data-type-policy=OVERRIDE, i-signal-type=PRIMITIVE, base-type=BT_GRA_Typ_Hauptschalter, compu {0=Cx0_gerasteter_Lenkstockschalter (CM_GRA_Typ_Hauptschalter_Cx0_gerasteter_Lenkstockschalter), 1=Cx1_getasteter_Lenkstockschalter (CM_GRA_Typ_Hauptschalter_Cx1_getasteter_Lenkstockschalter)}, range raw 0..1, transfer-property=PENDING  # Variante des GRA/ACC-Hauptschalters: 0: gerasteter Hauptschalter (bzw. Taster mit Speicherung des Status im SMLS (PAG)) 1: getasteter Hauptschalter, keine Speicherung des Status im SMLS
          signal GRA_Limiter_XIX_GRA_ACC_01_XIX_E3V_K2CANFD: start 15, 1 bit, little-endian, data-type-policy=OVERRIDE, i-signal-type=PRIMITIVE, init-value=0, base-type=BT_GRA_Limiter, compu {0=Cx0_nicht_betaetigt (CM_GRA_Limiter_Cx0_nicht_betaetigt), 1=Cx1_betaetigt (CM_GRA_Limiter_Cx1_betaetigt)}, range raw 0..1, transfer-property=PENDING  # Stellung des Limiter-Tasters
          signal GRA_Tip_Setzen_XIX_GRA_ACC_01_XIX_E3V_K2CANFD: start 16, 1 bit, little-endian, data-type-policy=OVERRIDE, i-signal-type=PRIMITIVE, init-value=0, base-type=BT_GRA_Tip_Setzen, compu {0=Cx0_nicht_betaetigt (CM_GRA_Tip_Setzen_Cx0_nicht_betaetigt), 1=Cx1_betaetigt (CM_GRA_Tip_Setzen_Cx1_betaetigt)}, range raw 0..1, transfer-property=PENDING  # Tippschalter Set
          signal GRA_Tip_Hoch_XIX_GRA_ACC_01_XIX_E3V_K2CANFD: start 17, 1 bit, little-endian, data-type-policy=OVERRIDE, i-signal-type=PRIMITIVE, init-value=0, base-type=BT_GRA_Tip_Hoch, compu {0=Cx0_nicht_betaetigt (CM_GRA_Tip_Hoch_Cx0_nicht_betaetigt), 1=Cx1_betaetigt (CM_GRA_Tip_Hoch_Cx1_betaetigt)}, range raw 0..1, transfer-property=PENDING  # Tippschalter Tip Up / Geschwindigkeit erhöhen
          signal GRA_Tip_Runter_XIX_GRA_ACC_01_XIX_E3V_K2CANFD: start 18, 1 bit, little-endian, data-type-policy=OVERRIDE, i-signal-type=PRIMITIVE, init-value=0, base-type=BT_GRA_Tip_Runter, compu {0=Cx0_nicht_betaetigt (CM_GRA_Tip_Runter_Cx0_nicht_betaetigt), 1=Cx1_betaetigt (CM_GRA_Tip_Runter_Cx1_betaetigt)}, range raw 0..1, transfer-property=PENDING  # Tippschalter Tip Down / Geschwindigkeit reduzieren
          signal GRA_Tip_Wiederaufnahme_XIX_GRA_ACC_01_XIX_E3V_K2CANFD: start 19, 1 bit, little-endian, data-type-policy=OVERRIDE, i-signal-type=PRIMITIVE, init-value=0, base-type=BT_GRA_Tip_Wiederaufnahme, compu {0=Cx0_nicht_betaetigt (CM_GRA_Tip_Wiederaufnahme_Cx0_nicht_betaetigt), 1=Cx1_betaetigt (CM_GRA_Tip_Wiederaufnahme_Cx1_betaetigt)}, range raw 0..1, transfer-property=PENDING  # Tippschalter Wiederaufnahme
          signal GRA_Verstellung_Zeitluecke_XIX_GRA_ACC_01_XIX_E3V_K2CANFD: start 20, 2 bit, little-endian, data-type-policy=OVERRIDE, i-signal-type=PRIMITIVE, init-value=0, base-type=BT_GRA_Verstellung_Zeitluecke, compu {0=Cx0_Taste_nicht_betaetigt (CM_GRA_Verstellung_Zeitluecke_Cx0_Taste_nicht_betaetigt), 1=Cx1_Dist_minus_1 (CM_GRA_Verstellung_Zeitluecke_Cx1_Dist_minus_1), 2=Cx2_Dist_plus_1 (CM_GRA_Verstellung_Zeitluecke_Cx2_Dist_plus_1), 3=Cx3_Dist_Toggle (CM_GRA_Verstellung_Zeitluecke_Cx3_Dist_Toggle)}, range raw 0..3, transfer-property=PENDING  # Verstellung der Zeitlücke für ACC DIST -1 = Zeitluecke um 1 Stufe kleiner DIST +1 = Zeitluecke um 1 Stufe groeßer DIST Toggle = Zeitlücke um 1 Stufe kleiner, von kleinster Stufe auf größte Stufe
          signal GRA_Codierung_XIX_GRA_ACC_01_XIX_E3V_K2CANFD: start 22, 2 bit, little-endian, data-type-policy=OVERRIDE, i-signal-type=PRIMITIVE, init-value=0, base-type=BT_GRA_Codierung, compu {0=Cx0_kein_Hebel (CM_GRA_Codierung_Cx0_kein_Hebel), 1=Cx1_GRA_Hebel (CM_GRA_Codierung_Cx1_GRA_Hebel), 2=Cx2_ACC_Hebel (CM_GRA_Codierung_Cx2_ACC_Hebel), 3=Cx3_Limiter_Only (CM_GRA_Codierung_Cx3_Limiter_Only)}, range raw 0..3, transfer-property=PENDING  # Das Signal zeigt an, ob das Sende-SG (SMLS/MFL) auf GRA- oder ACC-Bedienteil codiert ist: 0: kein GRA- oder ACC Bedienteil 1: GRA-Bedienteil 2: ACC-Bedienteil 3: Limiter_Only-Bedienteil
          signal GRA_Fehler_XIX_GRA_ACC_01_XIX_E3V_K2CANFD: start 24, 1 bit, little-endian, data-type-policy=OVERRIDE, i-signal-type=PRIMITIVE, init-value=0, base-type=BT_GRA_Fehler, invalid-value=Invalid_GRA_Fehler_XIX_GRA_ACC_01_XIX_E3V_K2CANFD:1, compu {0=Cx0_kein_Fehler (CM_GRA_Fehler_Cx0_kein_Fehler), 1=Cx1_Fehler (CM_GRA_Fehler_Cx1_Fehler)}, range raw 0..1, transfer-property=PENDING  # Das Signal zeigt an, dass das Sende-SG (SMLS/MFG) einen Defekt des GRA-Bedienteils erkannt hat und hierzu ein FSPE abgelegt wurde.
          signal GRA_LIM_Taste_verfuegbar_XIX_GRA_ACC_01_XIX_E3V_K2CANFD: start 25, 1 bit, little-endian, data-type-policy=OVERRIDE, i-signal-type=PRIMITIVE, base-type=BT_GRA_LIM_Taste_verfuegbar, compu {0=Cx0_Limiter_Taste_nicht_vorhanden (CM_GRA_LIM_Taste_verfuegbar_Cx0_Limiter_Taste_nicht_vorhanden), 1=Cx1_Limiter_Taste_vorhanden (CM_GRA_LIM_Taste_verfuegbar_Cx1_Limiter_Taste_vorhanden)}, range raw 0..1, transfer-property=PENDING  # Das Signal zeigt an, ob eine Limiter-Umschalttaste am jeweiligen GRA/ACC-Bedienelement vorhanden ist.
          signal GRA_Tip_Stufe_2_XIX_GRA_ACC_01_XIX_E3V_K2CANFD: start 26, 1 bit, little-endian, data-type-policy=OVERRIDE, i-signal-type=PRIMITIVE, init-value=0, base-type=BT_GRA_Tip_Stufe_2, compu {0=Cx0_Tip_Stufe_1_keine_Betaetigung (CM_GRA_Tip_Stufe_2_Cx0_Tip_Stufe_1_keine_Betaetigung), 1=Cx1_Tip_Stufe_2 (CM_GRA_Tip_Stufe_2_Cx1_Tip_Stufe_2)}, range raw 0..1, transfer-property=PENDING  # Signal zeigt an, dass der zweistufige GRA/ACC-Hebel (8_Positions_Bedienteil) in der 2. Tip-Stufe betätigt wird. Das Signal wird nur gleichzeitig mit dem Signal GRA_Tip_Hoch oder GRA_Tip_Runter gesetzt, wobei die Bits GRA_Tip_Hoch bzw. GRA_Tip_Runter die Richtung der Hebelbetätigung anzeigen und der Status von GRA_Tip_Stufe_2 kennzeichnet, ob die Betätigung in der ersten oder zweiten Tip-Stufe erfolgt. 0 = Tip_Stufe_1 oder keine Betätigung 1 = Tip_Stufe_2
          signal GRA_Typ_Bedienteil_XIX_GRA_ACC_01_XIX_E3V_K2CANFD: start 27, 3 bit, little-endian, data-type-policy=OVERRIDE, i-signal-type=PRIMITIVE, init-value=0, base-type=BT_GRA_Typ_Bedienteil, compu {0=Cx0_Init (CM_GRA_Typ_Bedienteil_Cx0_Init), 1=Cx1_4_Positions_Bedienteil (CM_GRA_Typ_Bedienteil_Cx1_4_Positions_Bedienteil), 2=Cx2_6_Positions_Bedienteil (CM_GRA_Typ_Bedienteil_Cx2_6_Positions_Bedienteil), 3=Cx3_8_Positions_Bedienteil (CM_GRA_Typ_Bedienteil_Cx3_8_Positions_Bedienteil), 4=Cx4_PAG_5_Positions_Bedienteil (CM_GRA_Typ_Bedienteil_Cx4_PAG_5_Positions_Bedienteil), 5=Cx5_VW_MFL_Gen2 (CM_GRA_Typ_Bedienteil_Cx5_VW_MFL_Gen2), 6=Cx6_VW_MFL_Gen3 (CM_GRA_Typ_Bedienteil_Cx6_VW_MFL_Gen3), 7=Cx7_PAG_DX1_Bedienteil (CM_GRA_Typ_Bedienteil_Cx7_PAG_DX1_Bedienteil)}, range raw 0..7, transfer-property=PENDING  # Das Signal kennzeichnet die Variante des GRA/ACC-Bedienteils: 0: Init 1: 4-Positionen-Bedienteil (z.B. GRA im Blinkerhebel) 2: 6-Positionen-Bedienteil (GRA/ACC-Bedienteil mit separaten Stellungen für Set/Resume/TipUp/TipDown) 3: 8-Positionen-Bedienteil: wie 6-Positionen-Bedienteil, jedoch mit zweistufiger TipUp- und TipDown-Position 4: Porsche 5-Positionen Bedienteil (ohne Setzen-Taste) 5: VW MFL Generation 2 6: VW MFL Generation 3 (zweistufige Geschwindigkeitsverstellung) 7: Porsche DX1.0 Bedienteil (GRA/ACC-Bedienteil ohne separate Set-Taste, ohne Hauptschalter, mit zweistufige TipUp-/TipDown-Position)
          signal GRA_TravelAssist_XIX_GRA_ACC_01_XIX_E3V_K2CANFD: start 30, 1 bit, little-endian, data-type-policy=OVERRIDE, i-signal-type=PRIMITIVE, init-value=0, base-type=BT_GRA_TravelAssist, compu {0=Cx0_nicht_betaetigt (CM_GRA_TravelAssist_Cx0_nicht_betaetigt), 1=Cx1_betaetigt (CM_GRA_TravelAssist_Cx1_betaetigt)}, range raw 0..1, transfer-property=PENDING  # Taste für TravelAssist
          signal GRA_PIT_Limiter_XIX_GRA_ACC_01_XIX_E3V_K2CANFD: start 31, 1 bit, little-endian, data-type-policy=OVERRIDE, i-signal-type=PRIMITIVE, init-value=0, base-type=BT_GRA_PIT_Limiter, compu {0=Cx0_nicht_betaetigt (CM_GRA_PIT_Limiter_Cx0_nicht_betaetigt), 1=Cx1_betaetigt (CM_GRA_PIT_Limiter_Cx1_betaetigt)}, range raw 0..1, transfer-property=PENDING  # Stellung der Taste PIT-Speed-Limiter
          signal GRA_Typ_Bedienteil_erw_XIX_GRA_ACC_01_XIX_E3V_K2CANFD: start 32, 3 bit, little-endian, data-type-policy=OVERRIDE, i-signal-type=PRIMITIVE, init-value=0, base-type=BT_GRA_Typ_Bedienteil_erw, compu {0=Cx0_Init (CM_GRA_Typ_Bedienteil_erw_Cx0_Init), 1=Cx1_MFL_KIS (CM_GRA_Typ_Bedienteil_erw_Cx1_MFL_KIS), 2=Cx2_MFL_KIS_USA (CM_GRA_Typ_Bedienteil_erw_Cx2_MFL_KIS_USA)}, range raw 0..2, transfer-property=PENDING  # Das Signal kennzeichnet die Variante des GRA/ACC-Bedienteils als erweiterte Bedienvariante: "KIS" (Kip IT Simple) Zusätzlich zu dem Signal "GRA_Typ_Bedienteil"
          signal GRA_reserveByte5_3_XIX_GRA_ACC_01_XIX_E3V_K2CANFD: start 35, 5 bit, little-endian, data-type-policy=OVERRIDE, i-signal-type=PRIMITIVE, init-value=0, base-type=BT_GRA_reserveByte5_3, transfer-property=PENDING  # Zweck: Befüllen der reservierten Bitpositionen mit 0 (wg. LIN-Teilnehmer MFL)
          signal GRA_reserveByte6_XIX_GRA_ACC_01_XIX_E3V_K2CANFD: start 40, 8 bit, little-endian, data-type-policy=OVERRIDE, i-signal-type=PRIMITIVE, init-value=0, base-type=BT_GRA_reserveByte6, transfer-property=PENDING  # Zweck: Befüllen der reservierten Bitpositionen mit 0 (wg. LIN-Teilnehmer MFL)
          signal GRA_reserveByte7_XIX_GRA_ACC_01_XIX_E3V_K2CANFD: start 48, 8 bit, little-endian, data-type-policy=OVERRIDE, i-signal-type=PRIMITIVE, init-value=0, base-type=BT_GRA_reserveByte7, transfer-property=PENDING  # Zweck: Befüllen der reservierten Bitpositionen mit 0 (wg. LIN-Teilnehmer MFL)
          signal GRA_reserveByte8_XIX_GRA_ACC_01_XIX_E3V_K2CANFD: start 56, 8 bit, little-endian, data-type-policy=OVERRIDE, i-signal-type=PRIMITIVE, init-value=0, base-type=BT_GRA_reserveByte8, transfer-property=PENDING  # Zweck: Befüllen der reservierten Bitpositionen mit 0 (wg. LIN-Teilnehmer MFL)
      frame HLR_02_XIX_E3V_K2CANFD: id 0x3F8, to SAM, frame-length=8, can-addressing-mode=STANDARD, can-frame-rx-behavior=CAN-FD, can-frame-tx-behavior=CAN-FD
        pdu HLR_02_XIX_E3V_K2CANFD: length=8, minimum-delay=0.05, transmission-mode-true-timing={cyclic-timing={time-offset=0.07, time-period=0.5}, event-controlled-timing={number-of-repetitions=0, repetition-period=0.0}}, unused-bit-pattern=0  # Heizleistungsregelung MLBevo (NVEM im Gateway)
          signal HLR_FlHz_Freigabe_Ruhesitz_XIX_HLR_02_XIX_E3V_K2CANFD: start 14, 2 bit, little-endian, data-type-policy=OVERRIDE, i-signal-type=PRIMITIVE, init-value=0, base-type=BT_HLR_FlHz_Freigabe_Ruhesitz, compu {0=Cx0_0_Prozent (CM_HLR_FlHz_Freigabe_Ruhesitz_Cx0_0_Prozent), 1=Cx1_33_Prozent (CM_HLR_FlHz_Freigabe_Ruhesitz_Cx1_33_Prozent), 2=Cx2_66_Prozent (CM_HLR_FlHz_Freigabe_Ruhesitz_Cx2_66_Prozent), 3=Cx3_100_Prozent (CM_HLR_FlHz_Freigabe_Ruhesitz_Cx3_100_Prozent)}, range raw 0..3, transfer-property=TRIGGERED-ON-CHANGE-WITHOUT-REPETITION  # Freigabe des NVEM für die Flächenheizung des Ruhesitzes
          signal HLR_FlHz_Freigabe_VR_XIX_HLR_02_XIX_E3V_K2CANFD: start 16, 2 bit, little-endian, data-type-policy=OVERRIDE, i-signal-type=PRIMITIVE, init-value=0, base-type=BT_HLR_FlHz_Freigabe_VR, compu {0=Cx0_0_Prozent (CM_HLR_FlHz_Freigabe_VR_Cx0_0_Prozent), 1=Cx1_33_Prozent (CM_HLR_FlHz_Freigabe_VR_Cx1_33_Prozent), 2=Cx2_66_Prozent (CM_HLR_FlHz_Freigabe_VR_Cx2_66_Prozent), 3=Cx3_100_Prozent (CM_HLR_FlHz_Freigabe_VR_Cx3_100_Prozent)}, range raw 0..3, transfer-property=TRIGGERED-ON-CHANGE-WITHOUT-REPETITION  # Freigabe des NVEM für die Flächenheizung vorne rechts
          signal HLR_FlHz_Freigabe_VL_XIX_HLR_02_XIX_E3V_K2CANFD: start 18, 2 bit, little-endian, data-type-policy=OVERRIDE, i-signal-type=PRIMITIVE, init-value=0, base-type=BT_HLR_FlHz_Freigabe_VL, compu {0=Cx0_0_Prozent (CM_HLR_FlHz_Freigabe_VL_Cx0_0_Prozent), 1=Cx1_33_Prozent (CM_HLR_FlHz_Freigabe_VL_Cx1_33_Prozent), 2=Cx2_66_Prozent (CM_HLR_FlHz_Freigabe_VL_Cx2_66_Prozent), 3=Cx3_100_Prozent (CM_HLR_FlHz_Freigabe_VL_Cx3_100_Prozent)}, range raw 0..3, transfer-property=TRIGGERED-ON-CHANGE-WITHOUT-REPETITION  # Freigabe des NVEM für die Flächenheizung vorne links
          signal HLR_FlHz_Freigabe_HR_XIX_HLR_02_XIX_E3V_K2CANFD: start 20, 2 bit, little-endian, data-type-policy=OVERRIDE, i-signal-type=PRIMITIVE, init-value=0, base-type=BT_HLR_FlHz_Freigabe_HR, compu {0=Cx0_0_Prozent (CM_HLR_FlHz_Freigabe_HR_Cx0_0_Prozent), 1=Cx1_33_Prozent (CM_HLR_FlHz_Freigabe_HR_Cx1_33_Prozent), 2=Cx2_66_Prozent (CM_HLR_FlHz_Freigabe_HR_Cx2_66_Prozent), 3=Cx3_100_Prozent (CM_HLR_FlHz_Freigabe_HR_Cx3_100_Prozent)}, range raw 0..3, transfer-property=TRIGGERED-ON-CHANGE-WITHOUT-REPETITION  # Freigabe des NVEM für die Flächenheizung hinten rechts
          signal HLR_FlHz_Freigabe_HL_XIX_HLR_02_XIX_E3V_K2CANFD: start 22, 2 bit, little-endian, data-type-policy=OVERRIDE, i-signal-type=PRIMITIVE, init-value=0, base-type=BT_HLR_FlHz_Freigabe_HL, compu {0=Cx0_0_Prozent (CM_HLR_FlHz_Freigabe_HL_Cx0_0_Prozent), 1=Cx1_33_Prozent (CM_HLR_FlHz_Freigabe_HL_Cx1_33_Prozent), 2=Cx2_66_Prozent (CM_HLR_FlHz_Freigabe_HL_Cx2_66_Prozent), 3=Cx3_100_Prozent (CM_HLR_FlHz_Freigabe_HL_Cx3_100_Prozent)}, range raw 0..3, transfer-property=TRIGGERED-ON-CHANGE-WITHOUT-REPETITION  # Freigabe des NVEM für die Flächenheizung hinten links
          signal HLR_TCH_Freigabe_XIX_HLR_02_XIX_E3V_K2CANFD: start 24, 1 bit, little-endian, data-type-policy=OVERRIDE, i-signal-type=PRIMITIVE, init-value=0, base-type=BT_HLR_TCH_Freigabe, compu {0=Cx0_keine_Freigabe (CM_HLR_TCH_Freigabe_Cx0_keine_Freigabe), 1=Cx1_Freigabe (CM_HLR_TCH_Freigabe_Cx1_Freigabe)}, range raw 0..1, transfer-property=TRIGGERED-ON-CHANGE-WITHOUT-REPETITION  # Freigabe des NVEM für den Thermocupholder
          signal HLR_SIH_Freigabe_Fond_XIX_HLR_02_XIX_E3V_K2CANFD: start 25, 1 bit, little-endian, data-type-policy=OVERRIDE, i-signal-type=PRIMITIVE, init-value=0, base-type=BT_HLR_SIH_Freigabe_Fond, compu {0=Cx0_keine_Freigabe (CM_HLR_SIH_Freigabe_Fond_Cx0_keine_Freigabe), 1=Cx1_Freigabe (CM_HLR_SIH_Freigabe_Fond_Cx1_Freigabe)}, range raw 0..1, transfer-property=TRIGGERED-ON-CHANGE-WITHOUT-REPETITION  # Freigabe des EM für Sitzheizungen hinten
          signal HLR_Sp_Heizung_Freigabe_BT_XIX_HLR_02_XIX_E3V_K2CANFD: start 26, 1 bit, little-endian, data-type-policy=OVERRIDE, i-signal-type=PRIMITIVE, init-value=0, base-type=BT_HLR_Sp_Heizung_Freigabe_BT, compu {0=Cx0_keine_Freigabe (CM_HLR_Sp_Heizung_Freigabe_BT_Cx0_keine_Freigabe), 1=Cx1_Freigabe (CM_HLR_Sp_Heizung_Freigabe_BT_Cx1_Freigabe)}, range raw 0..1, transfer-property=TRIGGERED-ON-CHANGE-WITHOUT-REPETITION  # Freigabe der Außenspiegelheizung Beifahrerseite
          signal HLR_Sp_Heizung_Freigabe_FT_XIX_HLR_02_XIX_E3V_K2CANFD: start 27, 1 bit, little-endian, data-type-policy=OVERRIDE, i-signal-type=PRIMITIVE, init-value=0, base-type=BT_HLR_Sp_Heizung_Freigabe_FT, compu {0=Cx0_keine_Freigabe (CM_HLR_Sp_Heizung_Freigabe_FT_Cx0_keine_Freigabe), 1=Cx1_Freigabe (CM_HLR_Sp_Heizung_Freigabe_FT_Cx1_Freigabe)}, range raw 0..1, transfer-property=TRIGGERED-ON-CHANGE-WITHOUT-REPETITION  # Freigabe des EEM für die Außenspiegelheizung rechtsFreigabe der Außenspiegelheizung Fahrerseite
          signal HLR_KRH_Freigabe_VL_XIX_HLR_02_XIX_E3V_K2CANFD: start 28, 2 bit, little-endian, data-type-policy=OVERRIDE, i-signal-type=PRIMITIVE, init-value=0, base-type=BT_HLR_KRH_Freigabe_VL, compu {0=Cx0_0_Prozent (CM_HLR_KRH_Freigabe_VL_Cx0_0_Prozent), 1=Cx1_33_Prozent (CM_HLR_KRH_Freigabe_VL_Cx1_33_Prozent), 2=Cx2_66_Prozent (CM_HLR_KRH_Freigabe_VL_Cx2_66_Prozent), 3=Cx3_100_Prozent (CM_HLR_KRH_Freigabe_VL_Cx3_100_Prozent)}, range raw 0..3, transfer-property=TRIGGERED-ON-CHANGE-WITHOUT-REPETITION  # Freigabe des EEM für die Kopfraumheizung vorne links
          signal HLR_KRH_Freigabe_VR_XIX_HLR_02_XIX_E3V_K2CANFD: start 30, 2 bit, little-endian, data-type-policy=OVERRIDE, i-signal-type=PRIMITIVE, init-value=0, base-type=BT_HLR_KRH_Freigabe_VR, compu {0=Cx0_0_Prozent (CM_HLR_KRH_Freigabe_VR_Cx0_0_Prozent), 1=Cx1_33_Prozent (CM_HLR_KRH_Freigabe_VR_Cx1_33_Prozent), 2=Cx2_66_Prozent (CM_HLR_KRH_Freigabe_VR_Cx2_66_Prozent), 3=Cx3_100_Prozent (CM_HLR_KRH_Freigabe_VR_Cx3_100_Prozent)}, range raw 0..3, transfer-property=TRIGGERED-ON-CHANGE-WITHOUT-REPETITION  # Freigabe des EEM für die Kopfraumheizung vorne rechts
          signal HLR_SIH_Freigabe_VL_XIX_HLR_02_XIX_E3V_K2CANFD: start 32, 2 bit, little-endian, data-type-policy=OVERRIDE, i-signal-type=PRIMITIVE, init-value=0, base-type=BT_HLR_SIH_Freigabe_VL, compu {0=Cx0_0_Prozent (CM_HLR_SIH_Freigabe_VL_Cx0_0_Prozent), 1=Cx1_33_Prozent (CM_HLR_SIH_Freigabe_VL_Cx1_33_Prozent), 2=Cx2_66_Prozent (CM_HLR_SIH_Freigabe_VL_Cx2_66_Prozent), 3=Cx3_100_Prozent (CM_HLR_SIH_Freigabe_VL_Cx3_100_Prozent)}, range raw 0..3, transfer-property=TRIGGERED-ON-CHANGE-WITHOUT-REPETITION  # Freigabe des EEM für die Sitzheizung vorne links
          signal HLR_SIH_Freigabe_VR_XIX_HLR_02_XIX_E3V_K2CANFD: start 34, 2 bit, little-endian, data-type-policy=OVERRIDE, i-signal-type=PRIMITIVE, init-value=0, base-type=BT_HLR_SIH_Freigabe_VR, compu {0=Cx0_0_Prozent (CM_HLR_SIH_Freigabe_VR_Cx0_0_Prozent), 1=Cx1_33_Prozent (CM_HLR_SIH_Freigabe_VR_Cx1_33_Prozent), 2=Cx2_66_Prozent (CM_HLR_SIH_Freigabe_VR_Cx2_66_Prozent), 3=Cx3_100_Prozent (CM_HLR_SIH_Freigabe_VR_Cx3_100_Prozent)}, range raw 0..3, transfer-property=TRIGGERED-ON-CHANGE-WITHOUT-REPETITION  # Freigabe des EEM für die Sitzheizung vorne rechts
          signal HLR_SIH_Freigabe_HL_XIX_HLR_02_XIX_E3V_K2CANFD: start 36, 2 bit, little-endian, data-type-policy=OVERRIDE, i-signal-type=PRIMITIVE, init-value=0, base-type=BT_HLR_SIH_Freigabe_HL, compu {0=Cx0_0_Prozent (CM_HLR_SIH_Freigabe_HL_Cx0_0_Prozent), 1=Cx1_33_Prozent (CM_HLR_SIH_Freigabe_HL_Cx1_33_Prozent), 2=Cx2_66_Prozent (CM_HLR_SIH_Freigabe_HL_Cx2_66_Prozent), 3=Cx3_100_Prozent (CM_HLR_SIH_Freigabe_HL_Cx3_100_Prozent)}, range raw 0..3, transfer-property=TRIGGERED-ON-CHANGE-WITHOUT-REPETITION  # Freigabe des EEM für die Sitzheizung hinten links
          signal HLR_SIH_Freigabe_HR_XIX_HLR_02_XIX_E3V_K2CANFD: start 38, 2 bit, little-endian, data-type-policy=OVERRIDE, i-signal-type=PRIMITIVE, init-value=0, base-type=BT_HLR_SIH_Freigabe_HR, compu {0=Cx0_0_Prozent (CM_HLR_SIH_Freigabe_HR_Cx0_0_Prozent), 1=Cx1_33_Prozent (CM_HLR_SIH_Freigabe_HR_Cx1_33_Prozent), 2=Cx2_66_Prozent (CM_HLR_SIH_Freigabe_HR_Cx2_66_Prozent), 3=Cx3_100_Prozent (CM_HLR_SIH_Freigabe_HR_Cx3_100_Prozent)}, range raw 0..3, transfer-property=TRIGGERED-ON-CHANGE-WITHOUT-REPETITION  # Freigabe des EEM für die Sitzheizung hinten rechts
          signal HLR_SIL_Freigabe_VL_XIX_HLR_02_XIX_E3V_K2CANFD: start 40, 2 bit, little-endian, data-type-policy=OVERRIDE, i-signal-type=PRIMITIVE, init-value=0, base-type=BT_HLR_SIL_Freigabe_VL, compu {0=Cx0_0_Prozent (CM_HLR_SIL_Freigabe_VL_Cx0_0_Prozent), 1=Cx1_33_Prozent (CM_HLR_SIL_Freigabe_VL_Cx1_33_Prozent), 2=Cx2_66_Prozent (CM_HLR_SIL_Freigabe_VL_Cx2_66_Prozent), 3=Cx3_100_Prozent (CM_HLR_SIL_Freigabe_VL_Cx3_100_Prozent)}, range raw 0..3, transfer-property=TRIGGERED-ON-CHANGE-WITHOUT-REPETITION  # Freigabe des EEM für die Sitzlüftung Vorne Links
          signal HLR_SIL_Freigabe_VR_XIX_HLR_02_XIX_E3V_K2CANFD: start 42, 2 bit, little-endian, data-type-policy=OVERRIDE, i-signal-type=PRIMITIVE, init-value=0, base-type=BT_HLR_SIL_Freigabe_VR, compu {0=Cx0_0_Prozent (CM_HLR_SIL_Freigabe_VR_Cx0_0_Prozent), 1=Cx1_33_Prozent (CM_HLR_SIL_Freigabe_VR_Cx1_33_Prozent), 2=Cx2_66_Prozent (CM_HLR_SIL_Freigabe_VR_Cx2_66_Prozent), 3=Cx3_100_Prozent (CM_HLR_SIL_Freigabe_VR_Cx3_100_Prozent)}, range raw 0..3, transfer-property=TRIGGERED-ON-CHANGE-WITHOUT-REPETITION  # Freigabe des EEM für die Sitzlüftung vorne Rechts
          signal HLR_SIL_Freigabe_HL_XIX_HLR_02_XIX_E3V_K2CANFD: start 44, 2 bit, little-endian, data-type-policy=OVERRIDE, i-signal-type=PRIMITIVE, init-value=0, base-type=BT_HLR_SIL_Freigabe_HL, compu {0=Cx0_0_Prozent (CM_HLR_SIL_Freigabe_HL_Cx0_0_Prozent), 1=Cx1_33_Prozent (CM_HLR_SIL_Freigabe_HL_Cx1_33_Prozent), 2=Cx2_66_Prozent (CM_HLR_SIL_Freigabe_HL_Cx2_66_Prozent), 3=Cx3_100_Prozent (CM_HLR_SIL_Freigabe_HL_Cx3_100_Prozent)}, range raw 0..3, transfer-property=TRIGGERED-ON-CHANGE-WITHOUT-REPETITION  # Freigabe des EEM für die Sitzbelüftung hinten links
          signal HLR_SIL_Freigabe_HR_XIX_HLR_02_XIX_E3V_K2CANFD: start 46, 2 bit, little-endian, data-type-policy=OVERRIDE, i-signal-type=PRIMITIVE, init-value=0, base-type=BT_HLR_SIL_Freigabe_HR, compu {0=Cx0_0_Prozent (CM_HLR_SIL_Freigabe_HR_Cx0_0_Prozent), 1=Cx1_33_Prozent (CM_HLR_SIL_Freigabe_HR_Cx1_33_Prozent), 2=Cx2_66_Prozent (CM_HLR_SIL_Freigabe_HR_Cx2_66_Prozent), 3=Cx3_100_Prozent (CM_HLR_SIL_Freigabe_HR_Cx3_100_Prozent)}, range raw 0..3, transfer-property=TRIGGERED-ON-CHANGE-WITHOUT-REPETITION  # Freigabe des EEM für die Sitzlüftung hinten rechts
          signal HLR_FSH_Freigabe_XIX_HLR_02_XIX_E3V_K2CANFD: start 48, 6 bit, little-endian, data-type-policy=OVERRIDE, i-signal-type=PRIMITIVE, init-value=0, base-type=BT_HLR_FSH_Freigabe, invalid-value=Invalid_HLR_FSH_Freigabe_XIX_HLR_02_XIX_E3V_K2CANFD:63, compu {0=Cx0_AUS (CM_HLR_FSH_Freigabe_Cx0_AUS), phys=raw*20 for raw 1..62, 63=Cx3f_Fehler (CM_HLR_FSH_Freigabe_Cx3f_Fehler); unit Unit_Watt}, range phys 20..1240 Unit_Watt, raw 0..63, unit=Unit_Watt, transfer-property=TRIGGERED-ON-CHANGE-WITHOUT-REPETITION  # Freigabe des EEM für die Frontscheibenheizung
          signal HLR_HSH_Freigabe_XIX_HLR_02_XIX_E3V_K2CANFD: start 54, 1 bit, little-endian, data-type-policy=OVERRIDE, i-signal-type=PRIMITIVE, init-value=0, base-type=BT_HLR_HSH_Freigabe, compu {0=Cx0_keine_Freigabe (CM_HLR_HSH_Freigabe_Cx0_keine_Freigabe), 1=Cx1_Freigabe (CM_HLR_HSH_Freigabe_Cx1_Freigabe)}, range raw 0..1, transfer-property=TRIGGERED-ON-CHANGE-WITHOUT-REPETITION  # Freigabe des EEM für die Heckscheibenheizung
          signal HLR_LRH_Freigabe_XIX_HLR_02_XIX_E3V_K2CANFD: start 55, 1 bit, little-endian, data-type-policy=OVERRIDE, i-signal-type=PRIMITIVE, init-value=0, base-type=BT_HLR_LRH_Freigabe, compu {0=Cx0_keine_Freigabe (CM_HLR_LRH_Freigabe_Cx0_keine_Freigabe), 1=Cx1_Freigabe (CM_HLR_LRH_Freigabe_Cx1_Freigabe)}, range raw 0..1, transfer-property=TRIGGERED-ON-CHANGE-WITHOUT-REPETITION, to SAM(timeout 5 s)  # Freigabe für die Lenkradheizung
          signal HLR_PTC_linear_Freigabe_XIX_HLR_02_XIX_E3V_K2CANFD: start 56, 6 bit, little-endian, data-type-policy=OVERRIDE, i-signal-type=PRIMITIVE, init-value=0, base-type=BT_HLR_PTC_linear_Freigabe, invalid-value=Invalid_HLR_PTC_linear_Freigabe_XIX_HLR_02_XIX_E3V_K2CANFD:63, compu {phys=raw*50 for raw 0..62, 63=Cx3f_Fehler (CM_HLR_PTC_linear_Freigabe_Cx3f_Fehler); unit Unit_Watt}, range phys 0..3100 Unit_Watt, raw 0..63, unit=Unit_Watt, transfer-property=TRIGGERED-ON-CHANGE-WITHOUT-REPETITION  # Freigabe des EEM für den linearen PTC-Zuheizer
          signal HLR_PTC_Freigabe_XIX_HLR_02_XIX_E3V_K2CANFD: start 62, 2 bit, little-endian, data-type-policy=OVERRIDE, i-signal-type=PRIMITIVE, init-value=3, base-type=BT_HLR_PTC_Freigabe, compu {0=Cx0_Aus (CM_HLR_PTC_Freigabe_Cx0_Aus), 1=Cx1_Stufe_1 (CM_HLR_PTC_Freigabe_Cx1_Stufe_1), 2=Cx2_Stufe_2 (CM_HLR_PTC_Freigabe_Cx2_Stufe_2), 3=Cx3_Stufe_3 (CM_HLR_PTC_Freigabe_Cx3_Stufe_3)}, range raw 0..3, transfer-property=TRIGGERED-ON-CHANGE-WITHOUT-REPETITION  # Freigabe des elektrischen Energiemanagements für das gestufte/geregelte PTC
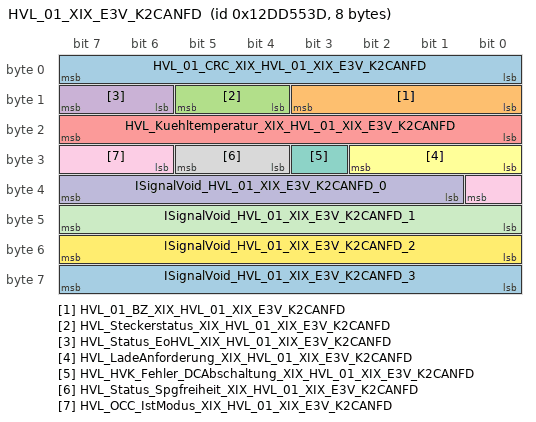
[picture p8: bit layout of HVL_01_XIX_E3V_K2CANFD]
      frame HVL_01_XIX_E3V_K2CANFD: id 0x12DD553D, to SAM, frame-length=8, can-addressing-mode=EXTENDED, can-frame-rx-behavior=CAN-FD, can-frame-tx-behavior=CAN-FD
        pdu HVL_01_XIX_E3V_K2CANFD_E2E: length=8, minimum-delay=0.01, transmission-mode-true-timing=event-controlled-timing={number-of-repetitions=0, repetition-period=0.0}, unused-bit-pattern=0  # Fuer die Botschaft ist das Cyclic-Timing 0.1 zu verwenden.
          signal HVL_01_CRC_XIX_HVL_01_XIX_E3V_K2CANFD: start 0, 8 bit, little-endian, data-type-policy=OVERRIDE, i-signal-type=PRIMITIVE, base-type=BT_HVL_01_CRC, compu {phys=raw for raw 0..255}, range phys 0..255, raw 0..255, to SAM(timeout 1 s)  # Für MLB: Berechnung siehe Lastenheft "Kommunikationsabsicherung für FlexRay und CAN" Ab MQB und MLBevo: Berechnung siehe Lastenheft "End-to-End Kommunikationsabsicherung" Endwerte siehe Begleitdokument "S-PDU Kennungsfolgen"
          signal HVL_01_BZ_XIX_HVL_01_XIX_E3V_K2CANFD: start 8, 4 bit, little-endian, data-type-policy=OVERRIDE, i-signal-type=PRIMITIVE, base-type=BT_HVL_01_BZ, compu {phys=raw for raw 0..15}, range phys 0..15, raw 0..15, to SAM(timeout 1 s)  # 4bit Botschaftszähler, wird mit jeder Sendebotschaft inkrementiert
          signal HVL_Steckerstatus_XIX_HVL_01_XIX_E3V_K2CANFD: start 12, 2 bit, little-endian, data-type-policy=OVERRIDE, i-signal-type=PRIMITIVE, init-value=0, base-type=BT_HVL_Steckerstatus, invalid-value=Invalid_HVL_Steckerstatus_XIX_HVL_01_XIX_E3V_K2CANFD:3, compu {0=Cx0_Init (CM_HVL_Steckerstatus_Cx0_Init), 1=Cx1_kein_Stecker_erkannt (CM_HVL_Steckerstatus_Cx1_kein_Stecker_erkannt), 2=Cx2_Stecker_erkannt (CM_HVL_Steckerstatus_Cx2_Stecker_erkannt), 3=Cx3_Fehler (CM_HVL_Steckerstatus_Cx3_Fehler)}, range raw 0..3, to SAM(timeout 1 s)  # Stellt den Status des Ladesteckers hinsichtlich Präsenz zur Verfügung
          signal HVL_Status_EoHVL_XIX_HVL_01_XIX_E3V_K2CANFD: start 14, 2 bit, little-endian, data-type-policy=OVERRIDE, i-signal-type=PRIMITIVE, init-value=0, base-type=BT_HVL_Status_EoHVL, invalid-value=Invalid_HVL_Status_EoHVL_XIX_HVL_01_XIX_E3V_K2CANFD:3, compu {0=Cx0_Init (CM_HVL_Status_EoHVL_Cx0_Init), 1=Cx1_Keine_offene_HV_Leitung_erkannt (CM_HVL_Status_EoHVL_Cx1_Keine_offene_HV_Leitung_erkannt), 2=Cx2_offene_HV_Leitung_erkannt (CM_HVL_Status_EoHVL_Cx2_offene_HV_Leitung_erkannt), 3=Cx3_Fehler (CM_HVL_Status_EoHVL_Cx3_Fehler)}, range raw 0..3  # Erkennung einer offenen HV-Leitung (EoHVL), bewertet anhand einer Spannungsgrenze
          signal HVL_Kuehltemperatur_XIX_HVL_01_XIX_E3V_K2CANFD: start 16, 8 bit, little-endian, data-type-policy=OVERRIDE, i-signal-type=PRIMITIVE, init-value=254, base-type=BT_HVL_Kuehltemperatur, invalid-value=Invalid_HVL_Kuehltemperatur_XIX_HVL_01_XIX_E3V_K2CANFD:255, compu {phys=raw-40 for raw 0..253, 254=Cxfe_Init (CM_HVL_Kuehltemperatur_Cxfe_Init), 255=Cxff_Fehler (CM_HVL_Kuehltemperatur_Cxff_Fehler); unit Unit_DegreCelsi}, range phys -40..213 Unit_DegreCelsi, raw 0..255, unit=Unit_DegreCelsi  # Istwert der OCC-Kühlkanaltemperatur
          signal HVL_LadeAnforderung_XIX_HVL_01_XIX_E3V_K2CANFD: start 24, 3 bit, little-endian, data-type-policy=OVERRIDE, i-signal-type=PRIMITIVE, init-value=0, base-type=BT_HVL_LadeAnforderung, compu {0=Cx0_Laden_nicht_angefordert (CM_HVL_LadeAnforderung_Cx0_Laden_nicht_angefordert), 1=Cx1_AC_Laden_Angefordert (CM_HVL_LadeAnforderung_Cx1_AC_Laden_Angefordert), 2=Cx2_DC_Laden_Angefordert (CM_HVL_LadeAnforderung_Cx2_DC_Laden_Angefordert), 3=Cx3_AC_und_DC_Angefordert (CM_HVL_LadeAnforderung_Cx3_AC_und_DC_Angefordert), 4=Cx4_Induktiv_Laden_Angef (CM_HVL_LadeAnforderung_Cx4_Induktiv_Laden_Angef), 5=Cx5_AC_und_Induktiv_Angef (CM_HVL_LadeAnforderung_Cx5_AC_und_Induktiv_Angef), 6=Cx6_DC_und_Induktiv_Angef (CM_HVL_LadeAnforderung_Cx6_DC_und_Induktiv_Angef), 7=Cx7_AC_DC_und_Induktiv_Angef (CM_HVL_LadeAnforderung_Cx7_AC_DC_und_Induktiv_Angef)}, range raw 0..7  # FuSi-Abgesicherte Ladeanforderung an den HVK
          signal HVL_HVK_Fehler_DCAbschaltung_XIX_HVL_01_XIX_E3V_K2CANFD: start 27, 1 bit, little-endian, data-type-policy=OVERRIDE, i-signal-type=PRIMITIVE, init-value=0, base-type=BT_HVL_HVK_Fehler_DCAbschaltung, compu {0=Cx0_keine_Anforderung_Init (CM_HVL_HVK_Fehler_DCAbschaltung_Cx0_keine_Anforderung_Init), 1=Cx1_Anforderung_DC_Notabschaltung (CM_HVL_HVK_Fehler_DCAbschaltung_Cx1_Anforderung_DC_Notabschaltung)}, range raw 0..1  # Status der Anforderung einer DC-Laden-Notabschaltung
          signal HVL_Status_Spgfreiheit_XIX_HVL_01_XIX_E3V_K2CANFD: start 28, 2 bit, little-endian, data-type-policy=OVERRIDE, i-signal-type=PRIMITIVE, init-value=0, base-type=BT_HVL_Status_Spgfreiheit, invalid-value=Invalid_HVL_Status_Spgfreiheit_XIX_HVL_01_XIX_E3V_K2CANFD:3, compu {0=Cx0_Init_ohne_Funktion (CM_HVL_Status_Spgfreiheit_Cx0_Init_ohne_Funktion) (Init__ohne_Funktion), 1=Cx1_HV_Komponente_Spannungsfrei (CM_HVL_Status_Spgfreiheit_Cx1_HV_Komponente_Spannungsfrei), 2=Cx2_HV_Komponente_nichtSpannungsfrei (CM_HVL_Status_Spgfreiheit_Cx2_HV_Komponente_nichtSpannungsfrei), 3=Cx3_Fehler (CM_HVL_Status_Spgfreiheit_Cx3_Fehler)}, range raw 0..3  # Status der Spannungsfreiheit für den Onboard Charge Client
          signal HVL_OCC_IstModus_XIX_HVL_01_XIX_E3V_K2CANFD: start 30, 3 bit, little-endian, data-type-policy=OVERRIDE, i-signal-type=PRIMITIVE, init-value=6, base-type=BT_HVL_OCC_IstModus, invalid-value=Invalid_HVL_OCC_IstModus_XIX_HVL_01_XIX_E3V_K2CANFD:7, compu {0=Cx0_Standby (CM_HVL_OCC_IstModus_Cx0_Standby), 1=Cx1_Netzladung_aktiv (CM_HVL_OCC_IstModus_Cx1_Netzladung_aktiv), 2=Cx2_Rueckspeisung_aktiv (CM_HVL_OCC_IstModus_Cx2_Rueckspeisung_aktiv), 3=Cx3_reserve (CM_HVL_OCC_IstModus_Cx3_reserve), 4=Cx4_reserve (CM_HVL_OCC_IstModus_Cx4_reserve), 5=Cx5_reserve (CM_HVL_OCC_IstModus_Cx5_reserve), 6=Cx6_Init (CM_HVL_OCC_IstModus_Cx6_Init), 7=Cx7_Fehler (CM_HVL_OCC_IstModus_Cx7_Fehler)}, range raw 0..7  # aktueller Funktionszustand des OCC
          signal ISignalVoid_HVL_01_XIX_E3V_K2CANFD_0: start 33, 7 bit, little-endian, system signal SignalVoid_HVL_01_0, data-type-policy=OVERRIDE, i-signal-type=PRIMITIVE, base-type=BT_SignalVoid
          signal ISignalVoid_HVL_01_XIX_E3V_K2CANFD_1: start 40, 8 bit, little-endian, system signal SignalVoid_HVL_01_1, data-type-policy=OVERRIDE, i-signal-type=PRIMITIVE, base-type=BT_SignalVoid
          signal ISignalVoid_HVL_01_XIX_E3V_K2CANFD_2: start 48, 8 bit, little-endian, system signal SignalVoid_HVL_01_2, data-type-policy=OVERRIDE, i-signal-type=PRIMITIVE, base-type=BT_SignalVoid
          signal ISignalVoid_HVL_01_XIX_E3V_K2CANFD_3: start 56, 8 bit, little-endian, system signal SignalVoid_HVL_01_3, data-type-policy=OVERRIDE, i-signal-type=PRIMITIVE, base-type=BT_SignalVoid
          mapping SG_HVL_01_XIX_E3V_K2CANFD: i-signal-group=SG_HVL_01_XIX_E3V_K2CANFD, transfer-property=TRIGGERED-WITHOUT-REPETITION
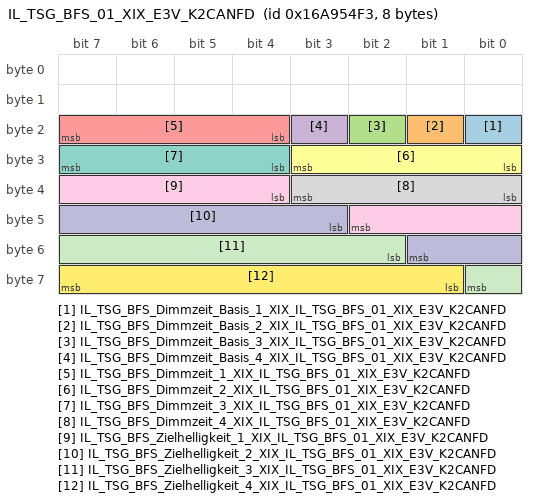
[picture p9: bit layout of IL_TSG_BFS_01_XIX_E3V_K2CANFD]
      frame IL_TSG_BFS_01_XIX_E3V_K2CANFD: id 0x16A954F3, from SAM, frame-length=8, can-addressing-mode=EXTENDED, can-frame-rx-behavior=CAN-FD, can-frame-tx-behavior=CAN-FD
        pdu IL_TSG_BFS_01_XIX_E3V_K2CANFD: length=8, minimum-delay=0.05, transmission-mode-true-timing={cyclic-timing={time-offset=0.0, time-period=0.5}, event-controlled-timing={number-of-repetitions=0, repetition-period=0.0}}, unused-bit-pattern=0
          signal IL_TSG_BFS_Dimmzeit_Basis_1_XIX_IL_TSG_BFS_01_XIX_E3V_K2CANFD: start 16, 1 bit, little-endian, data-type-policy=OVERRIDE, i-signal-type=PRIMITIVE, init-value=0, base-type=BT_IL_TSG_BFS_Dimmzeit_Basis_1, compu {0=Cx0_Zeitbasis_50ms (CM_IL_TSG_BFS_Dimmzeit_Basis_1_Cx0_Zeitbasis_50ms), 1=Cx1_Zeitbasis_250ms (CM_IL_TSG_BFS_Dimmzeit_Basis_1_Cx1_Zeitbasis_250ms)}, range raw 0..1, transfer-property=TRIGGERED-ON-CHANGE-WITHOUT-REPETITION  # Dimmzeit Zeitbasis für Lichtausgang 1 TSG BFS umschaltbar zwischen 250ms und 50ms.
          signal IL_TSG_BFS_Dimmzeit_Basis_2_XIX_IL_TSG_BFS_01_XIX_E3V_K2CANFD: start 17, 1 bit, little-endian, data-type-policy=OVERRIDE, i-signal-type=PRIMITIVE, init-value=0, base-type=BT_IL_TSG_BFS_Dimmzeit_Basis_2, compu {0=Cx0_Zeitbasis_50ms (CM_IL_TSG_BFS_Dimmzeit_Basis_2_Cx0_Zeitbasis_50ms), 1=Cx1_Zeitbasis_250ms (CM_IL_TSG_BFS_Dimmzeit_Basis_2_Cx1_Zeitbasis_250ms)}, range raw 0..1, transfer-property=TRIGGERED-ON-CHANGE-WITHOUT-REPETITION  # Dimmzeit Zeitbasis für Lichtausgang 2 TSG BFS umschaltbar zwischen 250ms und 50ms.
          signal IL_TSG_BFS_Dimmzeit_Basis_3_XIX_IL_TSG_BFS_01_XIX_E3V_K2CANFD: start 18, 1 bit, little-endian, data-type-policy=OVERRIDE, i-signal-type=PRIMITIVE, init-value=0, base-type=BT_IL_TSG_BFS_Dimmzeit_Basis_3, compu {0=Cx0_Zeitbasis_50ms (CM_IL_TSG_BFS_Dimmzeit_Basis_3_Cx0_Zeitbasis_50ms), 1=Cx1_Zeitbasis_250ms (CM_IL_TSG_BFS_Dimmzeit_Basis_3_Cx1_Zeitbasis_250ms)}, range raw 0..1, transfer-property=TRIGGERED-ON-CHANGE-WITHOUT-REPETITION  # Dimmzeit Zeitbasis für Lichtausgang 3 TSG BFS umschaltbar zwischen 250ms und 50ms.
          signal IL_TSG_BFS_Dimmzeit_Basis_4_XIX_IL_TSG_BFS_01_XIX_E3V_K2CANFD: start 19, 1 bit, little-endian, data-type-policy=OVERRIDE, i-signal-type=PRIMITIVE, init-value=0, base-type=BT_IL_TSG_BFS_Dimmzeit_Basis_4, compu {0=Cx0_Zeitbasis_50ms (CM_IL_TSG_BFS_Dimmzeit_Basis_4_Cx0_Zeitbasis_50ms), 1=Cx1_Zeitbasis_250ms (CM_IL_TSG_BFS_Dimmzeit_Basis_4_Cx1_Zeitbasis_250ms)}, range raw 0..1, transfer-property=TRIGGERED-ON-CHANGE-WITHOUT-REPETITION  # Dimmzeit Zeitbasis für Lichtausgang 4 TSG BFS umschaltbar zwischen 250ms und 50ms.
          signal IL_TSG_BFS_Dimmzeit_1_XIX_IL_TSG_BFS_01_XIX_E3V_K2CANFD: start 20, 4 bit, little-endian, data-type-policy=OVERRIDE, i-signal-type=PRIMITIVE, init-value=0, base-type=BT_IL_TSG_BFS_Dimmzeit_1, compu {phys=raw for raw 0..15; unit Unit_None}, range phys 0..15 Unit_None, raw 0..15, unit=Unit_None, transfer-property=TRIGGERED-ON-CHANGE-WITHOUT-REPETITION  # Dimmzeit für Ausgang 1 TSG BFS als Multiplikator der Dimmzeit Zeitbasis (Hinweis: Dimmzeit Zeitbasis für Ausgang 1 TSG BFS beachten)
          signal IL_TSG_BFS_Dimmzeit_2_XIX_IL_TSG_BFS_01_XIX_E3V_K2CANFD: start 24, 4 bit, little-endian, data-type-policy=OVERRIDE, i-signal-type=PRIMITIVE, init-value=0, base-type=BT_IL_TSG_BFS_Dimmzeit_2, compu {phys=raw for raw 0..15; unit Unit_None}, range phys 0..15 Unit_None, raw 0..15, unit=Unit_None, transfer-property=TRIGGERED-ON-CHANGE-WITHOUT-REPETITION  # Dimmzeit für Ausgang 2 TSG BFS als Multiplikator der Dimmzeit Zeitbasis (Hinweis: Dimmzeit Zeitbasis für Ausgang 2 TSG BFS beachten)
          signal IL_TSG_BFS_Dimmzeit_3_XIX_IL_TSG_BFS_01_XIX_E3V_K2CANFD: start 28, 4 bit, little-endian, data-type-policy=OVERRIDE, i-signal-type=PRIMITIVE, init-value=0, base-type=BT_IL_TSG_BFS_Dimmzeit_3, compu {phys=raw for raw 0..15; unit Unit_None}, range phys 0..15 Unit_None, raw 0..15, unit=Unit_None, transfer-property=TRIGGERED-ON-CHANGE-WITHOUT-REPETITION  # Dimmzeit für Ausgang 3 TSG BFS als Multiplikator der Dimmzeit Zeitbasis (Hinweis: Dimmzeit Zeitbasis für Ausgang 3 TSG BFS beachten)
          signal IL_TSG_BFS_Dimmzeit_4_XIX_IL_TSG_BFS_01_XIX_E3V_K2CANFD: start 32, 4 bit, little-endian, data-type-policy=OVERRIDE, i-signal-type=PRIMITIVE, init-value=0, base-type=BT_IL_TSG_BFS_Dimmzeit_4, compu {phys=raw for raw 0..15; unit Unit_None}, range phys 0..15 Unit_None, raw 0..15, unit=Unit_None, transfer-property=TRIGGERED-ON-CHANGE-WITHOUT-REPETITION  # Dimmzeit für Ausgang 4 TSG BFS als Multiplikator der Dimmzeit Zeitbasis (Hinweis: Dimmzeit Zeitbasis für Ausgang 4 TSG BFS beachten)
          signal IL_TSG_BFS_Zielhelligkeit_1_XIX_IL_TSG_BFS_01_XIX_E3V_K2CANFD: start 36, 7 bit, little-endian, data-type-policy=OVERRIDE, i-signal-type=PRIMITIVE, init-value=0, base-type=BT_IL_TSG_BFS_Zielhelligkeit_1, compu {phys=raw for raw 0..100; unit Unit_PerCent}, range phys 0..100 Unit_PerCent, raw 0..100, unit=Unit_PerCent, transfer-property=TRIGGERED-ON-CHANGE-WITHOUT-REPETITION  # Intensität für Ausgang 1 TSG BFS
          signal IL_TSG_BFS_Zielhelligkeit_2_XIX_IL_TSG_BFS_01_XIX_E3V_K2CANFD: start 43, 7 bit, little-endian, data-type-policy=OVERRIDE, i-signal-type=PRIMITIVE, init-value=0, base-type=BT_IL_TSG_BFS_Zielhelligkeit_2, compu {phys=raw for raw 0..100; unit Unit_PerCent}, range phys 0..100 Unit_PerCent, raw 0..100, unit=Unit_PerCent, transfer-property=TRIGGERED-ON-CHANGE-WITHOUT-REPETITION  # Intensität für Ausgang 2 TSG BFS
          signal IL_TSG_BFS_Zielhelligkeit_3_XIX_IL_TSG_BFS_01_XIX_E3V_K2CANFD: start 50, 7 bit, little-endian, data-type-policy=OVERRIDE, i-signal-type=PRIMITIVE, init-value=0, base-type=BT_IL_TSG_BFS_Zielhelligkeit_3, compu {phys=raw for raw 0..100; unit Unit_PerCent}, range phys 0..100 Unit_PerCent, raw 0..100, unit=Unit_PerCent, transfer-property=TRIGGERED-ON-CHANGE-WITHOUT-REPETITION  # Intensität für Ausgang 3 TSG BFS
          signal IL_TSG_BFS_Zielhelligkeit_4_XIX_IL_TSG_BFS_01_XIX_E3V_K2CANFD: start 57, 7 bit, little-endian, data-type-policy=OVERRIDE, i-signal-type=PRIMITIVE, init-value=0, base-type=BT_IL_TSG_BFS_Zielhelligkeit_4, compu {phys=raw for raw 0..100; unit Unit_PerCent}, range phys 0..100 Unit_PerCent, raw 0..100, unit=Unit_PerCent, transfer-property=TRIGGERED-ON-CHANGE-WITHOUT-REPETITION  # Intensität für Ausgang 4 TSG BFS
